VERSION ""

NS_ :

BS_:

BU_: AHCP APM BPCM EAC EBCM ECM ESC HCP OBCM ORC RHSC2

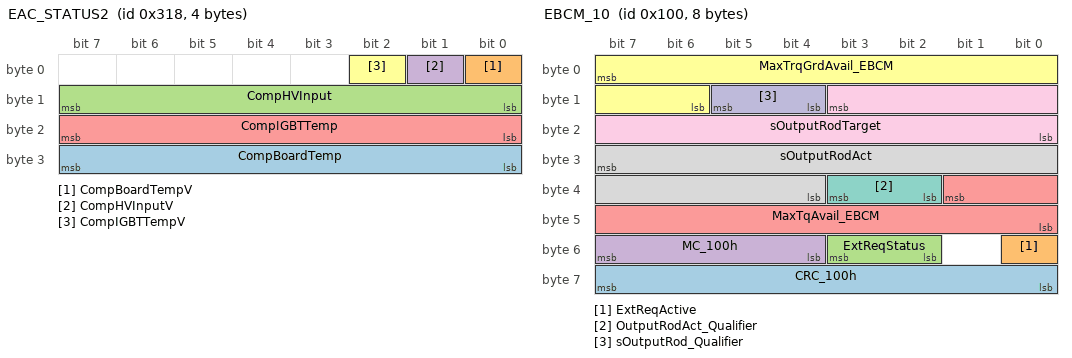
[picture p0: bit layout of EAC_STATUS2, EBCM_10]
BO_ 792 EAC_STATUS2: 4 EAC
 SG_ CompBoardTemp : 24|8@1+ (1,-40) [-40|214] "°C"  HCP
 SG_ CompBoardTempV : 0|1@1+ (1,0) [0|0] ""  HCP
 SG_ CompHVInput : 8|8@1+ (4,0) [0|1016] "Volts"  HCP
 SG_ CompHVInputV : 1|1@1+ (1,0) [0|0] ""  HCP
 SG_ CompIGBTTemp : 16|8@1+ (1,-40) [-40|214] "°C"  HCP
 SG_ CompIGBTTempV : 2|1@1+ (1,0) [0|0] ""  HCP

BO_ 256 EBCM_10: 8 EBCM
 SG_ CRC_100h : 56|8@1+ (1,0) [0|255] ""  ESC
 SG_ ExtReqActive : 48|1@1+ (1,0) [0|0] ""  ESC
 SG_ ExtReqStatus : 50|2@1+ (1,0) [0|0] ""  ESC
 SG_ MC_100h : 52|4@1+ (1,1) [1|15] ""  ESC
 SG_ MaxTqAvail_EBCM : 33|10@0+ (64,-65472) [-65472|0] ""  ESC
 SG_ MaxTrqGrdAvail_EBCM : 7|10@0+ (64,0) [0|65472] ""  ESC
 SG_ OutputRodAct_Qualifier : 34|2@1+ (1,0) [0|0] ""  ESC
 SG_ sOutputRodAct : 31|12@0+ (0.015625,-5) [-5|47] "mm"  ESC
 SG_ sOutputRodTarget : 11|12@0+ (0.015625,-5) [-5|47] "mm"  ESC
 SG_ sOutputRod_Qualifier : 12|2@1+ (1,0) [0|0] ""  ESC

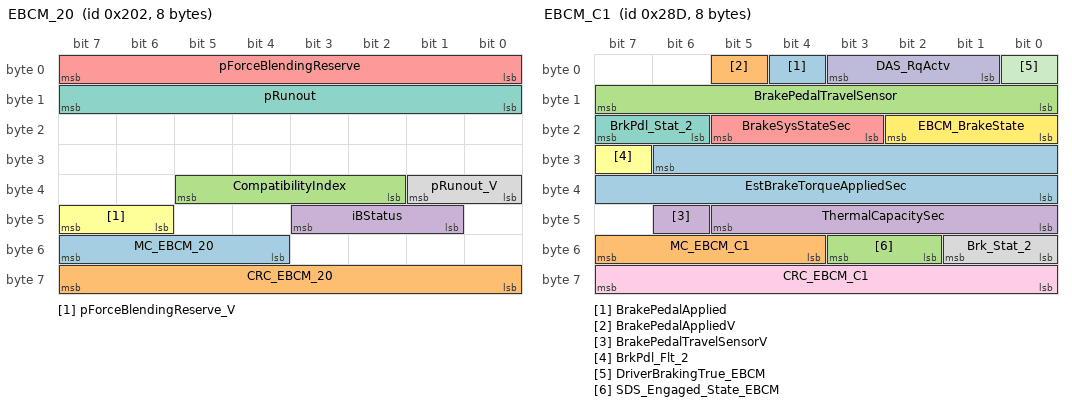
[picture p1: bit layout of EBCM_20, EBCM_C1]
BO_ 514 EBCM_20: 8 EBCM
 SG_ MC_EBCM_20 : 52|4@1+ (1,0) [0|15] ""  ESC
 SG_ CRC_EBCM_20 : 56|8@1+ (1,0) [0|255] ""  ESC
 SG_ CompatibilityIndex : 34|4@1+ (1,0) [0|0] ""  ESC
 SG_ iBStatus : 41|3@1+ (1,0) [0|0] ""  ESC
 SG_ pForceBlendingReserve : 0|8@1+ (0.5,0) [0|100] "bar"  ESC
 SG_ pForceBlendingReserve_V : 46|2@1+ (1,0) [0|0] ""  ESC
 SG_ pRunout : 8|8@1+ (1,0) [0|250] "bar"  ESC
 SG_ pRunout_V : 32|2@1+ (1,0) [0|0] ""  ESC

BO_ 653 EBCM_C1: 8 EBCM
 SG_ BrakePedalApplied : 4|1@1+ (1,0) [0|0] ""  RHSC2
 SG_ BrakePedalAppliedV : 5|1@1+ (1,0) [0|0] ""  RHSC2
 SG_ BrakePedalTravelSensor : 8|8@1+ (0.4,0) [0|100] "%"  RHSC2
 SG_ BrakePedalTravelSensorV : 46|1@1+ (1,0) [0|0] ""  RHSC2
 SG_ BrakeSysStateSec : 19|3@1+ (1,0) [0|0] ""  ESC,RHSC2
 SG_ BrkPdl_Flt_2 : 31|1@1+ (1,0) [0|0] ""  RHSC2
 SG_ BrkPdl_Stat_2 : 22|2@1+ (1,0) [0|0] ""  RHSC2
 SG_ Brk_Stat_2 : 48|2@1+ (1,0) [0|0] ""  RHSC2
 SG_ CRC_EBCM_C1 : 56|8@1+ (1,0) [0|0] ""  ESC,RHSC2
 SG_ DAS_RqActv : 1|3@1+ (1,0) [0|0] ""  RHSC2
 SG_ DriverBrakingTrue_EBCM : 0|1@1+ (1,0) [0|0] ""  ESC,RHSC2
 SG_ EBCM_BrakeState : 16|3@1+ (1,0) [0|0] ""  ESC,RHSC2
 SG_ EstBrakeTorqueAppliedSec : 30|15@0+ (2,-65534) [-65534|0] "Nm"  RHSC2
 SG_ MC_EBCM_C1 : 52|4@1+ (1,0) [0|15] ""  ESC,RHSC2
 SG_ SDS_Engaged_State_EBCM : 50|2@1+ (1,0) [0|0] ""  RHSC2
 SG_ ThermalCapacitySec : 40|6@1+ (1.5873,0) [0|100] "%"  RHSC2

BO_ 257 ECM_OBD_ePT: 3 ECM
 SG_ AccelPdlPosn_OBD_ePT : 16|8@1+ (0.3922,0) [0|100] "%"  BPCM,HCP
 SG_ EngLoad_OBD_ePT : 8|8@1+ (0.3922,0) [0|100] "%"  BPCM,HCP

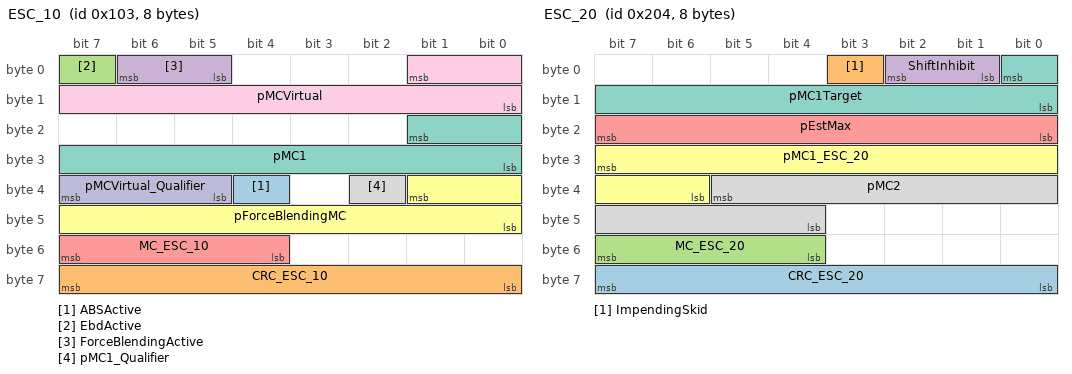
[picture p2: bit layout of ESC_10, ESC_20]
BO_ 259 ESC_10: 8 ESC
 SG_ ABSActive : 36|1@1+ (1,0) [0|0] ""  EBCM
 SG_ CRC_ESC_10 : 56|8@1+ (1,0) [0|255] ""  EBCM
 SG_ EbdActive : 7|1@1+ (1,0) [0|0] ""  EBCM
 SG_ ForceBlendingActive : 5|2@1+ (1,0) [0|0] ""  EBCM
 SG_ MC_ESC_10 : 52|4@1+ (1,1) [1|15] ""  EBCM
 SG_ pForceBlendingMC : 33|10@0+ (0.25,0) [0|255.75] "bar"  EBCM
 SG_ pMC1 : 17|10@0+ (0.3,0) [0|276.6] "bar"  EBCM
 SG_ pMC1_Qualifier : 34|1@1+ (1,0) [0|0] ""  EBCM
 SG_ pMCVirtual : 1|10@0+ (0.25,0) [0|255.75] "bar"  EBCM
 SG_ pMCVirtual_Qualifier : 37|3@1+ (1,0) [0|0] ""  EBCM

BO_ 516 ESC_20: 8 ESC
 SG_ CRC_ESC_20 : 56|8@1+ (1,0) [0|0] ""  EBCM,RHSC2
 SG_ ImpendingSkid : 3|1@1+ (1,0) [0|0] ""  ECM,HCP
 SG_ MC_ESC_20 : 52|4@1+ (1,0) [0|15] ""  EBCM,RHSC2
 SG_ ShiftInhibit : 1|2@1+ (1,0) [0|0] "" Vector__XXX
 SG_ pEstMax : 16|8@1+ (1,0) [0|250] "bar"  EBCM
 SG_ pMC1_ESC_20 : 31|10@0+ (0.3,0) [0|276.6] "bar"  EBCM,RHSC2
 SG_ pMC1Target : 0|9@0+ (0.5,0) [0|250] "bar"  RHSC2
 SG_ pMC2 : 37|10@0+ (0.3,0) [0|276.6] "bar"  RHSC2

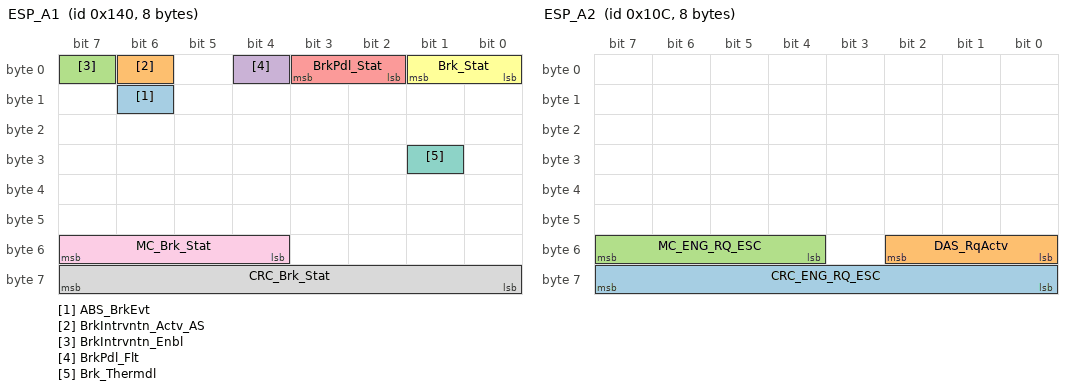
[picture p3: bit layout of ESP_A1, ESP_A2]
BO_ 320 ESP_A1: 8 ESC
 SG_ ABS_BrkEvt : 14|1@1+ (1,0) [0|0] ""  RHSC2
 SG_ BrkIntrvntn_Actv_AS : 6|1@1+ (1,0) [0|0] ""  RHSC2
 SG_ BrkIntrvntn_Enbl : 7|1@1+ (1,0) [0|0] ""  RHSC2
 SG_ BrkPdl_Flt : 4|1@1+ (1,0) [0|0] ""  RHSC2
 SG_ BrkPdl_Stat : 2|2@1+ (1,0) [0|0] ""  RHSC2
 SG_ Brk_Stat : 0|2@1+ (1,0) [0|0] ""  RHSC2
 SG_ Brk_Thermdl : 25|1@1+ (1,0) [0|0] ""  RHSC2
 SG_ CRC_Brk_Stat : 56|8@1+ (1,0) [0|0] ""  RHSC2
 SG_ MC_Brk_Stat : 52|4@1+ (1,0) [0|15] ""  RHSC2

BO_ 268 ESP_A2: 8 ESC
 SG_ CRC_ENG_RQ_ESC : 56|8@1+ (1,0) [0|0] ""  RHSC2
 SG_ DAS_RqActv : 48|3@1+ (1,0) [0|0] ""  RHSC2
 SG_ MC_ENG_RQ_ESC : 52|4@1+ (1,0) [0|15] ""  RHSC2

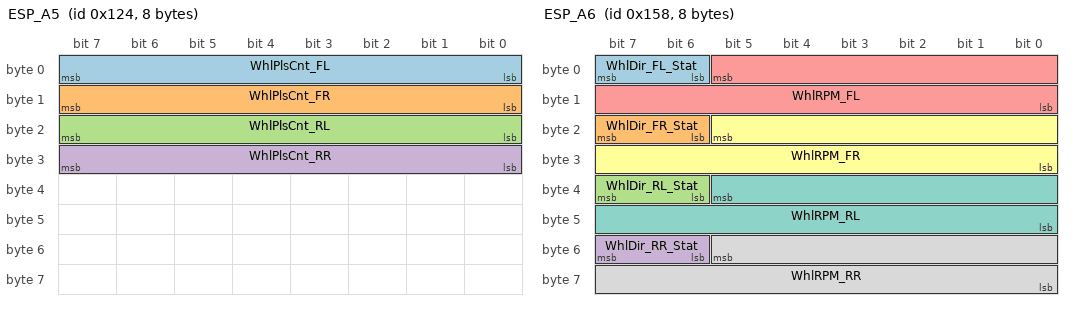
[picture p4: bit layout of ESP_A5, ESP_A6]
BO_ 292 ESP_A5: 8 ESC
 SG_ WhlPlsCnt_FL : 0|8@1+ (1,0) [0|254] "Impulse"  RHSC2
 SG_ WhlPlsCnt_FR : 8|8@1+ (1,0) [0|254] "Impulse"  RHSC2
 SG_ WhlPlsCnt_RL : 16|8@1+ (1,0) [0|254] "Impulse"  RHSC2
 SG_ WhlPlsCnt_RR : 24|8@1+ (1,0) [0|254] "Impulse"  RHSC2

BO_ 344 ESP_A6: 8 ESC
 SG_ WhlDir_FL_Stat : 6|2@1+ (1,0) [0|0] ""  RHSC2
 SG_ WhlDir_FR_Stat : 22|2@1+ (1,0) [0|0] ""  RHSC2
 SG_ WhlDir_RL_Stat : 38|2@1+ (1,0) [0|0] ""  RHSC2
 SG_ WhlDir_RR_Stat : 54|2@1+ (1,0) [0|0] ""  RHSC2
 SG_ WhlRPM_FL : 5|14@0+ (0.5,0) [0|8191] "rpm"  RHSC2
 SG_ WhlRPM_FR : 21|14@0+ (0.5,0) [0|8191] "rpm"  RHSC2
 SG_ WhlRPM_RL : 37|14@0+ (0.5,0) [0|8191] "rpm"  RHSC2
 SG_ WhlRPM_RR : 53|14@0+ (0.5,0) [0|8191] "rpm"  RHSC2

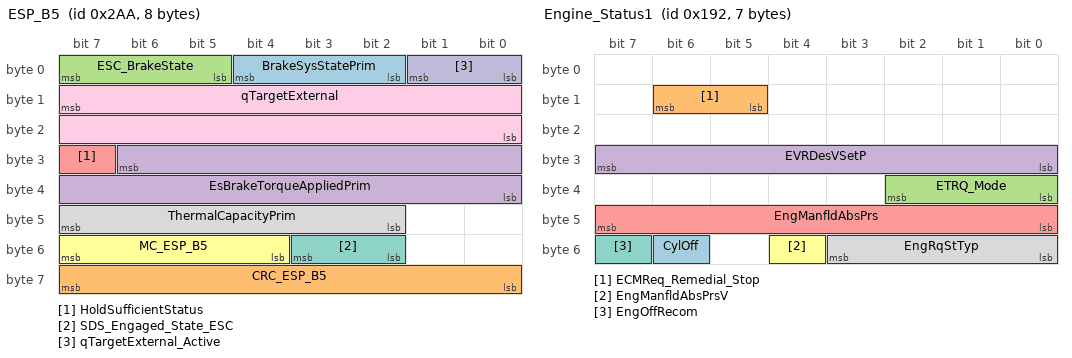
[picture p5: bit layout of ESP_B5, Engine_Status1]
BO_ 682 ESP_B5: 8 ESC
 SG_ BrakeSysStatePrim : 2|3@1+ (1,0) [0|0] ""  EBCM,RHSC2
 SG_ CRC_ESP_B5 : 56|8@1+ (1,0) [0|0] ""  EBCM,RHSC2
 SG_ ESC_BrakeState : 5|3@1+ (1,0) [0|0] ""  EBCM,RHSC2
 SG_ EsBrakeTorqueAppliedPrim : 30|15@0+ (2,-65534) [-65534|0] "Nm"  RHSC2
 SG_ HoldSufficientStatus : 31|1@1+ (1,0) [0|0] ""  RHSC2
 SG_ MC_ESP_B5 : 52|4@1+ (1,0) [0|15] ""  EBCM,RHSC2
 SG_ SDS_Engaged_State_ESC : 50|2@1+ (1,0) [0|0] ""  RHSC2
 SG_ ThermalCapacityPrim : 42|6@1+ (1.5873,0) [0|99.9999] "%"  RHSC2
 SG_ qTargetExternal : 15|16@0+ (0.0078125,-252) [-252|252] "ml/sec"  EBCM,RHSC2
 SG_ qTargetExternal_Active : 0|2@1+ (1,0) [0|0] ""  EBCM,RHSC2

BO_ 402 Engine_Status1: 7 ECM
 SG_ CylOff : 54|1@1+ (1,0) [0|0] ""  HCP
 SG_ ECMReq_Remedial_Stop : 13|2@1+ (1,0) [0|0] ""  HCP
 SG_ ETRQ_Mode : 32|3@1+ (1,0) [0|5] ""  HCP
 SG_ EVRDesVSetP : 24|8@1+ (0.0625,0) [0|15.875] "V"  HCP
 SG_ EngManfldAbsPrs : 40|8@1+ (0.5,0) [0|127.5] "kPa"  HCP
 SG_ EngManfldAbsPrsV : 52|1@1+ (1,0) [0|0] ""  HCP
 SG_ EngOffRecom : 55|1@1+ (1,0) [0|0] ""  HCP
 SG_ EngRqStTyp : 48|4@1+ (1,0) [0|0] ""  HCP

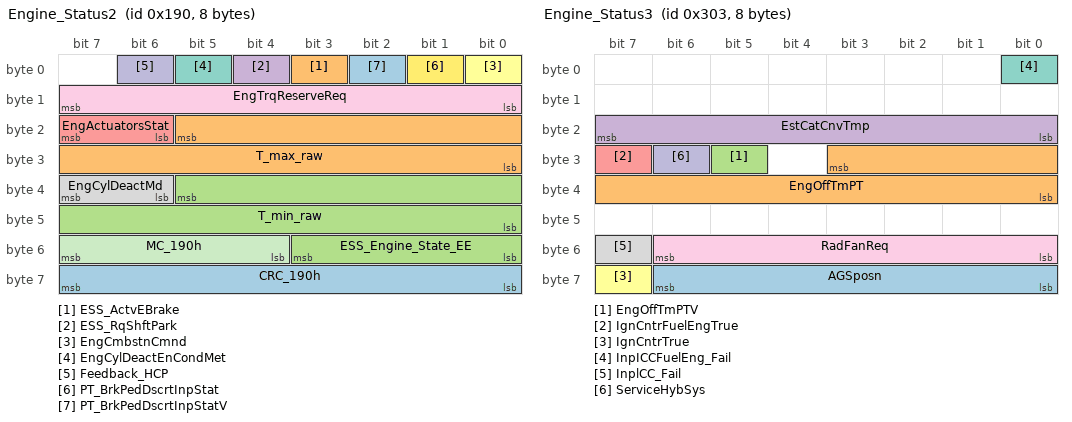
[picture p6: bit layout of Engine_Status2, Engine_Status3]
BO_ 400 Engine_Status2: 8 ECM
 SG_ CRC_190h : 56|8@1+ (1,0) [0|0] ""  HCP
 SG_ ESS_ActvEBrake : 3|1@1+ (1,0) [0|0] ""  HCP
 SG_ ESS_Engine_State_EE : 48|4@1+ (1,0) [0|0] ""  HCP
 SG_ ESS_RqShftPark : 4|1@1+ (1,0) [0|0] ""  HCP
 SG_ EngActuatorsStat : 22|2@1+ (1,0) [0|0] ""  HCP
 SG_ EngCmbstnCmnd : 0|1@1+ (1,0) [0|0] ""  HCP
 SG_ EngCylDeactEnCondMet : 5|1@1+ (1,0) [0|0] ""  HCP
 SG_ EngCylDeactMd : 38|2@1+ (1,0) [0|0] ""  HCP
 SG_ EngTrqReserveReq : 8|8@1+ (0.32,0) [0|81.28] "Nm"  HCP
 SG_ Feedback_HCP : 6|1@1+ (1,0) [0|0] ""  HCP
 SG_ MC_190h : 52|4@1+ (1,0) [0|15] ""  HCP
 SG_ PT_BrkPedDscrtInpStat : 1|1@1+ (1,0) [0|0] ""  HCP
 SG_ PT_BrkPedDscrtInpStatV : 2|1@1+ (1,0) [0|0] ""  HCP
 SG_ T_max_raw : 21|14@0+ (1.5625,-4604.688) [-4604.688|20970.3125] "Nm"  HCP
 SG_ T_min_raw : 37|14@0+ (1.5625,-4604.688) [-4604.688|20970.3125] "Nm"  HCP

BO_ 771 Engine_Status3: 8 ECM
 SG_ AGSposn : 56|7@1+ (1,0) [0|100] "%"  ESC,HCP
 SG_ EngOffTmPT : 27|12@0+ (0.5,0) [0.5|2047.5] "min"  HCP
 SG_ EngOffTmPTV : 29|1@1+ (1,0) [0|0] ""  HCP
 SG_ EstCatCnvTmp : 16|8@1+ (5,0) [0|1270] "°C"  HCP
 SG_ IgnCntrFuelEngTrue : 31|1@1+ (1,0) [0|0] ""  BPCM,HCP
 SG_ IgnCntrTrue : 63|1@1+ (1,0) [0|0] ""  BPCM,HCP
 SG_ InpICCFuelEng_Fail : 0|1@1+ (1,0) [0|0] ""  BPCM,HCP
 SG_ InplCC_Fail : 55|1@1+ (1,0) [0|0] ""  BPCM,HCP
 SG_ RadFanReq : 48|7@1+ (1,0) [0|100] "%"  ESC,HCP
 SG_ ServiceHybSys : 30|1@1+ (1,0) [0|0] ""  HCP

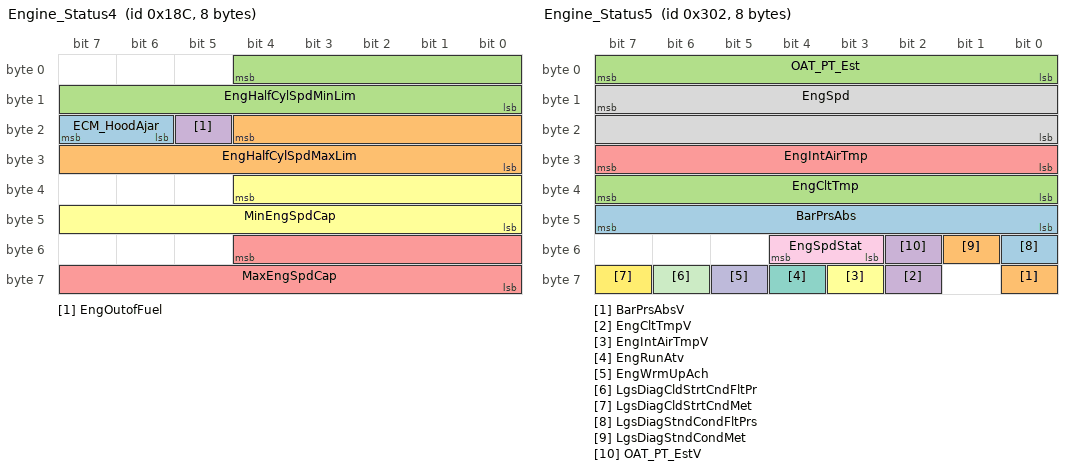
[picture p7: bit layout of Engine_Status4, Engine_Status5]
BO_ 396 Engine_Status4: 8 ECM
 SG_ ECM_HoodAjar : 22|2@1+ (1,0) [0|3] ""  HCP
 SG_ EngHalfCylSpdMaxLim : 20|13@0+ (1,0) [0|8160] "rpm"  HCP
 SG_ EngHalfCylSpdMinLim : 4|13@0+ (1,0) [0|8160] "rpm"  HCP
 SG_ EngOutofFuel : 21|1@1+ (1,0) [0|0] ""  HCP
 SG_ MaxEngSpdCap : 52|13@0+ (1,0) [0|8160] "rpm"  HCP
 SG_ MinEngSpdCap : 36|13@0+ (1,0) [0|8160] "rpm"  HCP

BO_ 770 Engine_Status5: 8 ECM
 SG_ BarPrsAbs : 40|8@1+ (0.5,0) [0|127.5] "kPa"  BPCM,HCP
 SG_ BarPrsAbsV : 56|1@1+ (1,0) [0|0] ""  HCP
 SG_ EngCltTmp : 32|8@1+ (1,-40) [-40|214] "°C"  BPCM,EBCM,ESC,HCP
 SG_ EngCltTmpV : 58|1@1+ (1,0) [0|0] ""  HCP
 SG_ EngIntAirTmp : 24|8@1+ (1,-40) [-40|214] "°C"  BPCM,HCP
 SG_ EngIntAirTmpV : 59|1@1+ (1,0) [0|0] ""  HCP
 SG_ EngRunAtv : 60|1@1+ (1,0) [0|0] ""  HCP
 SG_ EngSpd : 15|16@0+ (0.125,0) [0|8160] "rpm"  BPCM,HCP
 SG_ EngSpdStat : 51|2@1+ (1,0) [0|0] ""  HCP
 SG_ EngWrmUpAch : 61|1@1+ (1,0) [0|0] ""  BPCM,EBCM,ESC,HCP
 SG_ LgsDiagCldStrtCndFltPr : 62|1@1+ (1,0) [0|0] ""  BPCM,HCP
 SG_ LgsDiagCldStrtCndMet : 63|1@1+ (1,0) [0|0] ""  BPCM,HCP
 SG_ LgsDiagStndCondFltPrs : 48|1@1+ (1,0) [0|0] ""  BPCM,HCP
 SG_ LgsDiagStndCondMet : 49|1@1+ (1,0) [0|0] ""  BPCM,HCP
 SG_ OAT_PT_Est : 0|8@1+ (1,-64) [-64|191] "°C"  BPCM,HCP
 SG_ OAT_PT_EstV : 50|1@1+ (1,0) [0|0] ""  HCP

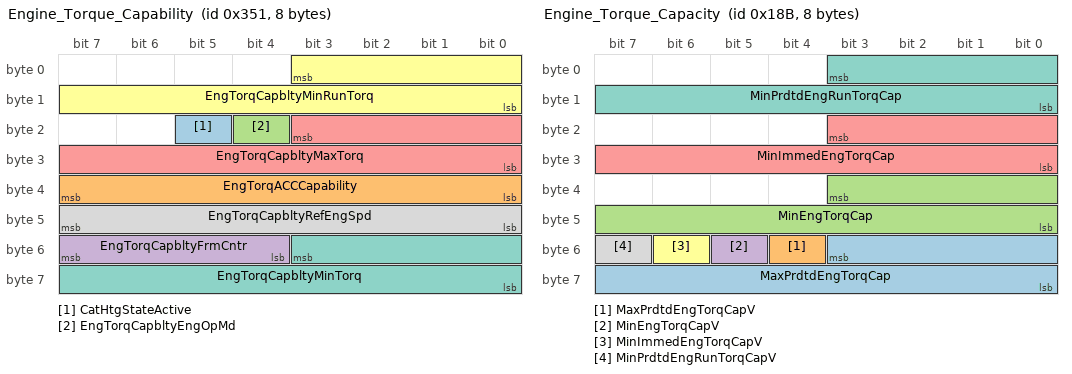
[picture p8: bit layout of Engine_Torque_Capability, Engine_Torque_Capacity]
BO_ 849 Engine_Torque_Capability: 8 ECM
 SG_ CatHtgStateActive : 21|1@1+ (1,0) [0|0] ""  HCP
 SG_ EngTorqACCCapability : 32|8@1+ (0.32,0) [0|81.28] "Nm"  HCP
 SG_ EngTorqCapbltyEngOpMd : 20|1@1+ (1,0) [0|0] ""  HCP
 SG_ EngTorqCapbltyFrmCntr : 52|4@1+ (1,0) [0|15] ""  HCP
 SG_ EngTorqCapbltyMaxTorq : 19|12@0+ (0.32,-300.16) [-300.16|1008] "Nm"  HCP
 SG_ EngTorqCapbltyMinRunTorq : 3|12@0+ (0.32,-300.16) [-300.16|1008] "Nm"  HCP
 SG_ EngTorqCapbltyMinTorq : 51|12@0+ (0.32,-300.16) [-300.16|1008] "Nm"  HCP
 SG_ EngTorqCapbltyRefEngSpd : 40|8@1+ (32,0) [0|8160] "rpm"  HCP

BO_ 395 Engine_Torque_Capacity: 8 ECM
 SG_ MaxPrdtdEngTorqCap : 51|12@0+ (0.32,-300.16) [-300.16|1008] "Nm"  HCP
 SG_ MaxPrdtdEngTorqCapV : 52|1@1+ (1,0) [0|0] ""  HCP
 SG_ MinEngTorqCap : 35|12@0+ (0.32,-300.16) [-300.16|1008] "Nm"  HCP
 SG_ MinEngTorqCapV : 53|1@1+ (1,0) [0|0] ""  HCP
 SG_ MinImmedEngTorqCap : 19|12@0+ (0.32,-300.16) [-300.16|1008] "Nm"  HCP
 SG_ MinImmedEngTorqCapV : 54|1@1+ (1,0) [0|0] ""  HCP
 SG_ MinPrdtdEngRunTorqCap : 3|12@0+ (0.32,-300.16) [-300.16|1008] "Nm"  HCP
 SG_ MinPrdtdEngRunTorqCapV : 55|1@1+ (1,0) [0|0] ""  HCP

BO_ 401 Engine_Torque_Status: 8 ECM
 SG_ AccPos : 0|8@1+ (0.392157,0) [0|100] "%"  HCP
 SG_ AccPosV : 36|1@1+ (1,0) [0|0] ""  HCP
 SG_ CRC_191h : 56|8@1+ (1,0) [0|0] ""  HCP
 SG_ ECM_IMMO_STAT_CANePT : 48|2@1+ (1,0) [0|0] ""  HCP
 SG_ EngActStdyStTorq : 35|12@0+ (0.32,-300.16) [-300.16|1008] "Nm"  HCP
 SG_ EngActStdyStTorqV : 37|1@1+ (1,0) [0|0] ""  HCP
 SG_ EngAirFlwStdyStTorq : 19|12@0+ (0.32,-300.16) [-300.16|1008] "Nm"  HCP
 SG_ EngAirFlwStdyStTorqV : 8|1@1+ (1,0) [0|0] ""  HCP
 SG_ EngDFCO_Allw : 9|1@1+ (1,0) [0|0] ""  HCP
 SG_ EngDFCO_Req : 20|1@1+ (1,0) [0|0] ""  HCP
 SG_ EngDFCO_St : 21|1@1+ (1,0) [0|0] ""  HCP
 SG_ EngRunCrnkAct : 22|1@1+ (1,0) [0|0] ""  HCP
 SG_ HybActEngTorqRespTyp : 50|2@1+ (1,0) [0|0] ""  HCP
 SG_ MC_191h : 52|4@1+ (1,0) [0|15] ""  HCP
 SG_ PTCrnkAbrted : 39|1@1+ (1,0) [0|0] ""  HCP
 SG_ PT_CrnkAct : 23|1@1+ (1,0) [0|0] ""  HCP
 SG_ TLC_LRN_Rq : 38|1@1+ (1,0) [0|0] ""  HCP

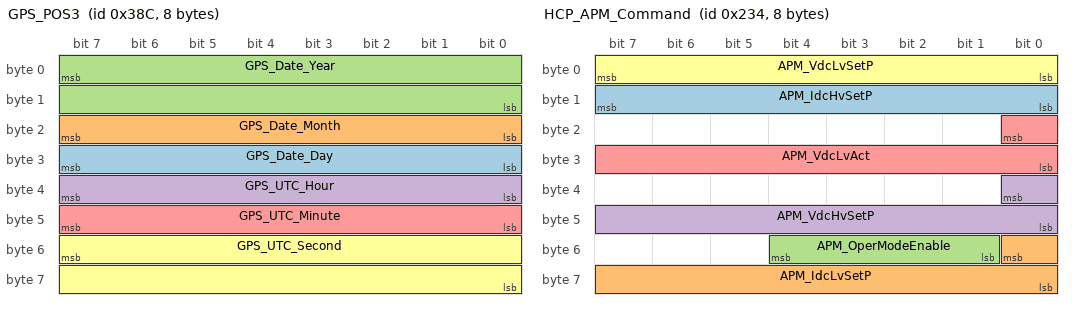
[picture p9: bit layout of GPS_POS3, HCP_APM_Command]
BO_ 908 GPS_POS3: 8 HCP
 SG_ GPS_Date_Day : 24|8@1+ (1,0) [1|31] "Days"  APM,BPCM,OBCM
 SG_ GPS_Date_Month : 16|8@1+ (1,0) [1|12] "Months"  APM,BPCM,OBCM
 SG_ GPS_Date_Year : 7|16@0+ (1,0) [0|65534] "Years"  APM,BPCM,OBCM
 SG_ GPS_UTC_Hour : 32|8@1+ (1,0) [0|23] "h"  APM,BPCM,OBCM
 SG_ GPS_UTC_Minute : 40|8@1+ (1,0) [0|59] "min"  APM,BPCM,OBCM
 SG_ GPS_UTC_Second : 55|16@0+ (0.01,0) [0|59.99] "s"  APM,BPCM,OBCM

BO_ 564 HCP_APM_Command: 8 HCP
 SG_ APM_IdcHvSetP : 8|8@1+ (1,-125) [-125|129] "Amp"  APM
 SG_ APM_IdcLvSetP : 48|9@0+ (1,-255) [-255|255] "Amp"  APM
 SG_ APM_OperModeEnable : 49|4@1+ (1,0) [0|0] ""  APM
 SG_ APM_VdcHvSetP : 32|9@0+ (1,0) [0|510] "V"  APM
 SG_ APM_VdcLvAct : 16|9@0+ (0.04,0) [0|20.04] "V"  APM
 SG_ APM_VdcLvSetP : 0|8@1+ (0.0625,0) [0|15.875] "V"  APM

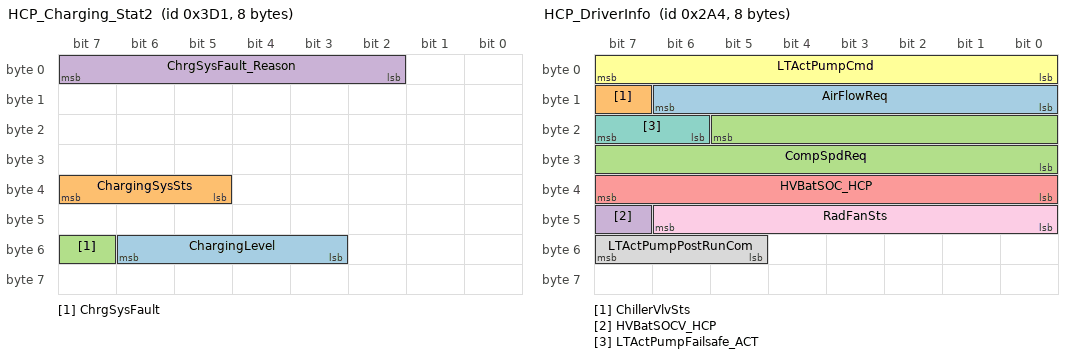
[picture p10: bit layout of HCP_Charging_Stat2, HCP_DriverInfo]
BO_ 977 HCP_Charging_Stat2: 8 HCP
 SG_ ChargingLevel : 51|4@1+ (1,0) [0|0] ""  BPCM
 SG_ ChargingSysSts : 37|3@1+ (1,0) [0|0] ""  BPCM
 SG_ ChrgSysFault : 55|1@1+ (1,0) [0|0] ""  BPCM
 SG_ ChrgSysFault_Reason : 2|6@1+ (1,0) [0|0] ""  OBCM

BO_ 676 HCP_DriverInfo: 8 HCP
 SG_ AirFlowReq : 8|7@1+ (1,0) [0|100] "%"  ECM
 SG_ ChillerVlvSts : 15|1@1+ (1,0) [0|0] ""  ECM
 SG_ CompSpdReq : 21|14@0+ (1,0) [0|16382] "rpm"  EAC
 SG_ HVBatSOCV_HCP : 47|1@1+ (1,0) [0|0] ""  BPCM
 SG_ HVBatSOC_HCP : 32|8@1+ (0.3922,0) [0|100] "%"  BPCM
 SG_ LTActPumpCmd : 0|8@1+ (28,0) [0|7000] "rpm"  BPCM
 SG_ LTActPumpFailsafe_ACT : 22|2@1+ (1,0) [0|0] ""  BPCM
 SG_ LTActPumpPostRunCom : 53|3@1+ (1,0) [0|0] ""  BPCM
 SG_ RadFanSts : 40|7@1+ (1,0) [0|100] "%"  ECM

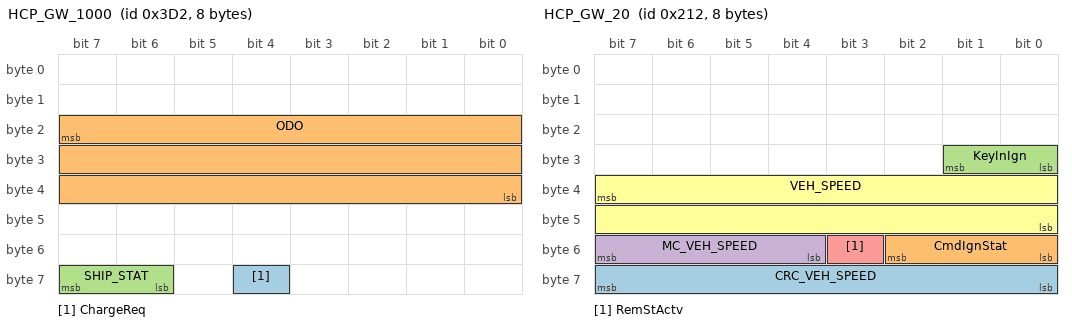
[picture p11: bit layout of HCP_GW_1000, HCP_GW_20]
BO_ 978 HCP_GW_1000: 8 HCP
 SG_ ChargeReq : 60|1@1+ (1,0) [0|0] ""  BPCM
 SG_ ODO : 23|24@0+ (0.1,0) [0|1677721.4] "km"  AHCP,APM,BPCM,EAC,OBCM
 SG_ SHIP_STAT : 62|2@1+ (1,0) [0|0] ""  BPCM

BO_ 530 HCP_GW_20: 8 HCP
 SG_ CRC_VEH_SPEED : 56|8@1+ (1,0) [0|0] ""  BPCM
 SG_ CmdIgnStat : 48|3@1+ (1,0) [0|0] ""  AHCP,APM,BPCM,EAC,OBCM
 SG_ KeyInIgn : 24|2@1+ (1,0) [0|0] "" Vector__XXX
 SG_ MC_VEH_SPEED : 52|4@1+ (1,0) [0|15] ""  BPCM
 SG_ RemStActv : 51|1@1+ (1,0) [0|0] "" Vector__XXX
 SG_ VEH_SPEED : 39|16@0+ (0.0078125,0) [0|511.984375] "km/h"  AHCP,APM,BPCM,EAC,OBCM

CM_ SG_ 792 CompBoardTemp "CompBoardTemp";
CM_ SG_ 792 CompBoardTempV "compressor current valid";
CM_ SG_ 792 CompHVInput "CompHVInput";
CM_ SG_ 792 CompHVInputV "compressor current valid";
CM_ SG_ 792 CompIGBTTemp "CompIGBTTemp";
CM_ SG_ 792 CompIGBTTempV "CompIGBTTempV";
CM_ SG_ 256 CRC_100h "CRC";
CM_ SG_ 256 ExtReqActive "Driver request or external brake request is dominating; EBR exceed driver brake torque = [1]";
CM_ SG_ 256 ExtReqStatus "indicating status of external brake request (EBR) function";
CM_ SG_ 256 MC_100h "Message counter";
CM_ SG_ 256 OutputRodAct_Qualifier "Signal quality of sOuputRodAct";
CM_ SG_ 256 sOutputRodAct "Actual output rod movement";
CM_ SG_ 256 sOutputRodTarget "Travel of output rod in iBooster";
CM_ SG_ 256 sOutputRod_Qualifier "Information about the signal quality of sOutputRod";
CM_ SG_ 514 CompatibilityIndex "Index of EBCM software";
CM_ SG_ 514 iBStatus "Current Status of the iBooster";
CM_ SG_ 514 pForceBlendingReserve "Maximum brake pressure";
CM_ SG_ 514 pForceBlendingReserve_V "Maximum delta pressure simulated by ForceBlending validity bit";
CM_ SG_ 514 pRunout "In driver braking: maximum achievable master cylinder pressure with boost (runout.)";
CM_ SG_ 514 pRunout_V "In driver braking validity bit";
CM_ SG_ 653 BrakePedalApplied "driver operates the brake pedal";
CM_ SG_ 653 BrakePedalAppliedV "Validity bit";
CM_ SG_ 653 BrakePedalTravelSensor "Brake pedal travel sensor 0-100% (0 = upstop)";
CM_ SG_ 653 BrakePedalTravelSensorV "Brake pedal travel sensor valid (1 = valid data)";
CM_ SG_ 653 BrakeSysStateSec "EBCM Brake State from Secondary actuator";
CM_ SG_ 653 BrkPdl_Flt_2 "Brake pedal fault is active; True = [1]";
CM_ SG_ 653 BrkPdl_Stat_2 "Brake pedal state";
CM_ SG_ 653 Brk_Stat_2 "Brake state";
CM_ SG_ 653 CRC_EBCM_C1 "CRC-checksum byte 1 to 7 according to SAE J1850";
CM_ SG_ 653 DAS_RqActv "DAS request active";
CM_ SG_ 653 DriverBrakingTrue_EBCM "Driver operates the brake pedal; Pressed = [1]";
CM_ SG_ 653 EBCM_BrakeState "EBCM Brake State";
CM_ SG_ 653 MC_EBCM_C1 "Message counter";
CM_ SG_ 653 SDS_Engaged_State_EBCM "SDS Engaged Status";
CM_ SG_ 257 AccelPdlPosn_OBD_ePT "Pedal value for OBD (ISO 15031-5.4 PID 49)";
CM_ SG_ 257 EngLoad_OBD_ePT "Load value for OBD (ISO 15031-5.4 PID 4)";
CM_ SG_ 259 ABSActive "ESP return pump is active, Flag is set 1";
CM_ SG_ 259 CRC_ESC_10 "CRC";
CM_ SG_ 259 ForceBlendingActive "Status of force-blending interface";
CM_ SG_ 259 MC_ESC_10 "Message counter";
CM_ SG_ 259 pForceBlendingMC "Master Cylinder pressure used by force blending function";
CM_ SG_ 259 pMC1 "Current pressure of the master cylinder pressure sensor in the ESP";
CM_ SG_ 259 pMC1_Qualifier "Information about signal quality of pMC1. 0 - Signal Valid; 1 - Signal Invalid";
CM_ SG_ 259 pMCVirtual "Virtual master cylinder pressure determined in ESP from boost body position of iBooster";
CM_ SG_ 259 pMCVirtual_Qualifier "Qualifier for virtual master cylinder pressure";
CM_ SG_ 516 CRC_ESC_20 "CRC-checksum byte 1 to 7 according to SAE J1850";
CM_ SG_ 516 ImpendingSkid "Impending Skid; impending skid false = [0], impending skid true = [1]";
CM_ SG_ 516 MC_ESC_20 "Message counter";
CM_ SG_ 516 ShiftInhibit "Shift Inhibit Request";
CM_ SG_ 516 pEstMax "Maximum of the estimated wheel pressures.";
CM_ SG_ 516 pMC1_ESC_20 "Current pressure of the master cylinder pressure sensor in the ESP";
CM_ SG_ 516 pMC1Target "ESC modeled pressure";
CM_ SG_ 516 pMC2 "Current pressure of the master cylinder pressure sensor in the ESP";
CM_ SG_ 320 ABS_BrkEvt "Any ABS brake event";
CM_ SG_ 320 BrkIntrvntn_Actv_AS "Brake intervention by assistance system active";
CM_ SG_ 320 BrkIntrvntn_Enbl "Brake intervention enabled";
CM_ SG_ 320 BrkPdl_Flt "Brake Pedal Fault is active, 1=Faulted";
CM_ SG_ 320 BrkPdl_Stat "Brake pedal state";
CM_ SG_ 320 Brk_Stat "Brake state";
CM_ SG_ 320 Brk_Thermdl "Brake thermal over target";
CM_ SG_ 320 CRC_Brk_Stat "CRC-checksum byte 1 to 7 according to SAE J1850";
CM_ SG_ 320 MC_Brk_Stat "Message counter";
CM_ SG_ 268 CRC_ENG_RQ_ESC "CRC-checksum byte 1 to 7 according to SAE J1850";
CM_ SG_ 268 DAS_RqActv "DAS request active";
CM_ SG_ 268 MC_ENG_RQ_ESC "Message counter";
CM_ SG_ 292 WhlPlsCnt_FL "Wheel pulse counter front left (96 per rotation)";
CM_ SG_ 292 WhlPlsCnt_FR "Wheel pulse counter front right (96 per rotation)";
CM_ SG_ 292 WhlPlsCnt_RL "Wheel pulse counter rear left (96 per rotation)";
CM_ SG_ 292 WhlPlsCnt_RR "Wheel pulse counter rear right (96 per rotation)";
CM_ SG_ 344 WhlDir_FL_Stat "Direction of rotation of front left wheel";
CM_ SG_ 344 WhlDir_FR_Stat "Direction of rotation of front right wheel";
CM_ SG_ 344 WhlDir_RL_Stat "Direction of rotation of rear left wheel";
CM_ SG_ 344 WhlDir_RR_Stat "Direction of rotation of rear right wheel";
CM_ SG_ 344 WhlRPM_FL "Wheel rpm front left";
CM_ SG_ 344 WhlRPM_FR "Wheel rpm front right";
CM_ SG_ 344 WhlRPM_RL "Wheel rpm rear left";
CM_ SG_ 344 WhlRPM_RR "Wheel rpm rear right";
CM_ SG_ 682 BrakeSysStatePrim "Brake System State from Primary actuator";
CM_ SG_ 682 CRC_ESP_B5 "CRC-checksum byte 1 to 7 according to SAE J1850";
CM_ SG_ 682 ESC_BrakeState "ESC Brake State";
CM_ SG_ 682 HoldSufficientStatus "1- Indicates ESC has sufficient torque, for RHSC to command release of park brake or move out of park. ";
CM_ SG_ 682 MC_ESP_B5 "Message counter";
CM_ SG_ 682 SDS_Engaged_State_ESC "SDS Engaged State";
CM_ SG_ 682 qTargetExternal "Target volume flow speed of the brake system to be applied by iBooster for EBR.";
CM_ SG_ 682 qTargetExternal_Active "Activates the external brake volume flow request when equal to 1";
CM_ SG_ 402 CylOff "Cylinder off due to misfire";
CM_ SG_ 402 ECMReq_Remedial_Stop "Engine Stop Request";
CM_ SG_ 402 ETRQ_Mode "Enumeration of combustion torque mode";
CM_ SG_ 402 EVRDesVSetP "Electronic Voltage Regulator Desired Voltage Set-Point.";
CM_ SG_ 402 EngManfldAbsPrs "Engine Manifold Absolute Pressure";
CM_ SG_ 402 EngManfldAbsPrsV "Engine manifold absolute pressure validity; Invalid = [1]";
CM_ SG_ 402 EngOffRecom "Engine off recommendation";
CM_ SG_ 402 EngRqStTyp "Engine requested start type";
CM_ SG_ 400 CRC_190h "CRC-checksum byte 1 to 7 according to SAE J1850";
CM_ SG_ 400 ESS_ActvEBrake "ESS active E-brake. 1 = Active, 0 = Inactive";
CM_ SG_ 400 ESS_Engine_State_EE "ESS Engine State";
CM_ SG_ 400 ESS_RqShftPark "ESS Request shift to Park.  1 = True, 0 = False";
CM_ SG_ 400 EngActuatorsStat "Engine Actuator Status for Autostop";
CM_ SG_ 400 EngCmbstnCmnd "Engine combustion commanded";
CM_ SG_ 400 EngCylDeactEnCondMet "Engine cylinder deactivation enable conditions met";
CM_ SG_ 400 EngCylDeactMd "Engine Cylinder Deactivation Mode";
CM_ SG_ 400 EngTrqReserveReq "Engine Torque Reserve Request";
CM_ SG_ 400 Feedback_HCP "Indication that the ECM is receiving valid data from the HCP. 0 - False; 1 - True.";
CM_ SG_ 400 MC_190h "Message counter";
CM_ SG_ 400 PT_BrkPedDscrtInpStat "Powertrain brake pedal discrete input status";
CM_ SG_ 400 PT_BrkPedDscrtInpStatV "Powertrain brake pedal discrete input status validity; Invalid = [1]";
CM_ SG_ 400 T_max_raw "Driver intended axle torque raw maximum";
CM_ SG_ 400 T_min_raw "Driver intended axle torque raw minimum";
CM_ SG_ 771 AGSposn ".";
CM_ SG_ 771 EngOffTmPT "Engine off time powertrain";
CM_ SG_ 771 EngOffTmPTV "Engine off time powertrain validity (1=invalid)";
CM_ SG_ 771 EstCatCnvTmp "Estimated catalytic converter temperature";
CM_ SG_ 771 IgnCntrFuelEngTrue "Second Ignition Cycle Counter";
CM_ SG_ 771 IgnCntrTrue "Ignition cycle counter is true [1]";
CM_ SG_ 771 InpICCFuelEng_Fail "Second Ignition Cycle Counter Fault Present";
CM_ SG_ 771 InplCC_Fail "Inputs to the Ign Cycle Cntr are in a Pend or MIL cond.";
CM_ SG_ 771 RadFanReq "Radiator Fan request";
CM_ SG_ 771 ServiceHybSys "Service Hybrid system; True = [1]";
CM_ SG_ 396 ECM_HoodAjar "Diagnosed hood status for HVIL.";
CM_ SG_ 396 EngHalfCylSpdMaxLim "Engine Half Cylinder Speed Maximum Limit";
CM_ SG_ 396 EngHalfCylSpdMinLim "Engine Half Cylinder Speed Minimum Limit";
CM_ SG_ 396 EngOutofFuel "Engine System Failed (limp home = 1)";
CM_ SG_ 396 MaxEngSpdCap "Maximum Engine Speed Capacity";
CM_ SG_ 396 MinEngSpdCap "Minimum Engine Speed Capacity";
CM_ SG_ 770 BarPrsAbs "Barometric pressure absolute";
CM_ SG_ 770 BarPrsAbsV "Barometric Pressure Absolute Validity; Invalid = [1]";
CM_ SG_ 770 EngCltTmp "Engine Coolant Temperature";
CM_ SG_ 770 EngCltTmpV "Engine Coolant Temperature Validity; Invalid = [1]";
CM_ SG_ 770 EngIntAirTmp "Engine Intake Air Temperature";
CM_ SG_ 770 EngIntAirTmpV "Engine Intake Air Temperature Validity; Invalid = [1]";
CM_ SG_ 770 EngRunAtv "Engine Run Active";
CM_ SG_ 770 EngSpd "Engine speed";
CM_ SG_ 770 EngSpdStat "Engine speed status";
CM_ SG_ 770 EngWrmUpAch "Engine warm up cycle achieved";
CM_ SG_ 770 LgsDiagCldStrtCndFltPr "Legislated diagnostics cold start conditions fault present; true = [1]";
CM_ SG_ 770 LgsDiagCldStrtCndMet "Legislated diagnostics cold start conditions met; true = [1]";
CM_ SG_ 770 LgsDiagStndCondFltPrs "Legislated diagnostics standard conditions fault present";
CM_ SG_ 770 LgsDiagStndCondMet "Legislated diagnostics standard conditions met";
CM_ SG_ 770 OAT_PT_Est "Outside air temperature powertrain estimated";
CM_ SG_ 770 OAT_PT_EstV "Outside air temperature powertrain estimated validity; Invalid = [1]";
CM_ SG_ 849 CatHtgStateActive "Catalysator Heating Status Request, 0- no request, 1 - request";
CM_ SG_ 849 EngTorqACCCapability "Eng Trq to be subtracted from the entire capability curve on the HCP side";
CM_ SG_ 849 EngTorqCapbltyEngOpMd "Engine operating mode [0] = non-MDS, [1] = MDS";
CM_ SG_ 849 EngTorqCapbltyFrmCntr "Engine Torque Capability: Frame Counter (4 bit)";
CM_ SG_ 849 EngTorqCapbltyMaxTorq "Engine torque capability: maximum torque";
CM_ SG_ 849 EngTorqCapbltyMinRunTorq "Engine torque capability: minimum run torque (fuel on)";
CM_ SG_ 849 EngTorqCapbltyMinTorq "Engine torque capability: minimum torque (fuel off)";
CM_ SG_ 849 EngTorqCapbltyRefEngSpd "Engine torque capability: reference engine speed";
CM_ SG_ 395 MaxPrdtdEngTorqCap "Maximum predicted engine torque capacity";
CM_ SG_ 395 MaxPrdtdEngTorqCapV "Maximum predicted engine torque capacity validity; Invalid = [1]";
CM_ SG_ 395 MinEngTorqCap "Minimum engine torque capacity (min air flow, fuel off)";
CM_ SG_ 395 MinEngTorqCapV "Minimum engine torque capacity validity; Invalid = [1]";
CM_ SG_ 395 MinImmedEngTorqCap "Minimum immediate engine torque capacity (current air flow, minimum spark)";
CM_ SG_ 395 MinImmedEngTorqCapV "Minimum immediate engine torque capacity validity; Invalid = [1]";
CM_ SG_ 395 MinPrdtdEngRunTorqCap "Minimum predicted engine run torque capacity (minimum air flow, MBT spark)";
CM_ SG_ 395 MinPrdtdEngRunTorqCapV "Minimum predicted engine run torque capacity validity; Invalid = [1]";
CM_ SG_ 401 AccPos "Accelerator Effective Position";
CM_ SG_ 401 AccPosV "Accelerator effective position validity; Invalid = [1]";
CM_ SG_ 401 CRC_191h "CRC-checksum byte 1 to 7 according to SAE J1850";
CM_ SG_ 401 ECM_IMMO_STAT_CANePT "ECM Immobilizer Status";
CM_ SG_ 401 EngActStdyStTorq "Engine actual steady state torque (current conditions)";
CM_ SG_ 401 EngActStdyStTorqV "Engine actual steady state torque validity; Invalid = [1]";
CM_ SG_ 401 EngAirFlwStdyStTorq "Engine airflow steady state torque (potential)";
CM_ SG_ 401 EngAirFlwStdyStTorqV "Engine airflow steady state torque validity; Invalid = [1]";
CM_ SG_ 401 EngDFCO_Allw "Engine deceleration fuel cut off allowed";
CM_ SG_ 401 EngDFCO_Req "Engine deceleration fuel cut off requested";
CM_ SG_ 401 EngDFCO_St "Engine deceleration fuel cut off state";
CM_ SG_ 401 EngRunCrnkAct "ECM run crank terminal status, 1=active";
CM_ SG_ 401 HybActEngTorqRespTyp "Hybrid Actual Engine Torque Response Type";
CM_ SG_ 401 MC_191h "Message counter.";
CM_ SG_ 401 PTCrnkAbrted "Powertrain crank aborted";
CM_ SG_ 401 PT_CrnkAct "Powertrain crank active";
CM_ SG_ 401 TLC_LRN_Rq "TLC learning request";
CM_ SG_ 908 GPS_Date_Day "GPS date day";
CM_ SG_ 908 GPS_Date_Month "GPS date month";
CM_ SG_ 908 GPS_Date_Year "GPS date year";
CM_ SG_ 908 GPS_UTC_Hour "GPS UTC hour";
CM_ SG_ 908 GPS_UTC_Minute "GPS UTC minute";
CM_ SG_ 908 GPS_UTC_Second "GPS UTC second";
CM_ SG_ 564 APM_IdcHvSetP "High  side current Setpoint";
CM_ SG_ 564 APM_IdcLvSetP "Low side current Setpoint";
CM_ SG_ 564 APM_OperModeEnable "APM Operation Mode  Enable";
CM_ SG_ 564 APM_VdcHvSetP "High side voltage set point";
CM_ SG_ 564 APM_VdcLvAct "System actual voltage";
CM_ SG_ 564 APM_VdcLvSetP "Low side voltage Setpoint";
CM_ SG_ 977 ChargingLevel "Charging level and type.";
CM_ SG_ 977 ChargingSysSts "Charging System status";
CM_ SG_ 977 ChrgSysFault "Charging System Fault status";
CM_ SG_ 977 ChrgSysFault_Reason "Failure reason";
CM_ SG_ 676 AirFlowReq "Air Flow Request";
CM_ SG_ 676 ChillerVlvSts "Battery chiller shutoff valve status;  0x0 Open, 0x1 Closed";
CM_ SG_ 676 CompSpdReq "compressor speed request";
CM_ SG_ 676 HVBatSOCV_HCP "High voltage battery state of charge validity: invalid = [1]";
CM_ SG_ 676 HVBatSOC_HCP "High voltage battery state of charge";
CM_ SG_ 676 LTActPumpCmd "Low Temp Active Pump Command";
CM_ SG_ 676 LTActPumpFailsafe_ACT "Low Temp Active Pump Failsafe";
CM_ SG_ 676 LTActPumpPostRunCom "Low temp active pump post run command";
CM_ SG_ 676 RadFanSts "Radiator Fan state";
CM_ SG_ 978 ChargeReq "Request for scheduled charge; Charge now = [1]";
CM_ SG_ 978 ODO "Odometer";
CM_ SG_ 978 SHIP_STAT "Shipping status";
CM_ SG_ 530 CRC_VEH_SPEED "CRC-checksum byte 1 to 7 according to SAE J1850";
CM_ SG_ 530 CmdIgnStat "Commanded ignition switch status";
CM_ SG_ 530 KeyInIgn "Key in ignition status";
CM_ SG_ 530 MC_VEH_SPEED "Message counter";
CM_ SG_ 530 RemStActv "Ignition run active for remote start (0=not active, 1=active)";
CM_ SG_ 530 VEH_SPEED "Vehicle speed";
BA_DEF_ BO_  "App-Botschaft" ENUM  "nein","ja";
BA_DEF_ BO_  "CanMsgMinLen" INT 0 8;
BA_DEF_ BO_  "DiagRequest" ENUM  "nein","ja";
BA_DEF_ BO_  "DiagResponse" ENUM  "nein","ja";
BA_DEF_ BO_  "DiagState" ENUM  "nein","ja";
BA_DEF_ BO_  "GenMsgCycleTime" INT 0 65535;
BA_DEF_ BO_  "GenMsgCycleTimeActive" INT 0 65535;
BA_DEF_ BO_  "GenMsgDelayTime" INT 0 65535;
BA_DEF_ BO_  "GenMsgNrOfRepetitions" INT 0 65535;
BA_DEF_ BO_  "GenMsgSendType" ENUM  "cyclicX","spontanX","cyclicIfActiveX","spontanWithDelay","cyclicAndSpontanX","cyclicAndSpontanWithDelay","spontanWithRepitition","cyclicIfActiveAndSpontanWD","cyclicIfActiveFast","cyclicWithRepeatOnDemand","none";
BA_DEF_ BO_  "GenMsgStartDelayTime" INT 0 65535;
BA_DEF_ BO_  "GenMsgStartValue" STRING ;
BA_DEF_ BO_  "NWM-Botschaft" ENUM  "nein","ja";
BA_DEF_ BO_  "TpTxIndex" INT 0 99;
BA_DEF_ SG_  "FlexKomComment" STRING ;
BA_DEF_ SG_  "FlexKomIsMotorola" ENUM  "nein","ja";
BA_DEF_ SG_  "FlexKomSID" INT 0 2147483647;
BA_DEF_ SG_  "FlexKomSigLaenge" INT 0 64;
BA_DEF_ SG_  "FlexKomSigName" STRING ;
BA_DEF_ SG_  "FlexKomSigStartPos" INT 0 63;
BA_DEF_ SG_  "FlexKomSigStartValue" STRING ;
BA_DEF_ SG_  "GenSigCycleTime" INT 0 65535;
BA_DEF_ SG_  "GenSigCycleTimeActive" INT 0 65535;
BA_DEF_ SG_  "GenSigSendType" ENUM  "cyclicX","spontanX","cyclicIfActiveX","spontanWithDelay","cyclicAndSpontanX","cyclicAndSpontanWithDelay","spontanWithRepitition","cyclicIfActiveAndSpontanWD","cyclicIfActiveFast","cyclicWithRepeatOnDemand","none";
BA_DEF_ SG_  "GenSigSNA" STRING ;
BA_DEF_ SG_  "GenSigStartValue" HEX 0 2147483648;
BA_DEF_ SG_  "RID" STRING ;
BA_DEF_DEF_  "App-Botschaft" "nein";
BA_DEF_DEF_  "CanMsgMinLen" 0;
BA_DEF_DEF_  "DiagRequest" "nein";
BA_DEF_DEF_  "DiagResponse" "nein";
BA_DEF_DEF_  "DiagState" "nein";
BA_DEF_DEF_  "GenMsgCycleTime" 0;
BA_DEF_DEF_  "GenMsgCycleTimeActive" 0;
BA_DEF_DEF_  "GenMsgDelayTime" 0;
BA_DEF_DEF_  "GenMsgNrOfRepetitions" 0;
BA_DEF_DEF_  "GenMsgSendType" "cyclicX";
BA_DEF_DEF_  "GenMsgStartDelayTime" 0;
BA_DEF_DEF_  "GenMsgStartValue" "";
BA_DEF_DEF_  "NWM-Botschaft" "nein";
BA_DEF_DEF_  "TpTxIndex" 0;
BA_DEF_DEF_  "FlexKomComment" "";
BA_DEF_DEF_  "FlexKomIsMotorola" "nein";
BA_DEF_DEF_  "FlexKomSID" 0;
BA_DEF_DEF_  "FlexKomSigLaenge" 0;
BA_DEF_DEF_  "FlexKomSigName" "";
BA_DEF_DEF_  "FlexKomSigStartPos" 0;
BA_DEF_DEF_  "FlexKomSigStartValue" "";
BA_DEF_DEF_  "GenSigCycleTime" 0;
BA_DEF_DEF_  "GenSigCycleTimeActive" 0;
BA_DEF_DEF_  "GenSigSendType" "cyclicX";
BA_DEF_DEF_  "GenSigSNA" "";
BA_DEF_DEF_  "GenSigStartValue" 0;
BA_DEF_DEF_  "RID" "";
BA_ "GenMsgStartValue" BO_ 792 "00000000h";
BA_ "GenMsgNrOfRepetitions" BO_ 792 2;
BA_ "GenMsgDelayTime" BO_ 792 20;
BA_ "GenMsgCycleTime" BO_ 792 100;
BA_ "GenMsgStartValue" BO_ 256 "00000140000000FFh";
BA_ "GenMsgNrOfRepetitions" BO_ 256 2;
BA_ "GenMsgDelayTime" BO_ 256 20;
BA_ "GenMsgCycleTime" BO_ 256 10;
BA_ "GenMsgStartValue" BO_ 514 "0000000000000000h";
BA_ "GenMsgNrOfRepetitions" BO_ 514 2;
BA_ "GenMsgDelayTime" BO_ 514 20;
BA_ "GenMsgCycleTime" BO_ 514 20;
BA_ "GenMsgStartValue" BO_ 653 "0000F003FFFE00FFh";
BA_ "GenMsgNrOfRepetitions" BO_ 653 2;
BA_ "GenMsgDelayTime" BO_ 653 20;
BA_ "GenMsgCycleTime" BO_ 653 20;
BA_ "GenMsgStartValue" BO_ 257 "000000h";
BA_ "GenMsgNrOfRepetitions" BO_ 257 2;
BA_ "GenMsgDelayTime" BO_ 257 20;
BA_ "GenMsgCycleTime" BO_ 257 100;
BA_ "GenMsgStartValue" BO_ 259 "0000000000000000h";
BA_ "GenMsgNrOfRepetitions" BO_ 259 2;
BA_ "GenMsgDelayTime" BO_ 259 20;
BA_ "GenMsgCycleTime" BO_ 259 10;
BA_ "GenMsgStartValue" BO_ 516 "F0000000000000FFh";
BA_ "GenMsgNrOfRepetitions" BO_ 516 2;
BA_ "GenMsgDelayTime" BO_ 516 20;
BA_ "GenMsgCycleTime" BO_ 516 20;
BA_ "GenMsgStartValue" BO_ 320 "0F3400C003FF00FFh";
BA_ "GenMsgNrOfRepetitions" BO_ 320 2;
BA_ "GenMsgDelayTime" BO_ 320 20;
BA_ "GenMsgCycleTime" BO_ 320 20;
BA_ "GenMsgStartValue" BO_ 268 "00000000FF0000FFh";
BA_ "GenMsgNrOfRepetitions" BO_ 268 2;
BA_ "GenMsgDelayTime" BO_ 268 20;
BA_ "GenMsgCycleTime" BO_ 268 20;
BA_ "GenMsgStartValue" BO_ 292 "0000000000FFFFFFh";
BA_ "GenMsgNrOfRepetitions" BO_ 292 2;
BA_ "GenMsgDelayTime" BO_ 292 20;
BA_ "GenMsgCycleTime" BO_ 292 20;
BA_ "GenMsgStartValue" BO_ 344 "FFFFFFFFFFFFFFFFh";
BA_ "GenMsgNrOfRepetitions" BO_ 344 2;
BA_ "GenMsgDelayTime" BO_ 344 20;
BA_ "GenMsgCycleTime" BO_ 344 20;
BA_ "GenMsgStartValue" BO_ 682 "FFFF8000000000FFh";
BA_ "GenMsgNrOfRepetitions" BO_ 682 2;
BA_ "GenMsgCycleTime" BO_ 682 10;
BA_ "GenMsgStartValue" BO_ 402 "00000000080000h";
BA_ "GenMsgNrOfRepetitions" BO_ 402 2;
BA_ "GenMsgDelayTime" BO_ 402 20;
BA_ "GenMsgCycleTime" BO_ 402 10;
BA_ "GenMsgStartValue" BO_ 400 "00000B830B830FFFh";
BA_ "GenMsgNrOfRepetitions" BO_ 400 2;
BA_ "GenMsgDelayTime" BO_ 400 20;
BA_ "GenMsgCycleTime" BO_ 400 10;
BA_ "GenMsgStartValue" BO_ 771 "0000002000000000h";
BA_ "GenMsgNrOfRepetitions" BO_ 771 2;
BA_ "GenMsgDelayTime" BO_ 771 20;
BA_ "GenMsgCycleTime" BO_ 771 100;
BA_ "GenMsgStartValue" BO_ 396 "0000000000000000h";
BA_ "GenMsgNrOfRepetitions" BO_ 396 2;
BA_ "GenMsgDelayTime" BO_ 396 20;
BA_ "GenMsgCycleTime" BO_ 396 100;
BA_ "GenMsgStartValue" BO_ 770 "0000000000000000h";
BA_ "GenMsgNrOfRepetitions" BO_ 770 2;
BA_ "GenMsgDelayTime" BO_ 770 20;
BA_ "GenMsgCycleTime" BO_ 770 100;
BA_ "GenMsgStartValue" BO_ 849 "03AA03AA000003AAh";
BA_ "GenMsgNrOfRepetitions" BO_ 849 2;
BA_ "GenMsgDelayTime" BO_ 849 20;
BA_ "GenMsgCycleTime" BO_ 849 200;
BA_ "GenMsgStartValue" BO_ 395 "03AA03AA03AA03AAh";
BA_ "GenMsgNrOfRepetitions" BO_ 395 2;
BA_ "GenMsgDelayTime" BO_ 395 20;
BA_ "GenMsgCycleTime" BO_ 395 10;
BA_ "GenMsgStartValue" BO_ 401 "000003AA03AA00FFh";
BA_ "GenMsgNrOfRepetitions" BO_ 401 2;
BA_ "GenMsgDelayTime" BO_ 401 20;
BA_ "GenMsgCycleTime" BO_ 401 10;
BA_ "GenMsgStartValue" BO_ 908 "FFFFFFFFFFFFFFFFh";
BA_ "GenMsgNrOfRepetitions" BO_ 908 2;
BA_ "GenMsgDelayTime" BO_ 908 20;
BA_ "GenMsgCycleTime" BO_ 908 1000;
BA_ "GenMsgStartValue" BO_ 564 "DDE50000000000FFh";
BA_ "GenMsgNrOfRepetitions" BO_ 564 2;
BA_ "GenMsgDelayTime" BO_ 564 20;
BA_ "GenMsgCycleTime" BO_ 564 50;
BA_ "GenMsgStartValue" BO_ 977 "0000000000000000h";
BA_ "GenMsgNrOfRepetitions" BO_ 977 2;
BA_ "GenMsgDelayTime" BO_ 977 20;
BA_ "GenMsgCycleTime" BO_ 977 500;
BA_ "GenMsgStartValue" BO_ 676 "0000C0000000E000h";
BA_ "GenMsgNrOfRepetitions" BO_ 676 2;
BA_ "GenMsgDelayTime" BO_ 676 20;
BA_ "GenMsgCycleTime" BO_ 676 100;
BA_ "GenMsgStartValue" BO_ 978 "FF00FFFFFF0000D8h";
BA_ "GenMsgNrOfRepetitions" BO_ 978 2;
BA_ "GenMsgDelayTime" BO_ 978 20;
BA_ "GenMsgCycleTime" BO_ 978 1000;
BA_ "GenMsgStartValue" BO_ 530 "00000000FFFF00FFh";
BA_ "GenMsgNrOfRepetitions" BO_ 530 2;
BA_ "GenMsgDelayTime" BO_ 530 20;
BA_ "GenMsgCycleTime" BO_ 530 20;
BA_ "GenSigSNA" SG_ 792 CompBoardTemp "FFh";
BA_ "GenSigCycleTime" SG_ 792 CompBoardTemp 100;
BA_ "FlexKomSigStartValue" SG_ 792 CompBoardTemp "00000000h";
BA_ "FlexKomSigStartPos" SG_ 792 CompBoardTemp 7;
BA_ "FlexKomSigName" SG_ 792 CompBoardTemp "EAC_STATUS2";
BA_ "FlexKomSigLaenge" SG_ 792 CompBoardTemp 32;
BA_ "FlexKomSID" SG_ 792 CompBoardTemp 2130708632;
BA_ "FlexKomIsMotorola" SG_ 792 CompBoardTemp 1;
BA_ "FlexKomComment" SG_ 792 CompBoardTemp ".";
BA_ "GenSigSNA" SG_ 792 CompBoardTempV "0h";
BA_ "GenSigCycleTime" SG_ 792 CompBoardTempV 100;
BA_ "FlexKomSigStartValue" SG_ 792 CompBoardTempV "00000000h";
BA_ "FlexKomSigStartPos" SG_ 792 CompBoardTempV 7;
BA_ "FlexKomSigName" SG_ 792 CompBoardTempV "EAC_STATUS2";
BA_ "FlexKomSigLaenge" SG_ 792 CompBoardTempV 32;
BA_ "FlexKomSID" SG_ 792 CompBoardTempV 2130708632;
BA_ "FlexKomIsMotorola" SG_ 792 CompBoardTempV 1;
BA_ "FlexKomComment" SG_ 792 CompBoardTempV ".";
BA_ "GenSigSNA" SG_ 792 CompHVInput "FFh";
BA_ "GenSigCycleTime" SG_ 792 CompHVInput 100;
BA_ "FlexKomSigStartValue" SG_ 792 CompHVInput "00000000h";
BA_ "FlexKomSigStartPos" SG_ 792 CompHVInput 7;
BA_ "FlexKomSigName" SG_ 792 CompHVInput "EAC_STATUS2";
BA_ "FlexKomSigLaenge" SG_ 792 CompHVInput 32;
BA_ "FlexKomSID" SG_ 792 CompHVInput 2130708632;
BA_ "FlexKomIsMotorola" SG_ 792 CompHVInput 1;
BA_ "FlexKomComment" SG_ 792 CompHVInput ".";
BA_ "GenSigSNA" SG_ 792 CompHVInputV "0h";
BA_ "GenSigCycleTime" SG_ 792 CompHVInputV 100;
BA_ "FlexKomSigStartValue" SG_ 792 CompHVInputV "00000000h";
BA_ "FlexKomSigStartPos" SG_ 792 CompHVInputV 7;
BA_ "FlexKomSigName" SG_ 792 CompHVInputV "EAC_STATUS2";
BA_ "FlexKomSigLaenge" SG_ 792 CompHVInputV 32;
BA_ "FlexKomSID" SG_ 792 CompHVInputV 2130708632;
BA_ "FlexKomIsMotorola" SG_ 792 CompHVInputV 1;
BA_ "FlexKomComment" SG_ 792 CompHVInputV ".";
BA_ "GenSigSNA" SG_ 792 CompIGBTTemp "FFh";
BA_ "GenSigCycleTime" SG_ 792 CompIGBTTemp 100;
BA_ "FlexKomSigStartValue" SG_ 792 CompIGBTTemp "00000000h";
BA_ "FlexKomSigStartPos" SG_ 792 CompIGBTTemp 7;
BA_ "FlexKomSigName" SG_ 792 CompIGBTTemp "EAC_STATUS2";
BA_ "FlexKomSigLaenge" SG_ 792 CompIGBTTemp 32;
BA_ "FlexKomSID" SG_ 792 CompIGBTTemp 2130708632;
BA_ "FlexKomIsMotorola" SG_ 792 CompIGBTTemp 1;
BA_ "FlexKomComment" SG_ 792 CompIGBTTemp ".";
BA_ "GenSigSNA" SG_ 792 CompIGBTTempV "0h";
BA_ "GenSigCycleTime" SG_ 792 CompIGBTTempV 100;
BA_ "FlexKomSigStartValue" SG_ 792 CompIGBTTempV "00000000h";
BA_ "FlexKomSigStartPos" SG_ 792 CompIGBTTempV 7;
BA_ "FlexKomSigName" SG_ 792 CompIGBTTempV "EAC_STATUS2";
BA_ "FlexKomSigLaenge" SG_ 792 CompIGBTTempV 32;
BA_ "FlexKomSID" SG_ 792 CompIGBTTempV 2130708632;
BA_ "FlexKomIsMotorola" SG_ 792 CompIGBTTempV 1;
BA_ "FlexKomComment" SG_ 792 CompIGBTTempV ".";
BA_ "GenSigStartValue" SG_ 256 CRC_100h 255;
BA_ "GenSigSNA" SG_ 256 CRC_100h "FFh";
BA_ "GenSigCycleTime" SG_ 256 CRC_100h 10;
BA_ "FlexKomSigStartValue" SG_ 256 CRC_100h "00000140000000FFh";
BA_ "FlexKomSigStartPos" SG_ 256 CRC_100h 7;
BA_ "FlexKomSigName" SG_ 256 CRC_100h "EBCM_10";
BA_ "FlexKomSigLaenge" SG_ 256 CRC_100h 64;
BA_ "FlexKomSID" SG_ 256 CRC_100h 2130708603;
BA_ "FlexKomIsMotorola" SG_ 256 CRC_100h 1;
BA_ "FlexKomComment" SG_ 256 CRC_100h ".";
BA_ "GenSigSNA" SG_ 256 ExtReqActive "0h";
BA_ "GenSigCycleTime" SG_ 256 ExtReqActive 10;
BA_ "FlexKomSigStartValue" SG_ 256 ExtReqActive "00000140000000FFh";
BA_ "FlexKomSigStartPos" SG_ 256 ExtReqActive 7;
BA_ "FlexKomSigName" SG_ 256 ExtReqActive "EBCM_10";
BA_ "FlexKomSigLaenge" SG_ 256 ExtReqActive 64;
BA_ "FlexKomSID" SG_ 256 ExtReqActive 2130708603;
BA_ "FlexKomIsMotorola" SG_ 256 ExtReqActive 1;
BA_ "FlexKomComment" SG_ 256 ExtReqActive ".";
BA_ "GenSigSNA" SG_ 256 ExtReqStatus "0h";
BA_ "GenSigCycleTime" SG_ 256 ExtReqStatus 10;
BA_ "FlexKomSigStartValue" SG_ 256 ExtReqStatus "00000140000000FFh";
BA_ "FlexKomSigStartPos" SG_ 256 ExtReqStatus 7;
BA_ "FlexKomSigName" SG_ 256 ExtReqStatus "EBCM_10";
BA_ "FlexKomSigLaenge" SG_ 256 ExtReqStatus 64;
BA_ "FlexKomSID" SG_ 256 ExtReqStatus 2130708603;
BA_ "FlexKomIsMotorola" SG_ 256 ExtReqStatus 1;
BA_ "FlexKomComment" SG_ 256 ExtReqStatus ".";
BA_ "GenSigSNA" SG_ 256 MC_100h "Fh";
BA_ "GenSigCycleTime" SG_ 256 MC_100h 10;
BA_ "FlexKomSigStartValue" SG_ 256 MC_100h "00000140000000FFh";
BA_ "FlexKomSigStartPos" SG_ 256 MC_100h 7;
BA_ "FlexKomSigName" SG_ 256 MC_100h "EBCM_10";
BA_ "FlexKomSigLaenge" SG_ 256 MC_100h 64;
BA_ "FlexKomSID" SG_ 256 MC_100h 2130708603;
BA_ "FlexKomIsMotorola" SG_ 256 MC_100h 1;
BA_ "FlexKomComment" SG_ 256 MC_100h ".";
BA_ "GenSigSNA" SG_ 256 MaxTqAvail_EBCM "0h";
BA_ "GenSigCycleTime" SG_ 256 MaxTqAvail_EBCM 10;
BA_ "FlexKomSigStartValue" SG_ 256 MaxTqAvail_EBCM "00000140000000FFh";
BA_ "FlexKomSigStartPos" SG_ 256 MaxTqAvail_EBCM 7;
BA_ "FlexKomSigName" SG_ 256 MaxTqAvail_EBCM "EBCM_10";
BA_ "FlexKomSigLaenge" SG_ 256 MaxTqAvail_EBCM 64;
BA_ "FlexKomSID" SG_ 256 MaxTqAvail_EBCM 2130708603;
BA_ "FlexKomIsMotorola" SG_ 256 MaxTqAvail_EBCM 1;
BA_ "FlexKomComment" SG_ 256 MaxTqAvail_EBCM ".";
BA_ "GenSigSNA" SG_ 256 MaxTrqGrdAvail_EBCM "0h";
BA_ "GenSigCycleTime" SG_ 256 MaxTrqGrdAvail_EBCM 10;
BA_ "FlexKomSigStartValue" SG_ 256 MaxTrqGrdAvail_EBCM "00000140000000FFh";
BA_ "FlexKomSigStartPos" SG_ 256 MaxTrqGrdAvail_EBCM 7;
BA_ "FlexKomSigName" SG_ 256 MaxTrqGrdAvail_EBCM "EBCM_10";
BA_ "FlexKomSigLaenge" SG_ 256 MaxTrqGrdAvail_EBCM 64;
BA_ "FlexKomSID" SG_ 256 MaxTrqGrdAvail_EBCM 2130708603;
BA_ "FlexKomIsMotorola" SG_ 256 MaxTrqGrdAvail_EBCM 1;
BA_ "FlexKomComment" SG_ 256 MaxTrqGrdAvail_EBCM ".";
BA_ "GenSigSNA" SG_ 256 OutputRodAct_Qualifier "0h";
BA_ "GenSigCycleTime" SG_ 256 OutputRodAct_Qualifier 10;
BA_ "FlexKomSigStartValue" SG_ 256 OutputRodAct_Qualifier "00000140000000FFh";
BA_ "FlexKomSigStartPos" SG_ 256 OutputRodAct_Qualifier 7;
BA_ "FlexKomSigName" SG_ 256 OutputRodAct_Qualifier "EBCM_10";
BA_ "FlexKomSigLaenge" SG_ 256 OutputRodAct_Qualifier 64;
BA_ "FlexKomSID" SG_ 256 OutputRodAct_Qualifier 2130708603;
BA_ "FlexKomIsMotorola" SG_ 256 OutputRodAct_Qualifier 1;
BA_ "FlexKomComment" SG_ 256 OutputRodAct_Qualifier ".";
BA_ "GenSigStartValue" SG_ 256 sOutputRodAct 320;
BA_ "GenSigSNA" SG_ 256 sOutputRodAct "FFFh";
BA_ "GenSigCycleTime" SG_ 256 sOutputRodAct 10;
BA_ "FlexKomSigStartValue" SG_ 256 sOutputRodAct "00000140000000FFh";
BA_ "FlexKomSigStartPos" SG_ 256 sOutputRodAct 7;
BA_ "FlexKomSigName" SG_ 256 sOutputRodAct "EBCM_10";
BA_ "FlexKomSigLaenge" SG_ 256 sOutputRodAct 64;
BA_ "FlexKomSID" SG_ 256 sOutputRodAct 2130708603;
BA_ "FlexKomIsMotorola" SG_ 256 sOutputRodAct 1;
BA_ "FlexKomComment" SG_ 256 sOutputRodAct ".";
BA_ "GenSigSNA" SG_ 256 sOutputRodTarget "FFFh";
BA_ "GenSigCycleTime" SG_ 256 sOutputRodTarget 10;
BA_ "FlexKomSigStartValue" SG_ 256 sOutputRodTarget "00000140000000FFh";
BA_ "FlexKomSigStartPos" SG_ 256 sOutputRodTarget 7;
BA_ "FlexKomSigName" SG_ 256 sOutputRodTarget "EBCM_10";
BA_ "FlexKomSigLaenge" SG_ 256 sOutputRodTarget 64;
BA_ "FlexKomSID" SG_ 256 sOutputRodTarget 2130708603;
BA_ "FlexKomIsMotorola" SG_ 256 sOutputRodTarget 1;
BA_ "FlexKomComment" SG_ 256 sOutputRodTarget ".";
BA_ "GenSigSNA" SG_ 256 sOutputRod_Qualifier "0h";
BA_ "GenSigCycleTime" SG_ 256 sOutputRod_Qualifier 10;
BA_ "FlexKomSigStartValue" SG_ 256 sOutputRod_Qualifier "00000140000000FFh";
BA_ "FlexKomSigStartPos" SG_ 256 sOutputRod_Qualifier 7;
BA_ "FlexKomSigName" SG_ 256 sOutputRod_Qualifier "EBCM_10";
BA_ "FlexKomSigLaenge" SG_ 256 sOutputRod_Qualifier 64;
BA_ "FlexKomSID" SG_ 256 sOutputRod_Qualifier 2130708603;
BA_ "FlexKomIsMotorola" SG_ 256 sOutputRod_Qualifier 1;
BA_ "FlexKomComment" SG_ 256 sOutputRod_Qualifier ".";
BA_ "GenSigStartValue" SG_ 514 MC_EBCM_20 15;
BA_ "GenSigStartValue" SG_ 514 CRC_EBCM_20 255;
BA_ "GenSigSNA" SG_ 514 CompatibilityIndex "0h";
BA_ "GenSigCycleTime" SG_ 514 CompatibilityIndex 20;
BA_ "FlexKomSigStartValue" SG_ 514 CompatibilityIndex "0000000000000000h";
BA_ "FlexKomSigStartPos" SG_ 514 CompatibilityIndex 7;
BA_ "FlexKomSigName" SG_ 514 CompatibilityIndex "EBCM_20";
BA_ "FlexKomSigLaenge" SG_ 514 CompatibilityIndex 64;
BA_ "FlexKomSID" SG_ 514 CompatibilityIndex 2130708604;
BA_ "FlexKomIsMotorola" SG_ 514 CompatibilityIndex 1;
BA_ "FlexKomComment" SG_ 514 CompatibilityIndex ".";
BA_ "GenSigSNA" SG_ 514 iBStatus "0h";
BA_ "GenSigCycleTime" SG_ 514 iBStatus 20;
BA_ "FlexKomSigStartValue" SG_ 514 iBStatus "0000000000000000h";
BA_ "FlexKomSigStartPos" SG_ 514 iBStatus 7;
BA_ "FlexKomSigName" SG_ 514 iBStatus "EBCM_20";
BA_ "FlexKomSigLaenge" SG_ 514 iBStatus 64;
BA_ "FlexKomSID" SG_ 514 iBStatus 2130708604;
BA_ "FlexKomIsMotorola" SG_ 514 iBStatus 1;
BA_ "FlexKomComment" SG_ 514 iBStatus ".";
BA_ "GenSigSNA" SG_ 514 pForceBlendingReserve "0h";
BA_ "GenSigCycleTime" SG_ 514 pForceBlendingReserve 20;
BA_ "FlexKomSigStartValue" SG_ 514 pForceBlendingReserve "0000000000000000h";
BA_ "FlexKomSigStartPos" SG_ 514 pForceBlendingReserve 7;
BA_ "FlexKomSigName" SG_ 514 pForceBlendingReserve "EBCM_20";
BA_ "FlexKomSigLaenge" SG_ 514 pForceBlendingReserve 64;
BA_ "FlexKomSID" SG_ 514 pForceBlendingReserve 2130708604;
BA_ "FlexKomIsMotorola" SG_ 514 pForceBlendingReserve 1;
BA_ "FlexKomComment" SG_ 514 pForceBlendingReserve ".";
BA_ "GenSigSNA" SG_ 514 pForceBlendingReserve_V "0h";
BA_ "GenSigCycleTime" SG_ 514 pForceBlendingReserve_V 20;
BA_ "FlexKomSigStartValue" SG_ 514 pForceBlendingReserve_V "0000000000000000h";
BA_ "FlexKomSigStartPos" SG_ 514 pForceBlendingReserve_V 7;
BA_ "FlexKomSigName" SG_ 514 pForceBlendingReserve_V "EBCM_20";
BA_ "FlexKomSigLaenge" SG_ 514 pForceBlendingReserve_V 64;
BA_ "FlexKomSID" SG_ 514 pForceBlendingReserve_V 2130708604;
BA_ "FlexKomIsMotorola" SG_ 514 pForceBlendingReserve_V 1;
BA_ "FlexKomComment" SG_ 514 pForceBlendingReserve_V ".";
BA_ "GenSigSNA" SG_ 514 pRunout "0h";
BA_ "GenSigCycleTime" SG_ 514 pRunout 20;
BA_ "FlexKomSigStartValue" SG_ 514 pRunout "0000000000000000h";
BA_ "FlexKomSigStartPos" SG_ 514 pRunout 7;
BA_ "FlexKomSigName" SG_ 514 pRunout "EBCM_20";
BA_ "FlexKomSigLaenge" SG_ 514 pRunout 64;
BA_ "FlexKomSID" SG_ 514 pRunout 2130708604;
BA_ "FlexKomIsMotorola" SG_ 514 pRunout 1;
BA_ "FlexKomComment" SG_ 514 pRunout ".";
BA_ "GenSigSNA" SG_ 514 pRunout_V "0h";
BA_ "GenSigCycleTime" SG_ 514 pRunout_V 20;
BA_ "FlexKomSigStartValue" SG_ 514 pRunout_V "0000000000000000h";
BA_ "FlexKomSigStartPos" SG_ 514 pRunout_V 7;
BA_ "FlexKomSigName" SG_ 514 pRunout_V "EBCM_20";
BA_ "FlexKomSigLaenge" SG_ 514 pRunout_V 64;
BA_ "FlexKomSID" SG_ 514 pRunout_V 2130708604;
BA_ "FlexKomIsMotorola" SG_ 514 pRunout_V 1;
BA_ "FlexKomComment" SG_ 514 pRunout_V ".";
BA_ "GenSigSNA" SG_ 653 BrakePedalApplied "0h";
BA_ "GenSigCycleTime" SG_ 653 BrakePedalApplied 20;
BA_ "FlexKomSigStartValue" SG_ 653 BrakePedalApplied "0000F003FFFE00FFh";
BA_ "FlexKomSigStartPos" SG_ 653 BrakePedalApplied 7;
BA_ "FlexKomSigName" SG_ 653 BrakePedalApplied "EBCM_C1_Pkt";
BA_ "FlexKomSigLaenge" SG_ 653 BrakePedalApplied 64;
BA_ "FlexKomSID" SG_ 653 BrakePedalApplied 9813;
BA_ "FlexKomIsMotorola" SG_ 653 BrakePedalApplied 1;
BA_ "FlexKomComment" SG_ 653 BrakePedalApplied "Message EBCM_C1 packet";
BA_ "GenSigSNA" SG_ 653 BrakePedalAppliedV "0h";
BA_ "GenSigCycleTime" SG_ 653 BrakePedalAppliedV 20;
BA_ "FlexKomSigStartValue" SG_ 653 BrakePedalAppliedV "0000F003FFFE00FFh";
BA_ "FlexKomSigStartPos" SG_ 653 BrakePedalAppliedV 7;
BA_ "FlexKomSigName" SG_ 653 BrakePedalAppliedV "EBCM_C1_Pkt";
BA_ "FlexKomSigLaenge" SG_ 653 BrakePedalAppliedV 64;
BA_ "FlexKomSID" SG_ 653 BrakePedalAppliedV 9813;
BA_ "FlexKomIsMotorola" SG_ 653 BrakePedalAppliedV 1;
BA_ "FlexKomComment" SG_ 653 BrakePedalAppliedV "Message EBCM_C1 packet";
BA_ "GenSigSNA" SG_ 653 BrakePedalTravelSensor "FFh";
BA_ "GenSigCycleTime" SG_ 653 BrakePedalTravelSensor 20;
BA_ "FlexKomSigStartValue" SG_ 653 BrakePedalTravelSensor "0000F003FFFE00FFh";
BA_ "FlexKomSigStartPos" SG_ 653 BrakePedalTravelSensor 7;
BA_ "FlexKomSigName" SG_ 653 BrakePedalTravelSensor "EBCM_C1_Pkt";
BA_ "FlexKomSigLaenge" SG_ 653 BrakePedalTravelSensor 64;
BA_ "FlexKomSID" SG_ 653 BrakePedalTravelSensor 9813;
BA_ "FlexKomIsMotorola" SG_ 653 BrakePedalTravelSensor 1;
BA_ "FlexKomComment" SG_ 653 BrakePedalTravelSensor "Message EBCM_C1 packet";
BA_ "GenSigSNA" SG_ 653 BrakePedalTravelSensorV "0h";
BA_ "GenSigCycleTime" SG_ 653 BrakePedalTravelSensorV 20;
BA_ "FlexKomSigStartValue" SG_ 653 BrakePedalTravelSensorV "0000F003FFFE00FFh";
BA_ "FlexKomSigStartPos" SG_ 653 BrakePedalTravelSensorV 7;
BA_ "FlexKomSigName" SG_ 653 BrakePedalTravelSensorV "EBCM_C1_Pkt";
BA_ "FlexKomSigLaenge" SG_ 653 BrakePedalTravelSensorV 64;
BA_ "FlexKomSID" SG_ 653 BrakePedalTravelSensorV 9813;
BA_ "FlexKomIsMotorola" SG_ 653 BrakePedalTravelSensorV 1;
BA_ "FlexKomComment" SG_ 653 BrakePedalTravelSensorV "Message EBCM_C1 packet";
BA_ "GenSigSNA" SG_ 653 BrakeSysStateSec "7h";
BA_ "GenSigCycleTime" SG_ 653 BrakeSysStateSec 20;
BA_ "FlexKomSigStartValue" SG_ 653 BrakeSysStateSec "0000F003FFFE00FFh";
BA_ "FlexKomSigStartPos" SG_ 653 BrakeSysStateSec 7;
BA_ "FlexKomSigName" SG_ 653 BrakeSysStateSec "EBCM_C1_Pkt";
BA_ "FlexKomSigLaenge" SG_ 653 BrakeSysStateSec 64;
BA_ "FlexKomSID" SG_ 653 BrakeSysStateSec 9813;
BA_ "FlexKomIsMotorola" SG_ 653 BrakeSysStateSec 1;
BA_ "FlexKomComment" SG_ 653 BrakeSysStateSec "Message EBCM_C1 packet";
BA_ "GenSigSNA" SG_ 653 BrkPdl_Flt_2 "0h";
BA_ "GenSigCycleTime" SG_ 653 BrkPdl_Flt_2 20;
BA_ "FlexKomSigStartValue" SG_ 653 BrkPdl_Flt_2 "0000F003FFFE00FFh";
BA_ "FlexKomSigStartPos" SG_ 653 BrkPdl_Flt_2 7;
BA_ "FlexKomSigName" SG_ 653 BrkPdl_Flt_2 "EBCM_C1_Pkt";
BA_ "FlexKomSigLaenge" SG_ 653 BrkPdl_Flt_2 64;
BA_ "FlexKomSID" SG_ 653 BrkPdl_Flt_2 9813;
BA_ "FlexKomIsMotorola" SG_ 653 BrkPdl_Flt_2 1;
BA_ "FlexKomComment" SG_ 653 BrkPdl_Flt_2 "Message EBCM_C1 packet";
BA_ "GenSigSNA" SG_ 653 BrkPdl_Stat_2 "3h";
BA_ "GenSigCycleTime" SG_ 653 BrkPdl_Stat_2 20;
BA_ "FlexKomSigStartValue" SG_ 653 BrkPdl_Stat_2 "0000F003FFFE00FFh";
BA_ "FlexKomSigStartPos" SG_ 653 BrkPdl_Stat_2 7;
BA_ "FlexKomSigName" SG_ 653 BrkPdl_Stat_2 "EBCM_C1_Pkt";
BA_ "FlexKomSigLaenge" SG_ 653 BrkPdl_Stat_2 64;
BA_ "FlexKomSID" SG_ 653 BrkPdl_Stat_2 9813;
BA_ "FlexKomIsMotorola" SG_ 653 BrkPdl_Stat_2 1;
BA_ "FlexKomComment" SG_ 653 BrkPdl_Stat_2 "Message EBCM_C1 packet";
BA_ "GenSigSNA" SG_ 653 Brk_Stat_2 "3h";
BA_ "GenSigCycleTime" SG_ 653 Brk_Stat_2 20;
BA_ "FlexKomSigStartValue" SG_ 653 Brk_Stat_2 "0000F003FFFE00FFh";
BA_ "FlexKomSigStartPos" SG_ 653 Brk_Stat_2 7;
BA_ "FlexKomSigName" SG_ 653 Brk_Stat_2 "EBCM_C1_Pkt";
BA_ "FlexKomSigLaenge" SG_ 653 Brk_Stat_2 64;
BA_ "FlexKomSID" SG_ 653 Brk_Stat_2 9813;
BA_ "FlexKomIsMotorola" SG_ 653 Brk_Stat_2 1;
BA_ "FlexKomComment" SG_ 653 Brk_Stat_2 "Message EBCM_C1 packet";
BA_ "GenSigStartValue" SG_ 653 CRC_EBCM_C1 255;
BA_ "GenSigSNA" SG_ 653 CRC_EBCM_C1 "FFh";
BA_ "GenSigCycleTime" SG_ 653 CRC_EBCM_C1 20;
BA_ "FlexKomSigStartValue" SG_ 653 CRC_EBCM_C1 "0000F003FFFE00FFh";
BA_ "FlexKomSigStartPos" SG_ 653 CRC_EBCM_C1 7;
BA_ "FlexKomSigName" SG_ 653 CRC_EBCM_C1 "EBCM_C1_Pkt";
BA_ "FlexKomSigLaenge" SG_ 653 CRC_EBCM_C1 64;
BA_ "FlexKomSID" SG_ 653 CRC_EBCM_C1 9813;
BA_ "FlexKomIsMotorola" SG_ 653 CRC_EBCM_C1 1;
BA_ "FlexKomComment" SG_ 653 CRC_EBCM_C1 "Message EBCM_C1 packet";
BA_ "GenSigSNA" SG_ 653 DAS_RqActv "7h";
BA_ "GenSigCycleTime" SG_ 653 DAS_RqActv 20;
BA_ "FlexKomSigStartValue" SG_ 653 DAS_RqActv "0000F003FFFE00FFh";
BA_ "FlexKomSigStartPos" SG_ 653 DAS_RqActv 7;
BA_ "FlexKomSigName" SG_ 653 DAS_RqActv "EBCM_C1_Pkt";
BA_ "FlexKomSigLaenge" SG_ 653 DAS_RqActv 64;
BA_ "FlexKomSID" SG_ 653 DAS_RqActv 9813;
BA_ "FlexKomIsMotorola" SG_ 653 DAS_RqActv 1;
BA_ "FlexKomComment" SG_ 653 DAS_RqActv "Message EBCM_C1 packet";
BA_ "GenSigSNA" SG_ 653 DriverBrakingTrue_EBCM "0h";
BA_ "GenSigCycleTime" SG_ 653 DriverBrakingTrue_EBCM 20;
BA_ "FlexKomSigStartValue" SG_ 653 DriverBrakingTrue_EBCM "0000F003FFFE00FFh";
BA_ "FlexKomSigStartPos" SG_ 653 DriverBrakingTrue_EBCM 7;
BA_ "FlexKomSigName" SG_ 653 DriverBrakingTrue_EBCM "EBCM_C1_Pkt";
BA_ "FlexKomSigLaenge" SG_ 653 DriverBrakingTrue_EBCM 64;
BA_ "FlexKomSID" SG_ 653 DriverBrakingTrue_EBCM 9813;
BA_ "FlexKomIsMotorola" SG_ 653 DriverBrakingTrue_EBCM 1;
BA_ "FlexKomComment" SG_ 653 DriverBrakingTrue_EBCM "Message EBCM_C1 packet";
BA_ "GenSigSNA" SG_ 653 EBCM_BrakeState "7h";
BA_ "GenSigCycleTime" SG_ 653 EBCM_BrakeState 20;
BA_ "FlexKomSigStartValue" SG_ 653 EBCM_BrakeState "0000F003FFFE00FFh";
BA_ "FlexKomSigStartPos" SG_ 653 EBCM_BrakeState 7;
BA_ "FlexKomSigName" SG_ 653 EBCM_BrakeState "EBCM_C1_Pkt";
BA_ "FlexKomSigLaenge" SG_ 653 EBCM_BrakeState 64;
BA_ "FlexKomSID" SG_ 653 EBCM_BrakeState 9813;
BA_ "FlexKomIsMotorola" SG_ 653 EBCM_BrakeState 1;
BA_ "FlexKomComment" SG_ 653 EBCM_BrakeState "Message EBCM_C1 packet";
BA_ "GenSigSNA" SG_ 653 EstBrakeTorqueAppliedSec "0h";
BA_ "GenSigCycleTime" SG_ 653 EstBrakeTorqueAppliedSec 20;
BA_ "FlexKomSigStartValue" SG_ 653 EstBrakeTorqueAppliedSec "0000F003FFFE00FFh";
BA_ "FlexKomSigStartPos" SG_ 653 EstBrakeTorqueAppliedSec 7;
BA_ "FlexKomSigName" SG_ 653 EstBrakeTorqueAppliedSec "EBCM_C1_Pkt";
BA_ "FlexKomSigLaenge" SG_ 653 EstBrakeTorqueAppliedSec 64;
BA_ "FlexKomSID" SG_ 653 EstBrakeTorqueAppliedSec 9813;
BA_ "FlexKomIsMotorola" SG_ 653 EstBrakeTorqueAppliedSec 1;
BA_ "FlexKomComment" SG_ 653 EstBrakeTorqueAppliedSec "Message EBCM_C1 packet";
BA_ "GenSigSNA" SG_ 653 MC_EBCM_C1 "0h";
BA_ "GenSigCycleTime" SG_ 653 MC_EBCM_C1 20;
BA_ "FlexKomSigStartValue" SG_ 653 MC_EBCM_C1 "0000F003FFFE00FFh";
BA_ "FlexKomSigStartPos" SG_ 653 MC_EBCM_C1 7;
BA_ "FlexKomSigName" SG_ 653 MC_EBCM_C1 "EBCM_C1_Pkt";
BA_ "FlexKomSigLaenge" SG_ 653 MC_EBCM_C1 64;
BA_ "FlexKomSID" SG_ 653 MC_EBCM_C1 9813;
BA_ "FlexKomIsMotorola" SG_ 653 MC_EBCM_C1 1;
BA_ "FlexKomComment" SG_ 653 MC_EBCM_C1 "Message EBCM_C1 packet";
BA_ "GenSigSNA" SG_ 653 SDS_Engaged_State_EBCM "3h";
BA_ "GenSigCycleTime" SG_ 653 SDS_Engaged_State_EBCM 20;
BA_ "FlexKomSigStartValue" SG_ 653 SDS_Engaged_State_EBCM "0000F003FFFE00FFh";
BA_ "FlexKomSigStartPos" SG_ 653 SDS_Engaged_State_EBCM 7;
BA_ "FlexKomSigName" SG_ 653 SDS_Engaged_State_EBCM "EBCM_C1_Pkt";
BA_ "FlexKomSigLaenge" SG_ 653 SDS_Engaged_State_EBCM 64;
BA_ "FlexKomSID" SG_ 653 SDS_Engaged_State_EBCM 9813;
BA_ "FlexKomIsMotorola" SG_ 653 SDS_Engaged_State_EBCM 1;
BA_ "FlexKomComment" SG_ 653 SDS_Engaged_State_EBCM "Message EBCM_C1 packet";
BA_ "GenSigSNA" SG_ 653 ThermalCapacitySec "0h";
BA_ "GenSigCycleTime" SG_ 653 ThermalCapacitySec 20;
BA_ "FlexKomSigStartValue" SG_ 653 ThermalCapacitySec "0000F003FFFE00FFh";
BA_ "FlexKomSigStartPos" SG_ 653 ThermalCapacitySec 7;
BA_ "FlexKomSigName" SG_ 653 ThermalCapacitySec "EBCM_C1_Pkt";
BA_ "FlexKomSigLaenge" SG_ 653 ThermalCapacitySec 64;
BA_ "FlexKomSID" SG_ 653 ThermalCapacitySec 9813;
BA_ "FlexKomIsMotorola" SG_ 653 ThermalCapacitySec 1;
BA_ "FlexKomComment" SG_ 653 ThermalCapacitySec "Message EBCM_C1 packet";
BA_ "GenSigSNA" SG_ 257 AccelPdlPosn_OBD_ePT "0h";
BA_ "GenSigCycleTime" SG_ 257 AccelPdlPosn_OBD_ePT 100;
BA_ "FlexKomSigStartValue" SG_ 257 AccelPdlPosn_OBD_ePT "000000h";
BA_ "FlexKomSigStartPos" SG_ 257 AccelPdlPosn_OBD_ePT 7;
BA_ "FlexKomSigName" SG_ 257 AccelPdlPosn_OBD_ePT "ECM_OBD_ePT";
BA_ "FlexKomSigLaenge" SG_ 257 AccelPdlPosn_OBD_ePT 24;
BA_ "FlexKomSID" SG_ 257 AccelPdlPosn_OBD_ePT 2130708819;
BA_ "FlexKomIsMotorola" SG_ 257 AccelPdlPosn_OBD_ePT 1;
BA_ "FlexKomComment" SG_ 257 AccelPdlPosn_OBD_ePT "ECM_OBD_ePT";
BA_ "GenSigSNA" SG_ 257 EngLoad_OBD_ePT "0h";
BA_ "GenSigCycleTime" SG_ 257 EngLoad_OBD_ePT 100;
BA_ "FlexKomSigStartValue" SG_ 257 EngLoad_OBD_ePT "000000h";
BA_ "FlexKomSigStartPos" SG_ 257 EngLoad_OBD_ePT 7;
BA_ "FlexKomSigName" SG_ 257 EngLoad_OBD_ePT "ECM_OBD_ePT";
BA_ "FlexKomSigLaenge" SG_ 257 EngLoad_OBD_ePT 24;
BA_ "FlexKomSID" SG_ 257 EngLoad_OBD_ePT 2130708819;
BA_ "FlexKomIsMotorola" SG_ 257 EngLoad_OBD_ePT 1;
BA_ "FlexKomComment" SG_ 257 EngLoad_OBD_ePT "ECM_OBD_ePT";
BA_ "GenSigSNA" SG_ 259 ABSActive "0h";
BA_ "GenSigCycleTime" SG_ 259 ABSActive 10;
BA_ "FlexKomSigStartValue" SG_ 259 ABSActive "0000000000000000h";
BA_ "FlexKomSigStartPos" SG_ 259 ABSActive 7;
BA_ "FlexKomSigName" SG_ 259 ABSActive "ESC_10";
BA_ "FlexKomSigLaenge" SG_ 259 ABSActive 64;
BA_ "FlexKomSID" SG_ 259 ABSActive 2130708600;
BA_ "FlexKomIsMotorola" SG_ 259 ABSActive 1;
BA_ "FlexKomComment" SG_ 259 ABSActive ".";
BA_ "GenSigStartValue" SG_ 259 CRC_ESC_10 255;
BA_ "GenSigSNA" SG_ 259 CRC_ESC_10 "FFh";
BA_ "GenSigCycleTime" SG_ 259 CRC_ESC_10 10;
BA_ "FlexKomSigStartValue" SG_ 259 CRC_ESC_10 "00000140000000FFh";
BA_ "FlexKomSigStartPos" SG_ 259 CRC_ESC_10 7;
BA_ "FlexKomSigName" SG_ 259 CRC_ESC_10 "EBCM_10";
BA_ "FlexKomSigLaenge" SG_ 259 CRC_ESC_10 64;
BA_ "FlexKomSID" SG_ 259 CRC_ESC_10 2130708603;
BA_ "FlexKomIsMotorola" SG_ 259 CRC_ESC_10 1;
BA_ "FlexKomComment" SG_ 259 CRC_ESC_10 ".";
BA_ "GenSigSNA" SG_ 259 EbdActive "0h";
BA_ "GenSigCycleTime" SG_ 259 EbdActive 10;
BA_ "FlexKomSigStartValue" SG_ 259 EbdActive "0000000000000000h";
BA_ "FlexKomSigStartPos" SG_ 259 EbdActive 7;
BA_ "FlexKomSigName" SG_ 259 EbdActive "ESC_10";
BA_ "FlexKomSigLaenge" SG_ 259 EbdActive 64;
BA_ "FlexKomSID" SG_ 259 EbdActive 2130708600;
BA_ "FlexKomIsMotorola" SG_ 259 EbdActive 1;
BA_ "FlexKomComment" SG_ 259 EbdActive ".";
BA_ "GenSigSNA" SG_ 259 ForceBlendingActive "0h";
BA_ "GenSigCycleTime" SG_ 259 ForceBlendingActive 10;
BA_ "FlexKomSigStartValue" SG_ 259 ForceBlendingActive "0000000000000000h";
BA_ "FlexKomSigStartPos" SG_ 259 ForceBlendingActive 7;
BA_ "FlexKomSigName" SG_ 259 ForceBlendingActive "ESC_10";
BA_ "FlexKomSigLaenge" SG_ 259 ForceBlendingActive 64;
BA_ "FlexKomSID" SG_ 259 ForceBlendingActive 2130708600;
BA_ "FlexKomIsMotorola" SG_ 259 ForceBlendingActive 1;
BA_ "FlexKomComment" SG_ 259 ForceBlendingActive ".";
BA_ "GenSigSNA" SG_ 259 MC_ESC_10 "Fh";
BA_ "GenSigCycleTime" SG_ 259 MC_ESC_10 10;
BA_ "FlexKomSigStartValue" SG_ 259 MC_ESC_10 "00000140000000FFh";
BA_ "FlexKomSigStartPos" SG_ 259 MC_ESC_10 7;
BA_ "FlexKomSigName" SG_ 259 MC_ESC_10 "EBCM_10";
BA_ "FlexKomSigLaenge" SG_ 259 MC_ESC_10 64;
BA_ "FlexKomSID" SG_ 259 MC_ESC_10 2130708603;
BA_ "FlexKomIsMotorola" SG_ 259 MC_ESC_10 1;
BA_ "FlexKomComment" SG_ 259 MC_ESC_10 ".";
BA_ "GenSigSNA" SG_ 259 pForceBlendingMC "0h";
BA_ "GenSigCycleTime" SG_ 259 pForceBlendingMC 10;
BA_ "FlexKomSigStartValue" SG_ 259 pForceBlendingMC "0000000000000000h";
BA_ "FlexKomSigStartPos" SG_ 259 pForceBlendingMC 7;
BA_ "FlexKomSigName" SG_ 259 pForceBlendingMC "ESC_10";
BA_ "FlexKomSigLaenge" SG_ 259 pForceBlendingMC 64;
BA_ "FlexKomSID" SG_ 259 pForceBlendingMC 2130708600;
BA_ "FlexKomIsMotorola" SG_ 259 pForceBlendingMC 1;
BA_ "FlexKomComment" SG_ 259 pForceBlendingMC ".";
BA_ "GenSigSNA" SG_ 259 pMC1 "0h";
BA_ "GenSigCycleTime" SG_ 259 pMC1 10;
BA_ "FlexKomSigStartValue" SG_ 259 pMC1 "0000000000000000h";
BA_ "FlexKomSigStartPos" SG_ 259 pMC1 7;
BA_ "FlexKomSigName" SG_ 259 pMC1 "ESC_10";
BA_ "FlexKomSigLaenge" SG_ 259 pMC1 64;
BA_ "FlexKomSID" SG_ 259 pMC1 2130708600;
BA_ "FlexKomIsMotorola" SG_ 259 pMC1 1;
BA_ "FlexKomComment" SG_ 259 pMC1 ".";
BA_ "GenSigSNA" SG_ 259 pMC1_Qualifier "0h";
BA_ "GenSigCycleTime" SG_ 259 pMC1_Qualifier 10;
BA_ "FlexKomSigStartValue" SG_ 259 pMC1_Qualifier "0000000000000000h";
BA_ "FlexKomSigStartPos" SG_ 259 pMC1_Qualifier 7;
BA_ "FlexKomSigName" SG_ 259 pMC1_Qualifier "ESC_10";
BA_ "FlexKomSigLaenge" SG_ 259 pMC1_Qualifier 64;
BA_ "FlexKomSID" SG_ 259 pMC1_Qualifier 2130708600;
BA_ "FlexKomIsMotorola" SG_ 259 pMC1_Qualifier 1;
BA_ "FlexKomComment" SG_ 259 pMC1_Qualifier ".";
BA_ "GenSigSNA" SG_ 259 pMCVirtual "0h";
BA_ "GenSigCycleTime" SG_ 259 pMCVirtual 10;
BA_ "FlexKomSigStartValue" SG_ 259 pMCVirtual "0000000000000000h";
BA_ "FlexKomSigStartPos" SG_ 259 pMCVirtual 7;
BA_ "FlexKomSigName" SG_ 259 pMCVirtual "ESC_10";
BA_ "FlexKomSigLaenge" SG_ 259 pMCVirtual 64;
BA_ "FlexKomSID" SG_ 259 pMCVirtual 2130708600;
BA_ "FlexKomIsMotorola" SG_ 259 pMCVirtual 1;
BA_ "FlexKomComment" SG_ 259 pMCVirtual ".";
BA_ "GenSigSNA" SG_ 259 pMCVirtual_Qualifier "0h";
BA_ "GenSigCycleTime" SG_ 259 pMCVirtual_Qualifier 10;
BA_ "FlexKomSigStartValue" SG_ 259 pMCVirtual_Qualifier "0000000000000000h";
BA_ "FlexKomSigStartPos" SG_ 259 pMCVirtual_Qualifier 7;
BA_ "FlexKomSigName" SG_ 259 pMCVirtual_Qualifier "ESC_10";
BA_ "FlexKomSigLaenge" SG_ 259 pMCVirtual_Qualifier 64;
BA_ "FlexKomSID" SG_ 259 pMCVirtual_Qualifier 2130708600;
BA_ "FlexKomIsMotorola" SG_ 259 pMCVirtual_Qualifier 1;
BA_ "FlexKomComment" SG_ 259 pMCVirtual_Qualifier ".";
BA_ "GenSigStartValue" SG_ 516 CRC_ESC_20 255;
BA_ "GenSigSNA" SG_ 516 CRC_ESC_20 "FFh";
BA_ "GenSigCycleTime" SG_ 516 CRC_ESC_20 20;
BA_ "FlexKomSigStartValue" SG_ 516 CRC_ESC_20 "F0000000000000FFh";
BA_ "FlexKomSigStartPos" SG_ 516 CRC_ESC_20 7;
BA_ "FlexKomSigName" SG_ 516 CRC_ESC_20 "ESC_20";
BA_ "FlexKomSigLaenge" SG_ 516 CRC_ESC_20 64;
BA_ "FlexKomSID" SG_ 516 CRC_ESC_20 2130708602;
BA_ "FlexKomIsMotorola" SG_ 516 CRC_ESC_20 1;
BA_ "FlexKomComment" SG_ 516 CRC_ESC_20 ".";
BA_ "GenSigSNA" SG_ 516 ImpendingSkid "0h";
BA_ "GenSigCycleTime" SG_ 516 ImpendingSkid 20;
BA_ "FlexKomSigStartValue" SG_ 516 ImpendingSkid "F0000000000000FFh";
BA_ "FlexKomSigStartPos" SG_ 516 ImpendingSkid 7;
BA_ "FlexKomSigName" SG_ 516 ImpendingSkid "ESC_20";
BA_ "FlexKomSigLaenge" SG_ 516 ImpendingSkid 64;
BA_ "FlexKomSID" SG_ 516 ImpendingSkid 2130708602;
BA_ "FlexKomIsMotorola" SG_ 516 ImpendingSkid 1;
BA_ "FlexKomComment" SG_ 516 ImpendingSkid ".";
BA_ "GenSigSNA" SG_ 516 MC_ESC_20 "0h";
BA_ "GenSigCycleTime" SG_ 516 MC_ESC_20 20;
BA_ "FlexKomSigStartValue" SG_ 516 MC_ESC_20 "F0000000000000FFh";
BA_ "FlexKomSigStartPos" SG_ 516 MC_ESC_20 7;
BA_ "FlexKomSigName" SG_ 516 MC_ESC_20 "ESC_20";
BA_ "FlexKomSigLaenge" SG_ 516 MC_ESC_20 64;
BA_ "FlexKomSID" SG_ 516 MC_ESC_20 2130708602;
BA_ "FlexKomIsMotorola" SG_ 516 MC_ESC_20 1;
BA_ "FlexKomComment" SG_ 516 MC_ESC_20 ".";
BA_ "GenSigSNA" SG_ 516 ShiftInhibit "0h";
BA_ "GenSigCycleTime" SG_ 516 ShiftInhibit 20;
BA_ "FlexKomSigStartValue" SG_ 516 ShiftInhibit "F0000000000000FFh";
BA_ "FlexKomSigStartPos" SG_ 516 ShiftInhibit 7;
BA_ "FlexKomSigName" SG_ 516 ShiftInhibit "ESC_20";
BA_ "FlexKomSigLaenge" SG_ 516 ShiftInhibit 64;
BA_ "FlexKomSID" SG_ 516 ShiftInhibit 2130708602;
BA_ "FlexKomIsMotorola" SG_ 516 ShiftInhibit 1;
BA_ "FlexKomComment" SG_ 516 ShiftInhibit ".";
BA_ "GenSigSNA" SG_ 516 pEstMax "0h";
BA_ "GenSigCycleTime" SG_ 516 pEstMax 20;
BA_ "FlexKomSigStartValue" SG_ 516 pEstMax "F0000000000000FFh";
BA_ "FlexKomSigStartPos" SG_ 516 pEstMax 7;
BA_ "FlexKomSigName" SG_ 516 pEstMax "ESC_20";
BA_ "FlexKomSigLaenge" SG_ 516 pEstMax 64;
BA_ "FlexKomSID" SG_ 516 pEstMax 2130708602;
BA_ "FlexKomIsMotorola" SG_ 516 pEstMax 1;
BA_ "FlexKomComment" SG_ 516 pEstMax ".";
BA_ "GenSigSNA" SG_ 516 pMC1_ESC_20 "0h";
BA_ "GenSigCycleTime" SG_ 516 pMC1_ESC_20 20;
BA_ "FlexKomSigStartValue" SG_ 516 pMC1_ESC_20 "F0000000000000FFh";
BA_ "FlexKomSigStartPos" SG_ 516 pMC1_ESC_20 7;
BA_ "FlexKomSigName" SG_ 516 pMC1_ESC_20 "ESC_20";
BA_ "FlexKomSigLaenge" SG_ 516 pMC1_ESC_20 64;
BA_ "FlexKomSID" SG_ 516 pMC1_ESC_20 2130708602;
BA_ "FlexKomIsMotorola" SG_ 516 pMC1_ESC_20 1;
BA_ "FlexKomComment" SG_ 516 pMC1_ESC_20 ".";
BA_ "GenSigSNA" SG_ 516 pMC1Target "0h";
BA_ "GenSigCycleTime" SG_ 516 pMC1Target 20;
BA_ "FlexKomSigStartValue" SG_ 516 pMC1Target "F0000000000000FFh";
BA_ "FlexKomSigStartPos" SG_ 516 pMC1Target 7;
BA_ "FlexKomSigName" SG_ 516 pMC1Target "ESC_20";
BA_ "FlexKomSigLaenge" SG_ 516 pMC1Target 64;
BA_ "FlexKomSID" SG_ 516 pMC1Target 2130708602;
BA_ "FlexKomIsMotorola" SG_ 516 pMC1Target 1;
BA_ "FlexKomComment" SG_ 516 pMC1Target ".";
BA_ "GenSigSNA" SG_ 516 pMC2 "0h";
BA_ "GenSigCycleTime" SG_ 516 pMC2 20;
BA_ "FlexKomSigStartValue" SG_ 516 pMC2 "F0000000000000FFh";
BA_ "FlexKomSigStartPos" SG_ 516 pMC2 7;
BA_ "FlexKomSigName" SG_ 516 pMC2 "ESC_20";
BA_ "FlexKomSigLaenge" SG_ 516 pMC2 64;
BA_ "FlexKomSID" SG_ 516 pMC2 2130708602;
BA_ "FlexKomIsMotorola" SG_ 516 pMC2 1;
BA_ "FlexKomComment" SG_ 516 pMC2 ".";
BA_ "GenSigSNA" SG_ 320 ABS_BrkEvt "0h";
BA_ "GenSigCycleTime" SG_ 320 ABS_BrkEvt 20;
BA_ "FlexKomSigStartValue" SG_ 320 ABS_BrkEvt "0F3400C003FF00FFh";
BA_ "FlexKomSigStartPos" SG_ 320 ABS_BrkEvt 7;
BA_ "FlexKomSigName" SG_ 320 ABS_BrkEvt "ESP_BRK_STAT";
BA_ "FlexKomSigLaenge" SG_ 320 ABS_BrkEvt 64;
BA_ "FlexKomIsMotorola" SG_ 320 ABS_BrkEvt 1;
BA_ "FlexKomComment" SG_ 320 ABS_BrkEvt "ESP Brake Status Information";
BA_ "GenSigSNA" SG_ 320 BrkIntrvntn_Actv_AS "0h";
BA_ "GenSigCycleTime" SG_ 320 BrkIntrvntn_Actv_AS 20;
BA_ "FlexKomSigStartValue" SG_ 320 BrkIntrvntn_Actv_AS "0F3400C003FF00FFh";
BA_ "FlexKomSigStartPos" SG_ 320 BrkIntrvntn_Actv_AS 7;
BA_ "FlexKomSigName" SG_ 320 BrkIntrvntn_Actv_AS "ESP_BRK_STAT";
BA_ "FlexKomSigLaenge" SG_ 320 BrkIntrvntn_Actv_AS 64;
BA_ "FlexKomIsMotorola" SG_ 320 BrkIntrvntn_Actv_AS 1;
BA_ "FlexKomComment" SG_ 320 BrkIntrvntn_Actv_AS "ESP Brake Status Information";
BA_ "GenSigSNA" SG_ 320 BrkIntrvntn_Enbl "0h";
BA_ "GenSigCycleTime" SG_ 320 BrkIntrvntn_Enbl 20;
BA_ "FlexKomSigStartValue" SG_ 320 BrkIntrvntn_Enbl "0F3400C003FF00FFh";
BA_ "FlexKomSigStartPos" SG_ 320 BrkIntrvntn_Enbl 7;
BA_ "FlexKomSigName" SG_ 320 BrkIntrvntn_Enbl "ESP_BRK_STAT";
BA_ "FlexKomSigLaenge" SG_ 320 BrkIntrvntn_Enbl 64;
BA_ "FlexKomIsMotorola" SG_ 320 BrkIntrvntn_Enbl 1;
BA_ "FlexKomComment" SG_ 320 BrkIntrvntn_Enbl "ESP Brake Status Information";
BA_ "GenSigSNA" SG_ 320 BrkPdl_Flt "0h";
BA_ "GenSigCycleTime" SG_ 320 BrkPdl_Flt 20;
BA_ "FlexKomSigStartValue" SG_ 320 BrkPdl_Flt "0F3400C003FF00FFh";
BA_ "FlexKomSigStartPos" SG_ 320 BrkPdl_Flt 7;
BA_ "FlexKomSigName" SG_ 320 BrkPdl_Flt "ESP_BRK_STAT";
BA_ "FlexKomSigLaenge" SG_ 320 BrkPdl_Flt 64;
BA_ "FlexKomIsMotorola" SG_ 320 BrkPdl_Flt 1;
BA_ "FlexKomComment" SG_ 320 BrkPdl_Flt "ESP Brake Status Information";
BA_ "GenSigStartValue" SG_ 320 BrkPdl_Stat 3;
BA_ "GenSigSNA" SG_ 320 BrkPdl_Stat "3h";
BA_ "GenSigCycleTime" SG_ 320 BrkPdl_Stat 20;
BA_ "FlexKomSigStartValue" SG_ 320 BrkPdl_Stat "0F3400C003FF00FFh";
BA_ "FlexKomSigStartPos" SG_ 320 BrkPdl_Stat 7;
BA_ "FlexKomSigName" SG_ 320 BrkPdl_Stat "ESP_BRK_STAT";
BA_ "FlexKomSigLaenge" SG_ 320 BrkPdl_Stat 64;
BA_ "FlexKomIsMotorola" SG_ 320 BrkPdl_Stat 1;
BA_ "FlexKomComment" SG_ 320 BrkPdl_Stat "ESP Brake Status Information";
BA_ "GenSigStartValue" SG_ 320 Brk_Stat 3;
BA_ "GenSigSNA" SG_ 320 Brk_Stat "3h";
BA_ "GenSigCycleTime" SG_ 320 Brk_Stat 20;
BA_ "FlexKomSigStartValue" SG_ 320 Brk_Stat "0F3400C003FF00FFh";
BA_ "FlexKomSigStartPos" SG_ 320 Brk_Stat 7;
BA_ "FlexKomSigName" SG_ 320 Brk_Stat "ESP_BRK_STAT";
BA_ "FlexKomSigLaenge" SG_ 320 Brk_Stat 64;
BA_ "FlexKomIsMotorola" SG_ 320 Brk_Stat 1;
BA_ "FlexKomComment" SG_ 320 Brk_Stat "ESP Brake Status Information";
BA_ "GenSigSNA" SG_ 320 Brk_Thermdl "0h";
BA_ "GenSigCycleTime" SG_ 320 Brk_Thermdl 20;
BA_ "FlexKomSigStartValue" SG_ 320 Brk_Thermdl "0F3400C003FF00FFh";
BA_ "FlexKomSigStartPos" SG_ 320 Brk_Thermdl 7;
BA_ "FlexKomSigName" SG_ 320 Brk_Thermdl "ESP_BRK_STAT";
BA_ "FlexKomSigLaenge" SG_ 320 Brk_Thermdl 64;
BA_ "FlexKomIsMotorola" SG_ 320 Brk_Thermdl 1;
BA_ "FlexKomComment" SG_ 320 Brk_Thermdl "ESP Brake Status Information";
BA_ "GenSigStartValue" SG_ 320 CRC_Brk_Stat 255;
BA_ "GenSigSNA" SG_ 320 CRC_Brk_Stat "FFh";
BA_ "GenSigCycleTime" SG_ 320 CRC_Brk_Stat 20;
BA_ "FlexKomSigStartValue" SG_ 320 CRC_Brk_Stat "0F3400C003FF00FFh";
BA_ "FlexKomSigStartPos" SG_ 320 CRC_Brk_Stat 7;
BA_ "FlexKomSigName" SG_ 320 CRC_Brk_Stat "ESP_BRK_STAT";
BA_ "FlexKomSigLaenge" SG_ 320 CRC_Brk_Stat 64;
BA_ "FlexKomIsMotorola" SG_ 320 CRC_Brk_Stat 1;
BA_ "FlexKomComment" SG_ 320 CRC_Brk_Stat "ESP Brake Status Information";
BA_ "GenSigSNA" SG_ 320 MC_Brk_Stat "0h";
BA_ "GenSigCycleTime" SG_ 320 MC_Brk_Stat 20;
BA_ "FlexKomSigStartValue" SG_ 320 MC_Brk_Stat "0F3400C003FF00FFh";
BA_ "FlexKomSigStartPos" SG_ 320 MC_Brk_Stat 7;
BA_ "FlexKomSigName" SG_ 320 MC_Brk_Stat "ESP_BRK_STAT";
BA_ "FlexKomSigLaenge" SG_ 320 MC_Brk_Stat 64;
BA_ "FlexKomIsMotorola" SG_ 320 MC_Brk_Stat 1;
BA_ "FlexKomComment" SG_ 320 MC_Brk_Stat "ESP Brake Status Information";
BA_ "GenSigStartValue" SG_ 268 CRC_ENG_RQ_ESC 255;
BA_ "GenSigSNA" SG_ 268 CRC_ENG_RQ_ESC "FFh";
BA_ "GenSigCycleTime" SG_ 268 CRC_ENG_RQ_ESC 20;
BA_ "FlexKomSigStartValue" SG_ 268 CRC_ENG_RQ_ESC "00000000FF0000FFh";
BA_ "FlexKomSigStartPos" SG_ 268 CRC_ENG_RQ_ESC 7;
BA_ "FlexKomSigName" SG_ 268 CRC_ENG_RQ_ESC "Eng_Trq_Rq";
BA_ "FlexKomSigLaenge" SG_ 268 CRC_ENG_RQ_ESC 64;
BA_ "FlexKomSID" SG_ 268 CRC_ENG_RQ_ESC 9820;
BA_ "FlexKomIsMotorola" SG_ 268 CRC_ENG_RQ_ESC 1;
BA_ "FlexKomComment" SG_ 268 CRC_ENG_RQ_ESC "Engine torque request from ESC";
BA_ "GenSigSNA" SG_ 268 DAS_RqActv "7h";
BA_ "GenSigCycleTime" SG_ 268 DAS_RqActv 20;
BA_ "FlexKomSigStartValue" SG_ 268 DAS_RqActv "00000000FF0000FFh";
BA_ "FlexKomSigStartPos" SG_ 268 DAS_RqActv 7;
BA_ "FlexKomSigName" SG_ 268 DAS_RqActv "Eng_Trq_Rq";
BA_ "FlexKomSigLaenge" SG_ 268 DAS_RqActv 64;
BA_ "FlexKomSID" SG_ 268 DAS_RqActv 9820;
BA_ "FlexKomIsMotorola" SG_ 268 DAS_RqActv 1;
BA_ "FlexKomComment" SG_ 268 DAS_RqActv "Engine torque request from ESC";
BA_ "GenSigSNA" SG_ 268 MC_ENG_RQ_ESC "0h";
BA_ "GenSigCycleTime" SG_ 268 MC_ENG_RQ_ESC 20;
BA_ "FlexKomSigStartValue" SG_ 268 MC_ENG_RQ_ESC "00000000FF0000FFh";
BA_ "FlexKomSigStartPos" SG_ 268 MC_ENG_RQ_ESC 7;
BA_ "FlexKomSigName" SG_ 268 MC_ENG_RQ_ESC "Eng_Trq_Rq";
BA_ "FlexKomSigLaenge" SG_ 268 MC_ENG_RQ_ESC 64;
BA_ "FlexKomSID" SG_ 268 MC_ENG_RQ_ESC 9820;
BA_ "FlexKomIsMotorola" SG_ 268 MC_ENG_RQ_ESC 1;
BA_ "FlexKomComment" SG_ 268 MC_ENG_RQ_ESC "Engine torque request from ESC";
BA_ "GenSigSNA" SG_ 292 WhlPlsCnt_FL "FFh";
BA_ "GenSigCycleTime" SG_ 292 WhlPlsCnt_FL 20;
BA_ "FlexKomSigStartValue" SG_ 292 WhlPlsCnt_FL "00000000h";
BA_ "FlexKomSigStartPos" SG_ 292 WhlPlsCnt_FL 7;
BA_ "FlexKomSigName" SG_ 292 WhlPlsCnt_FL "ESP_WHL_PULS";
BA_ "FlexKomSigLaenge" SG_ 292 WhlPlsCnt_FL 32;
BA_ "FlexKomSID" SG_ 292 WhlPlsCnt_FL 9004;
BA_ "FlexKomIsMotorola" SG_ 292 WhlPlsCnt_FL 1;
BA_ "FlexKomComment" SG_ 292 WhlPlsCnt_FL "ESP Wheel pulse counts";
BA_ "GenSigSNA" SG_ 292 WhlPlsCnt_FR "FFh";
BA_ "GenSigCycleTime" SG_ 292 WhlPlsCnt_FR 20;
BA_ "FlexKomSigStartValue" SG_ 292 WhlPlsCnt_FR "00000000h";
BA_ "FlexKomSigStartPos" SG_ 292 WhlPlsCnt_FR 7;
BA_ "FlexKomSigName" SG_ 292 WhlPlsCnt_FR "ESP_WHL_PULS";
BA_ "FlexKomSigLaenge" SG_ 292 WhlPlsCnt_FR 32;
BA_ "FlexKomSID" SG_ 292 WhlPlsCnt_FR 9004;
BA_ "FlexKomIsMotorola" SG_ 292 WhlPlsCnt_FR 1;
BA_ "FlexKomComment" SG_ 292 WhlPlsCnt_FR "ESP Wheel pulse counts";
BA_ "GenSigSNA" SG_ 292 WhlPlsCnt_RL "FFh";
BA_ "GenSigCycleTime" SG_ 292 WhlPlsCnt_RL 20;
BA_ "FlexKomSigStartValue" SG_ 292 WhlPlsCnt_RL "00000000h";
BA_ "FlexKomSigStartPos" SG_ 292 WhlPlsCnt_RL 7;
BA_ "FlexKomSigName" SG_ 292 WhlPlsCnt_RL "ESP_WHL_PULS";
BA_ "FlexKomSigLaenge" SG_ 292 WhlPlsCnt_RL 32;
BA_ "FlexKomSID" SG_ 292 WhlPlsCnt_RL 9004;
BA_ "FlexKomIsMotorola" SG_ 292 WhlPlsCnt_RL 1;
BA_ "FlexKomComment" SG_ 292 WhlPlsCnt_RL "ESP Wheel pulse counts";
BA_ "GenSigSNA" SG_ 292 WhlPlsCnt_RR "FFh";
BA_ "GenSigCycleTime" SG_ 292 WhlPlsCnt_RR 20;
BA_ "FlexKomSigStartValue" SG_ 292 WhlPlsCnt_RR "00000000h";
BA_ "FlexKomSigStartPos" SG_ 292 WhlPlsCnt_RR 7;
BA_ "FlexKomSigName" SG_ 292 WhlPlsCnt_RR "ESP_WHL_PULS";
BA_ "FlexKomSigLaenge" SG_ 292 WhlPlsCnt_RR 32;
BA_ "FlexKomSID" SG_ 292 WhlPlsCnt_RR 9004;
BA_ "FlexKomIsMotorola" SG_ 292 WhlPlsCnt_RR 1;
BA_ "FlexKomComment" SG_ 292 WhlPlsCnt_RR "ESP Wheel pulse counts";
BA_ "GenSigStartValue" SG_ 344 WhlDir_FL_Stat 3;
BA_ "GenSigSNA" SG_ 344 WhlDir_FL_Stat "3h";
BA_ "GenSigCycleTime" SG_ 344 WhlDir_FL_Stat 20;
BA_ "FlexKomSigStartValue" SG_ 344 WhlDir_FL_Stat "FFFFFFFFFFFFFFFFh";
BA_ "FlexKomSigStartPos" SG_ 344 WhlDir_FL_Stat 7;
BA_ "FlexKomSigName" SG_ 344 WhlDir_FL_Stat "WHEEL_SPEED";
BA_ "FlexKomSigLaenge" SG_ 344 WhlDir_FL_Stat 64;
BA_ "FlexKomSID" SG_ 344 WhlDir_FL_Stat 64;
BA_ "FlexKomIsMotorola" SG_ 344 WhlDir_FL_Stat 1;
BA_ "FlexKomComment" SG_ 344 WhlDir_FL_Stat "ESP Wheel Speed";
BA_ "GenSigStartValue" SG_ 344 WhlDir_FR_Stat 3;
BA_ "GenSigSNA" SG_ 344 WhlDir_FR_Stat "3h";
BA_ "GenSigCycleTime" SG_ 344 WhlDir_FR_Stat 20;
BA_ "FlexKomSigStartValue" SG_ 344 WhlDir_FR_Stat "FFFFFFFFFFFFFFFFh";
BA_ "FlexKomSigStartPos" SG_ 344 WhlDir_FR_Stat 7;
BA_ "FlexKomSigName" SG_ 344 WhlDir_FR_Stat "WHEEL_SPEED";
BA_ "FlexKomSigLaenge" SG_ 344 WhlDir_FR_Stat 64;
BA_ "FlexKomSID" SG_ 344 WhlDir_FR_Stat 64;
BA_ "FlexKomIsMotorola" SG_ 344 WhlDir_FR_Stat 1;
BA_ "FlexKomComment" SG_ 344 WhlDir_FR_Stat "ESP Wheel Speed";
BA_ "GenSigStartValue" SG_ 344 WhlDir_RL_Stat 3;
BA_ "GenSigSNA" SG_ 344 WhlDir_RL_Stat "3h";
BA_ "GenSigCycleTime" SG_ 344 WhlDir_RL_Stat 20;
BA_ "FlexKomSigStartValue" SG_ 344 WhlDir_RL_Stat "FFFFFFFFFFFFFFFFh";
BA_ "FlexKomSigStartPos" SG_ 344 WhlDir_RL_Stat 7;
BA_ "FlexKomSigName" SG_ 344 WhlDir_RL_Stat "WHEEL_SPEED";
BA_ "FlexKomSigLaenge" SG_ 344 WhlDir_RL_Stat 64;
BA_ "FlexKomSID" SG_ 344 WhlDir_RL_Stat 64;
BA_ "FlexKomIsMotorola" SG_ 344 WhlDir_RL_Stat 1;
BA_ "FlexKomComment" SG_ 344 WhlDir_RL_Stat "ESP Wheel Speed";
BA_ "GenSigStartValue" SG_ 344 WhlDir_RR_Stat 3;
BA_ "GenSigSNA" SG_ 344 WhlDir_RR_Stat "3h";
BA_ "GenSigCycleTime" SG_ 344 WhlDir_RR_Stat 20;
BA_ "FlexKomSigStartValue" SG_ 344 WhlDir_RR_Stat "FFFFFFFFFFFFFFFFh";
BA_ "FlexKomSigStartPos" SG_ 344 WhlDir_RR_Stat 7;
BA_ "FlexKomSigName" SG_ 344 WhlDir_RR_Stat "WHEEL_SPEED";
BA_ "FlexKomSigLaenge" SG_ 344 WhlDir_RR_Stat 64;
BA_ "FlexKomSID" SG_ 344 WhlDir_RR_Stat 64;
BA_ "FlexKomIsMotorola" SG_ 344 WhlDir_RR_Stat 1;
BA_ "FlexKomComment" SG_ 344 WhlDir_RR_Stat "ESP Wheel Speed";
BA_ "GenSigStartValue" SG_ 344 WhlRPM_FL 16383;
BA_ "GenSigSNA" SG_ 344 WhlRPM_FL "3FFFh";
BA_ "GenSigCycleTime" SG_ 344 WhlRPM_FL 20;
BA_ "FlexKomSigStartValue" SG_ 344 WhlRPM_FL "FFFFFFFFFFFFFFFFh";
BA_ "FlexKomSigStartPos" SG_ 344 WhlRPM_FL 7;
BA_ "FlexKomSigName" SG_ 344 WhlRPM_FL "WHEEL_SPEED";
BA_ "FlexKomSigLaenge" SG_ 344 WhlRPM_FL 64;
BA_ "FlexKomSID" SG_ 344 WhlRPM_FL 64;
BA_ "FlexKomIsMotorola" SG_ 344 WhlRPM_FL 1;
BA_ "FlexKomComment" SG_ 344 WhlRPM_FL "ESP Wheel Speed";
BA_ "GenSigStartValue" SG_ 344 WhlRPM_FR 16383;
BA_ "GenSigSNA" SG_ 344 WhlRPM_FR "3FFFh";
BA_ "GenSigCycleTime" SG_ 344 WhlRPM_FR 20;
BA_ "FlexKomSigStartValue" SG_ 344 WhlRPM_FR "FFFFFFFFFFFFFFFFh";
BA_ "FlexKomSigStartPos" SG_ 344 WhlRPM_FR 7;
BA_ "FlexKomSigName" SG_ 344 WhlRPM_FR "WHEEL_SPEED";
BA_ "FlexKomSigLaenge" SG_ 344 WhlRPM_FR 64;
BA_ "FlexKomSID" SG_ 344 WhlRPM_FR 64;
BA_ "FlexKomIsMotorola" SG_ 344 WhlRPM_FR 1;
BA_ "FlexKomComment" SG_ 344 WhlRPM_FR "ESP Wheel Speed";
BA_ "GenSigStartValue" SG_ 344 WhlRPM_RL 16383;
BA_ "GenSigSNA" SG_ 344 WhlRPM_RL "3FFFh";
BA_ "GenSigCycleTime" SG_ 344 WhlRPM_RL 20;
BA_ "FlexKomSigStartValue" SG_ 344 WhlRPM_RL "FFFFFFFFFFFFFFFFh";
BA_ "FlexKomSigStartPos" SG_ 344 WhlRPM_RL 7;
BA_ "FlexKomSigName" SG_ 344 WhlRPM_RL "WHEEL_SPEED";
BA_ "FlexKomSigLaenge" SG_ 344 WhlRPM_RL 64;
BA_ "FlexKomSID" SG_ 344 WhlRPM_RL 64;
BA_ "FlexKomIsMotorola" SG_ 344 WhlRPM_RL 1;
BA_ "FlexKomComment" SG_ 344 WhlRPM_RL "ESP Wheel Speed";
BA_ "GenSigStartValue" SG_ 344 WhlRPM_RR 16383;
BA_ "GenSigSNA" SG_ 344 WhlRPM_RR "3FFFh";
BA_ "GenSigCycleTime" SG_ 344 WhlRPM_RR 20;
BA_ "FlexKomSigStartValue" SG_ 344 WhlRPM_RR "FFFFFFFFFFFFFFFFh";
BA_ "FlexKomSigStartPos" SG_ 344 WhlRPM_RR 7;
BA_ "FlexKomSigName" SG_ 344 WhlRPM_RR "WHEEL_SPEED";
BA_ "FlexKomSigLaenge" SG_ 344 WhlRPM_RR 64;
BA_ "FlexKomSID" SG_ 344 WhlRPM_RR 64;
BA_ "FlexKomIsMotorola" SG_ 344 WhlRPM_RR 1;
BA_ "FlexKomComment" SG_ 344 WhlRPM_RR "ESP Wheel Speed";
BA_ "GenSigSNA" SG_ 682 BrakeSysStatePrim "7h";
BA_ "GenSigCycleTime" SG_ 682 BrakeSysStatePrim 10;
BA_ "FlexKomSigStartValue" SG_ 682 BrakeSysStatePrim "FFFF8000000000FFh";
BA_ "FlexKomSigStartPos" SG_ 682 BrakeSysStatePrim 7;
BA_ "FlexKomSigName" SG_ 682 BrakeSysStatePrim "ESP_B5_Pkt";
BA_ "FlexKomSigLaenge" SG_ 682 BrakeSysStatePrim 64;
BA_ "FlexKomSID" SG_ 682 BrakeSysStatePrim 9815;
BA_ "FlexKomIsMotorola" SG_ 682 BrakeSysStatePrim 1;
BA_ "FlexKomComment" SG_ 682 BrakeSysStatePrim "Message ESP_B5 packet";
BA_ "GenSigStartValue" SG_ 682 CRC_ESP_B5 255;
BA_ "GenSigSNA" SG_ 682 CRC_ESP_B5 "FFh";
BA_ "GenSigCycleTime" SG_ 682 CRC_ESP_B5 10;
BA_ "FlexKomSigStartValue" SG_ 682 CRC_ESP_B5 "FFFF8000000000FFh";
BA_ "FlexKomSigStartPos" SG_ 682 CRC_ESP_B5 7;
BA_ "FlexKomSigName" SG_ 682 CRC_ESP_B5 "ESP_B5_Pkt";
BA_ "FlexKomSigLaenge" SG_ 682 CRC_ESP_B5 64;
BA_ "FlexKomSID" SG_ 682 CRC_ESP_B5 9815;
BA_ "FlexKomIsMotorola" SG_ 682 CRC_ESP_B5 1;
BA_ "FlexKomComment" SG_ 682 CRC_ESP_B5 "Message ESP_B5 packet";
BA_ "GenSigSNA" SG_ 682 ESC_BrakeState "7h";
BA_ "GenSigCycleTime" SG_ 682 ESC_BrakeState 10;
BA_ "FlexKomSigStartValue" SG_ 682 ESC_BrakeState "FFFF8000000000FFh";
BA_ "FlexKomSigStartPos" SG_ 682 ESC_BrakeState 7;
BA_ "FlexKomSigName" SG_ 682 ESC_BrakeState "ESP_B5_Pkt";
BA_ "FlexKomSigLaenge" SG_ 682 ESC_BrakeState 64;
BA_ "FlexKomSID" SG_ 682 ESC_BrakeState 9815;
BA_ "FlexKomIsMotorola" SG_ 682 ESC_BrakeState 1;
BA_ "FlexKomComment" SG_ 682 ESC_BrakeState "Message ESP_B5 packet";
BA_ "GenSigSNA" SG_ 682 EsBrakeTorqueAppliedPrim "0h";
BA_ "GenSigCycleTime" SG_ 682 EsBrakeTorqueAppliedPrim 10;
BA_ "FlexKomSigStartValue" SG_ 682 EsBrakeTorqueAppliedPrim "FFFF8000000000FFh";
BA_ "FlexKomSigStartPos" SG_ 682 EsBrakeTorqueAppliedPrim 7;
BA_ "FlexKomSigName" SG_ 682 EsBrakeTorqueAppliedPrim "ESP_B5_Pkt";
BA_ "FlexKomSigLaenge" SG_ 682 EsBrakeTorqueAppliedPrim 64;
BA_ "FlexKomSID" SG_ 682 EsBrakeTorqueAppliedPrim 9815;
BA_ "FlexKomIsMotorola" SG_ 682 EsBrakeTorqueAppliedPrim 1;
BA_ "FlexKomComment" SG_ 682 EsBrakeTorqueAppliedPrim "Message ESP_B5 packet";
BA_ "GenSigSNA" SG_ 682 HoldSufficientStatus "0h";
BA_ "GenSigCycleTime" SG_ 682 HoldSufficientStatus 10;
BA_ "FlexKomSigStartValue" SG_ 682 HoldSufficientStatus "FFFF8000000000FFh";
BA_ "FlexKomSigStartPos" SG_ 682 HoldSufficientStatus 7;
BA_ "FlexKomSigName" SG_ 682 HoldSufficientStatus "ESP_B5_Pkt";
BA_ "FlexKomSigLaenge" SG_ 682 HoldSufficientStatus 64;
BA_ "FlexKomSID" SG_ 682 HoldSufficientStatus 9815;
BA_ "FlexKomIsMotorola" SG_ 682 HoldSufficientStatus 1;
BA_ "FlexKomComment" SG_ 682 HoldSufficientStatus "Message ESP_B5 packet";
BA_ "GenSigSNA" SG_ 682 MC_ESP_B5 "0h";
BA_ "GenSigCycleTime" SG_ 682 MC_ESP_B5 10;
BA_ "FlexKomSigStartValue" SG_ 682 MC_ESP_B5 "FFFF8000000000FFh";
BA_ "FlexKomSigStartPos" SG_ 682 MC_ESP_B5 7;
BA_ "FlexKomSigName" SG_ 682 MC_ESP_B5 "ESP_B5_Pkt";
BA_ "FlexKomSigLaenge" SG_ 682 MC_ESP_B5 64;
BA_ "FlexKomSID" SG_ 682 MC_ESP_B5 9815;
BA_ "FlexKomIsMotorola" SG_ 682 MC_ESP_B5 1;
BA_ "FlexKomComment" SG_ 682 MC_ESP_B5 "Message ESP_B5 packet";
BA_ "GenSigSNA" SG_ 682 SDS_Engaged_State_ESC "3h";
BA_ "GenSigCycleTime" SG_ 682 SDS_Engaged_State_ESC 10;
BA_ "FlexKomSigStartValue" SG_ 682 SDS_Engaged_State_ESC "FFFF8000000000FFh";
BA_ "FlexKomSigStartPos" SG_ 682 SDS_Engaged_State_ESC 7;
BA_ "FlexKomSigName" SG_ 682 SDS_Engaged_State_ESC "ESP_B5_Pkt";
BA_ "FlexKomSigLaenge" SG_ 682 SDS_Engaged_State_ESC 64;
BA_ "FlexKomSID" SG_ 682 SDS_Engaged_State_ESC 9815;
BA_ "FlexKomIsMotorola" SG_ 682 SDS_Engaged_State_ESC 1;
BA_ "FlexKomComment" SG_ 682 SDS_Engaged_State_ESC "Message ESP_B5 packet";
BA_ "GenSigSNA" SG_ 682 ThermalCapacityPrim "0h";
BA_ "GenSigCycleTime" SG_ 682 ThermalCapacityPrim 10;
BA_ "FlexKomSigStartValue" SG_ 682 ThermalCapacityPrim "FFFF8000000000FFh";
BA_ "FlexKomSigStartPos" SG_ 682 ThermalCapacityPrim 7;
BA_ "FlexKomSigName" SG_ 682 ThermalCapacityPrim "ESP_B5_Pkt";
BA_ "FlexKomSigLaenge" SG_ 682 ThermalCapacityPrim 64;
BA_ "FlexKomSID" SG_ 682 ThermalCapacityPrim 9815;
BA_ "FlexKomIsMotorola" SG_ 682 ThermalCapacityPrim 1;
BA_ "FlexKomComment" SG_ 682 ThermalCapacityPrim "Message ESP_B5 packet";
BA_ "GenSigSNA" SG_ 682 qTargetExternal "0h";
BA_ "GenSigCycleTime" SG_ 682 qTargetExternal 10;
BA_ "FlexKomSigStartValue" SG_ 682 qTargetExternal "FFFF8000000000FFh";
BA_ "FlexKomSigStartPos" SG_ 682 qTargetExternal 7;
BA_ "FlexKomSigName" SG_ 682 qTargetExternal "ESP_B5_Pkt";
BA_ "FlexKomSigLaenge" SG_ 682 qTargetExternal 64;
BA_ "FlexKomSID" SG_ 682 qTargetExternal 9815;
BA_ "FlexKomIsMotorola" SG_ 682 qTargetExternal 1;
BA_ "FlexKomComment" SG_ 682 qTargetExternal "Message ESP_B5 packet";
BA_ "GenSigSNA" SG_ 682 qTargetExternal_Active "0h";
BA_ "GenSigCycleTime" SG_ 682 qTargetExternal_Active 10;
BA_ "FlexKomSigStartValue" SG_ 682 qTargetExternal_Active "FFFF8000000000FFh";
BA_ "FlexKomSigStartPos" SG_ 682 qTargetExternal_Active 7;
BA_ "FlexKomSigName" SG_ 682 qTargetExternal_Active "ESP_B5_Pkt";
BA_ "FlexKomSigLaenge" SG_ 682 qTargetExternal_Active 64;
BA_ "FlexKomSID" SG_ 682 qTargetExternal_Active 9815;
BA_ "FlexKomIsMotorola" SG_ 682 qTargetExternal_Active 1;
BA_ "FlexKomComment" SG_ 682 qTargetExternal_Active "Message ESP_B5 packet";
BA_ "GenSigSNA" SG_ 402 CylOff "0h";
BA_ "GenSigCycleTime" SG_ 402 CylOff 10;
BA_ "FlexKomSigStartValue" SG_ 402 CylOff "00000000080000h";
BA_ "FlexKomSigStartPos" SG_ 402 CylOff 7;
BA_ "FlexKomSigName" SG_ 402 CylOff "Engine_Status1";
BA_ "FlexKomSigLaenge" SG_ 402 CylOff 56;
BA_ "FlexKomSID" SG_ 402 CylOff 2130708635;
BA_ "FlexKomIsMotorola" SG_ 402 CylOff 1;
BA_ "FlexKomComment" SG_ 402 CylOff ".";
BA_ "GenSigSNA" SG_ 402 ECMReq_Remedial_Stop "3h";
BA_ "GenSigCycleTime" SG_ 402 ECMReq_Remedial_Stop 10;
BA_ "FlexKomSigStartValue" SG_ 402 ECMReq_Remedial_Stop "00000100080000h";
BA_ "FlexKomSigStartPos" SG_ 402 ECMReq_Remedial_Stop 7;
BA_ "FlexKomSigName" SG_ 402 ECMReq_Remedial_Stop "Engine_Status1";
BA_ "FlexKomSigLaenge" SG_ 402 ECMReq_Remedial_Stop 56;
BA_ "FlexKomSID" SG_ 402 ECMReq_Remedial_Stop 2130708635;
BA_ "FlexKomIsMotorola" SG_ 402 ECMReq_Remedial_Stop 1;
BA_ "FlexKomComment" SG_ 402 ECMReq_Remedial_Stop ".";
BA_ "GenSigSNA" SG_ 402 ETRQ_Mode "7h";
BA_ "GenSigCycleTime" SG_ 402 ETRQ_Mode 10;
BA_ "FlexKomSigStartValue" SG_ 402 ETRQ_Mode "00000000080000h";
BA_ "FlexKomSigStartPos" SG_ 402 ETRQ_Mode 7;
BA_ "FlexKomSigName" SG_ 402 ETRQ_Mode "Engine_Status1";
BA_ "FlexKomSigLaenge" SG_ 402 ETRQ_Mode 56;
BA_ "FlexKomSID" SG_ 402 ETRQ_Mode 2130708635;
BA_ "FlexKomIsMotorola" SG_ 402 ETRQ_Mode 1;
BA_ "FlexKomComment" SG_ 402 ETRQ_Mode ".";
BA_ "GenSigSNA" SG_ 402 EVRDesVSetP "FFh";
BA_ "GenSigCycleTime" SG_ 402 EVRDesVSetP 10;
BA_ "FlexKomSigStartValue" SG_ 402 EVRDesVSetP "00000000080000h";
BA_ "FlexKomSigStartPos" SG_ 402 EVRDesVSetP 7;
BA_ "FlexKomSigName" SG_ 402 EVRDesVSetP "Engine_Status1";
BA_ "FlexKomSigLaenge" SG_ 402 EVRDesVSetP 56;
BA_ "FlexKomSID" SG_ 402 EVRDesVSetP 2130708635;
BA_ "FlexKomIsMotorola" SG_ 402 EVRDesVSetP 1;
BA_ "FlexKomComment" SG_ 402 EVRDesVSetP ".";
BA_ "GenSigSNA" SG_ 402 EngManfldAbsPrs "0h";
BA_ "GenSigCycleTime" SG_ 402 EngManfldAbsPrs 10;
BA_ "FlexKomSigStartValue" SG_ 402 EngManfldAbsPrs "00000000080000h";
BA_ "FlexKomSigStartPos" SG_ 402 EngManfldAbsPrs 7;
BA_ "FlexKomSigName" SG_ 402 EngManfldAbsPrs "Engine_Status1";
BA_ "FlexKomSigLaenge" SG_ 402 EngManfldAbsPrs 56;
BA_ "FlexKomSID" SG_ 402 EngManfldAbsPrs 2130708635;
BA_ "FlexKomIsMotorola" SG_ 402 EngManfldAbsPrs 1;
BA_ "FlexKomComment" SG_ 402 EngManfldAbsPrs ".";
BA_ "GenSigSNA" SG_ 402 EngManfldAbsPrsV "0h";
BA_ "GenSigCycleTime" SG_ 402 EngManfldAbsPrsV 10;
BA_ "FlexKomSigStartValue" SG_ 402 EngManfldAbsPrsV "00000000080000h";
BA_ "FlexKomSigStartPos" SG_ 402 EngManfldAbsPrsV 7;
BA_ "FlexKomSigName" SG_ 402 EngManfldAbsPrsV "Engine_Status1";
BA_ "FlexKomSigLaenge" SG_ 402 EngManfldAbsPrsV 56;
BA_ "FlexKomSID" SG_ 402 EngManfldAbsPrsV 2130708635;
BA_ "FlexKomIsMotorola" SG_ 402 EngManfldAbsPrsV 1;
BA_ "FlexKomComment" SG_ 402 EngManfldAbsPrsV ".";
BA_ "GenSigSNA" SG_ 402 EngOffRecom "0h";
BA_ "GenSigCycleTime" SG_ 402 EngOffRecom 10;
BA_ "FlexKomSigStartValue" SG_ 402 EngOffRecom "00000000080000h";
BA_ "FlexKomSigStartPos" SG_ 402 EngOffRecom 7;
BA_ "FlexKomSigName" SG_ 402 EngOffRecom "Engine_Status1";
BA_ "FlexKomSigLaenge" SG_ 402 EngOffRecom 56;
BA_ "FlexKomSID" SG_ 402 EngOffRecom 2130708635;
BA_ "FlexKomIsMotorola" SG_ 402 EngOffRecom 1;
BA_ "FlexKomComment" SG_ 402 EngOffRecom ".";
BA_ "GenSigSNA" SG_ 402 EngRqStTyp "Fh";
BA_ "GenSigCycleTime" SG_ 402 EngRqStTyp 10;
BA_ "FlexKomSigStartValue" SG_ 402 EngRqStTyp "00000000080000h";
BA_ "FlexKomSigStartPos" SG_ 402 EngRqStTyp 7;
BA_ "FlexKomSigName" SG_ 402 EngRqStTyp "Engine_Status1";
BA_ "FlexKomSigLaenge" SG_ 402 EngRqStTyp 56;
BA_ "FlexKomSID" SG_ 402 EngRqStTyp 2130708635;
BA_ "FlexKomIsMotorola" SG_ 402 EngRqStTyp 1;
BA_ "FlexKomComment" SG_ 402 EngRqStTyp ".";
BA_ "GenSigStartValue" SG_ 400 CRC_190h 255;
BA_ "GenSigSNA" SG_ 400 CRC_190h "FFh";
BA_ "GenSigCycleTime" SG_ 400 CRC_190h 10;
BA_ "FlexKomSigStartValue" SG_ 400 CRC_190h "00000B830B830FFFh";
BA_ "FlexKomSigStartPos" SG_ 400 CRC_190h 7;
BA_ "FlexKomSigName" SG_ 400 CRC_190h "Engine_Status2";
BA_ "FlexKomSigLaenge" SG_ 400 CRC_190h 64;
BA_ "FlexKomSID" SG_ 400 CRC_190h 2130708636;
BA_ "FlexKomIsMotorola" SG_ 400 CRC_190h 1;
BA_ "FlexKomComment" SG_ 400 CRC_190h "Engine_Status2 PKT";
BA_ "GenSigSNA" SG_ 400 ESS_ActvEBrake "0h";
BA_ "GenSigCycleTime" SG_ 400 ESS_ActvEBrake 10;
BA_ "FlexKomSigStartValue" SG_ 400 ESS_ActvEBrake "00000B830B830FFFh";
BA_ "FlexKomSigStartPos" SG_ 400 ESS_ActvEBrake 7;
BA_ "FlexKomSigName" SG_ 400 ESS_ActvEBrake "Engine_Status2";
BA_ "FlexKomSigLaenge" SG_ 400 ESS_ActvEBrake 64;
BA_ "FlexKomSID" SG_ 400 ESS_ActvEBrake 2130708636;
BA_ "FlexKomIsMotorola" SG_ 400 ESS_ActvEBrake 1;
BA_ "FlexKomComment" SG_ 400 ESS_ActvEBrake "Engine_Status2 PKT";
BA_ "GenSigStartValue" SG_ 400 ESS_Engine_State_EE 15;
BA_ "GenSigSNA" SG_ 400 ESS_Engine_State_EE "Fh";
BA_ "GenSigCycleTime" SG_ 400 ESS_Engine_State_EE 10;
BA_ "FlexKomSigStartValue" SG_ 400 ESS_Engine_State_EE "00000B830B830FFFh";
BA_ "FlexKomSigStartPos" SG_ 400 ESS_Engine_State_EE 7;
BA_ "FlexKomSigName" SG_ 400 ESS_Engine_State_EE "Engine_Status2";
BA_ "FlexKomSigLaenge" SG_ 400 ESS_Engine_State_EE 64;
BA_ "FlexKomSID" SG_ 400 ESS_Engine_State_EE 2130708636;
BA_ "FlexKomIsMotorola" SG_ 400 ESS_Engine_State_EE 1;
BA_ "FlexKomComment" SG_ 400 ESS_Engine_State_EE "Engine_Status2 PKT";
BA_ "GenSigSNA" SG_ 400 ESS_RqShftPark "0h";
BA_ "GenSigCycleTime" SG_ 400 ESS_RqShftPark 10;
BA_ "FlexKomSigStartValue" SG_ 400 ESS_RqShftPark "00000B830B830FFFh";
BA_ "FlexKomSigStartPos" SG_ 400 ESS_RqShftPark 7;
BA_ "FlexKomSigName" SG_ 400 ESS_RqShftPark "Engine_Status2";
BA_ "FlexKomSigLaenge" SG_ 400 ESS_RqShftPark 64;
BA_ "FlexKomSID" SG_ 400 ESS_RqShftPark 2130708636;
BA_ "FlexKomIsMotorola" SG_ 400 ESS_RqShftPark 1;
BA_ "FlexKomComment" SG_ 400 ESS_RqShftPark "Engine_Status2 PKT";
BA_ "GenSigSNA" SG_ 400 EngActuatorsStat "0h";
BA_ "GenSigCycleTime" SG_ 400 EngActuatorsStat 10;
BA_ "FlexKomSigStartValue" SG_ 400 EngActuatorsStat "00000B830B830FFFh";
BA_ "FlexKomSigStartPos" SG_ 400 EngActuatorsStat 7;
BA_ "FlexKomSigName" SG_ 400 EngActuatorsStat "Engine_Status2";
BA_ "FlexKomSigLaenge" SG_ 400 EngActuatorsStat 64;
BA_ "FlexKomSID" SG_ 400 EngActuatorsStat 2130708636;
BA_ "FlexKomIsMotorola" SG_ 400 EngActuatorsStat 1;
BA_ "FlexKomComment" SG_ 400 EngActuatorsStat "Engine_Status2 PKT";
BA_ "GenSigSNA" SG_ 400 EngCmbstnCmnd "0h";
BA_ "GenSigCycleTime" SG_ 400 EngCmbstnCmnd 10;
BA_ "FlexKomSigStartValue" SG_ 400 EngCmbstnCmnd "00000B830B830FFFh";
BA_ "FlexKomSigStartPos" SG_ 400 EngCmbstnCmnd 7;
BA_ "FlexKomSigName" SG_ 400 EngCmbstnCmnd "Engine_Status2";
BA_ "FlexKomSigLaenge" SG_ 400 EngCmbstnCmnd 64;
BA_ "FlexKomSID" SG_ 400 EngCmbstnCmnd 2130708636;
BA_ "FlexKomIsMotorola" SG_ 400 EngCmbstnCmnd 1;
BA_ "FlexKomComment" SG_ 400 EngCmbstnCmnd "Engine_Status2 PKT";
BA_ "GenSigSNA" SG_ 400 EngCylDeactEnCondMet "0h";
BA_ "GenSigCycleTime" SG_ 400 EngCylDeactEnCondMet 10;
BA_ "FlexKomSigStartValue" SG_ 400 EngCylDeactEnCondMet "00000B830B830FFFh";
BA_ "FlexKomSigStartPos" SG_ 400 EngCylDeactEnCondMet 7;
BA_ "FlexKomSigName" SG_ 400 EngCylDeactEnCondMet "Engine_Status2";
BA_ "FlexKomSigLaenge" SG_ 400 EngCylDeactEnCondMet 64;
BA_ "FlexKomSID" SG_ 400 EngCylDeactEnCondMet 2130708636;
BA_ "FlexKomIsMotorola" SG_ 400 EngCylDeactEnCondMet 1;
BA_ "FlexKomComment" SG_ 400 EngCylDeactEnCondMet "Engine_Status2 PKT";
BA_ "GenSigSNA" SG_ 400 EngCylDeactMd "0h";
BA_ "GenSigCycleTime" SG_ 400 EngCylDeactMd 10;
BA_ "FlexKomSigStartValue" SG_ 400 EngCylDeactMd "00000B830B830FFFh";
BA_ "FlexKomSigStartPos" SG_ 400 EngCylDeactMd 7;
BA_ "FlexKomSigName" SG_ 400 EngCylDeactMd "Engine_Status2";
BA_ "FlexKomSigLaenge" SG_ 400 EngCylDeactMd 64;
BA_ "FlexKomSID" SG_ 400 EngCylDeactMd 2130708636;
BA_ "FlexKomIsMotorola" SG_ 400 EngCylDeactMd 1;
BA_ "FlexKomComment" SG_ 400 EngCylDeactMd "Engine_Status2 PKT";
BA_ "GenSigSNA" SG_ 400 EngTrqReserveReq "FFh";
BA_ "GenSigCycleTime" SG_ 400 EngTrqReserveReq 10;
BA_ "FlexKomSigStartValue" SG_ 400 EngTrqReserveReq "00000B830B830FFFh";
BA_ "FlexKomSigStartPos" SG_ 400 EngTrqReserveReq 7;
BA_ "FlexKomSigName" SG_ 400 EngTrqReserveReq "Engine_Status2";
BA_ "FlexKomSigLaenge" SG_ 400 EngTrqReserveReq 64;
BA_ "FlexKomSID" SG_ 400 EngTrqReserveReq 2130708636;
BA_ "FlexKomIsMotorola" SG_ 400 EngTrqReserveReq 1;
BA_ "FlexKomComment" SG_ 400 EngTrqReserveReq "Engine_Status2 PKT";
BA_ "GenSigSNA" SG_ 400 Feedback_HCP "0h";
BA_ "GenSigCycleTime" SG_ 400 Feedback_HCP 10;
BA_ "FlexKomSigStartValue" SG_ 400 Feedback_HCP "00000B830B830FFFh";
BA_ "FlexKomSigStartPos" SG_ 400 Feedback_HCP 7;
BA_ "FlexKomSigName" SG_ 400 Feedback_HCP "Engine_Status2";
BA_ "FlexKomSigLaenge" SG_ 400 Feedback_HCP 64;
BA_ "FlexKomSID" SG_ 400 Feedback_HCP 2130708636;
BA_ "FlexKomIsMotorola" SG_ 400 Feedback_HCP 1;
BA_ "FlexKomComment" SG_ 400 Feedback_HCP "Engine_Status2 PKT";
BA_ "GenSigSNA" SG_ 400 MC_190h "0h";
BA_ "GenSigCycleTime" SG_ 400 MC_190h 10;
BA_ "FlexKomSigStartValue" SG_ 400 MC_190h "00000B830B830FFFh";
BA_ "FlexKomSigStartPos" SG_ 400 MC_190h 7;
BA_ "FlexKomSigName" SG_ 400 MC_190h "Engine_Status2";
BA_ "FlexKomSigLaenge" SG_ 400 MC_190h 64;
BA_ "FlexKomSID" SG_ 400 MC_190h 2130708636;
BA_ "FlexKomIsMotorola" SG_ 400 MC_190h 1;
BA_ "FlexKomComment" SG_ 400 MC_190h "Engine_Status2 PKT";
BA_ "GenSigSNA" SG_ 400 PT_BrkPedDscrtInpStat "0h";
BA_ "GenSigCycleTime" SG_ 400 PT_BrkPedDscrtInpStat 10;
BA_ "FlexKomSigStartValue" SG_ 400 PT_BrkPedDscrtInpStat "00000B830B830FFFh";
BA_ "FlexKomSigStartPos" SG_ 400 PT_BrkPedDscrtInpStat 7;
BA_ "FlexKomSigName" SG_ 400 PT_BrkPedDscrtInpStat "Engine_Status2";
BA_ "FlexKomSigLaenge" SG_ 400 PT_BrkPedDscrtInpStat 64;
BA_ "FlexKomSID" SG_ 400 PT_BrkPedDscrtInpStat 2130708636;
BA_ "FlexKomIsMotorola" SG_ 400 PT_BrkPedDscrtInpStat 1;
BA_ "FlexKomComment" SG_ 400 PT_BrkPedDscrtInpStat "Engine_Status2 PKT";
BA_ "GenSigSNA" SG_ 400 PT_BrkPedDscrtInpStatV "0h";
BA_ "GenSigCycleTime" SG_ 400 PT_BrkPedDscrtInpStatV 10;
BA_ "FlexKomSigStartValue" SG_ 400 PT_BrkPedDscrtInpStatV "00000B830B830FFFh";
BA_ "FlexKomSigStartPos" SG_ 400 PT_BrkPedDscrtInpStatV 7;
BA_ "FlexKomSigName" SG_ 400 PT_BrkPedDscrtInpStatV "Engine_Status2";
BA_ "FlexKomSigLaenge" SG_ 400 PT_BrkPedDscrtInpStatV 64;
BA_ "FlexKomSID" SG_ 400 PT_BrkPedDscrtInpStatV 2130708636;
BA_ "FlexKomIsMotorola" SG_ 400 PT_BrkPedDscrtInpStatV 1;
BA_ "FlexKomComment" SG_ 400 PT_BrkPedDscrtInpStatV "Engine_Status2 PKT";
BA_ "GenSigStartValue" SG_ 400 T_max_raw 2947;
BA_ "GenSigSNA" SG_ 400 T_max_raw "3FFFh";
BA_ "GenSigCycleTime" SG_ 400 T_max_raw 10;
BA_ "FlexKomSigStartValue" SG_ 400 T_max_raw "00000B830B830FFFh";
BA_ "FlexKomSigStartPos" SG_ 400 T_max_raw 7;
BA_ "FlexKomSigName" SG_ 400 T_max_raw "Engine_Status2";
BA_ "FlexKomSigLaenge" SG_ 400 T_max_raw 64;
BA_ "FlexKomSID" SG_ 400 T_max_raw 2130708636;
BA_ "FlexKomIsMotorola" SG_ 400 T_max_raw 1;
BA_ "FlexKomComment" SG_ 400 T_max_raw "Engine_Status2 PKT";
BA_ "GenSigStartValue" SG_ 400 T_min_raw 2947;
BA_ "GenSigSNA" SG_ 400 T_min_raw "3FFFh";
BA_ "GenSigCycleTime" SG_ 400 T_min_raw 10;
BA_ "FlexKomSigStartValue" SG_ 400 T_min_raw "00000B830B830FFFh";
BA_ "FlexKomSigStartPos" SG_ 400 T_min_raw 7;
BA_ "FlexKomSigName" SG_ 400 T_min_raw "Engine_Status2";
BA_ "FlexKomSigLaenge" SG_ 400 T_min_raw 64;
BA_ "FlexKomSID" SG_ 400 T_min_raw 2130708636;
BA_ "FlexKomIsMotorola" SG_ 400 T_min_raw 1;
BA_ "FlexKomComment" SG_ 400 T_min_raw "Engine_Status2 PKT";
BA_ "GenSigSNA" SG_ 771 AGSposn "7Fh";
BA_ "GenSigCycleTime" SG_ 771 AGSposn 100;
BA_ "FlexKomSigStartValue" SG_ 771 AGSposn "0000002000000000h";
BA_ "FlexKomSigStartPos" SG_ 771 AGSposn 7;
BA_ "FlexKomSigName" SG_ 771 AGSposn "Engine_Status3";
BA_ "FlexKomSigLaenge" SG_ 771 AGSposn 64;
BA_ "FlexKomSID" SG_ 771 AGSposn 2130708634;
BA_ "FlexKomIsMotorola" SG_ 771 AGSposn 1;
BA_ "FlexKomComment" SG_ 771 AGSposn ".";
BA_ "GenSigSNA" SG_ 771 EngOffTmPT "0h";
BA_ "GenSigCycleTime" SG_ 771 EngOffTmPT 100;
BA_ "FlexKomSigStartValue" SG_ 771 EngOffTmPT "0000002000000000h";
BA_ "FlexKomSigStartPos" SG_ 771 EngOffTmPT 7;
BA_ "FlexKomSigName" SG_ 771 EngOffTmPT "Engine_Status3";
BA_ "FlexKomSigLaenge" SG_ 771 EngOffTmPT 64;
BA_ "FlexKomSID" SG_ 771 EngOffTmPT 2130708634;
BA_ "FlexKomIsMotorola" SG_ 771 EngOffTmPT 1;
BA_ "FlexKomComment" SG_ 771 EngOffTmPT ".";
BA_ "GenSigStartValue" SG_ 771 EngOffTmPTV 1;
BA_ "GenSigSNA" SG_ 771 EngOffTmPTV "1h";
BA_ "GenSigCycleTime" SG_ 771 EngOffTmPTV 100;
BA_ "FlexKomSigStartValue" SG_ 771 EngOffTmPTV "0000002000000000h";
BA_ "FlexKomSigStartPos" SG_ 771 EngOffTmPTV 7;
BA_ "FlexKomSigName" SG_ 771 EngOffTmPTV "Engine_Status3";
BA_ "FlexKomSigLaenge" SG_ 771 EngOffTmPTV 64;
BA_ "FlexKomSID" SG_ 771 EngOffTmPTV 2130708634;
BA_ "FlexKomIsMotorola" SG_ 771 EngOffTmPTV 1;
BA_ "FlexKomComment" SG_ 771 EngOffTmPTV ".";
BA_ "GenSigSNA" SG_ 771 EstCatCnvTmp "FFh";
BA_ "GenSigCycleTime" SG_ 771 EstCatCnvTmp 100;
BA_ "FlexKomSigStartValue" SG_ 771 EstCatCnvTmp "0000002000000000h";
BA_ "FlexKomSigStartPos" SG_ 771 EstCatCnvTmp 7;
BA_ "FlexKomSigName" SG_ 771 EstCatCnvTmp "Engine_Status3";
BA_ "FlexKomSigLaenge" SG_ 771 EstCatCnvTmp 64;
BA_ "FlexKomSID" SG_ 771 EstCatCnvTmp 2130708634;
BA_ "FlexKomIsMotorola" SG_ 771 EstCatCnvTmp 1;
BA_ "FlexKomComment" SG_ 771 EstCatCnvTmp ".";
BA_ "GenSigSNA" SG_ 771 IgnCntrFuelEngTrue "0h";
BA_ "GenSigCycleTime" SG_ 771 IgnCntrFuelEngTrue 100;
BA_ "FlexKomSigStartValue" SG_ 771 IgnCntrFuelEngTrue "0000002000000000h";
BA_ "FlexKomSigStartPos" SG_ 771 IgnCntrFuelEngTrue 7;
BA_ "FlexKomSigName" SG_ 771 IgnCntrFuelEngTrue "Engine_Status3";
BA_ "FlexKomSigLaenge" SG_ 771 IgnCntrFuelEngTrue 64;
BA_ "FlexKomSID" SG_ 771 IgnCntrFuelEngTrue 2130708634;
BA_ "FlexKomIsMotorola" SG_ 771 IgnCntrFuelEngTrue 1;
BA_ "FlexKomComment" SG_ 771 IgnCntrFuelEngTrue ".";
BA_ "GenSigSNA" SG_ 771 IgnCntrTrue "0h";
BA_ "GenSigCycleTime" SG_ 771 IgnCntrTrue 100;
BA_ "FlexKomSigStartValue" SG_ 771 IgnCntrTrue "0000002000000000h";
BA_ "FlexKomSigStartPos" SG_ 771 IgnCntrTrue 7;
BA_ "FlexKomSigName" SG_ 771 IgnCntrTrue "Engine_Status3";
BA_ "FlexKomSigLaenge" SG_ 771 IgnCntrTrue 64;
BA_ "FlexKomSID" SG_ 771 IgnCntrTrue 2130708634;
BA_ "FlexKomIsMotorola" SG_ 771 IgnCntrTrue 1;
BA_ "FlexKomComment" SG_ 771 IgnCntrTrue ".";
BA_ "GenSigSNA" SG_ 771 InpICCFuelEng_Fail "0h";
BA_ "GenSigCycleTime" SG_ 771 InpICCFuelEng_Fail 100;
BA_ "FlexKomSigStartValue" SG_ 771 InpICCFuelEng_Fail "0000002000000000h";
BA_ "FlexKomSigStartPos" SG_ 771 InpICCFuelEng_Fail 7;
BA_ "FlexKomSigName" SG_ 771 InpICCFuelEng_Fail "Engine_Status3";
BA_ "FlexKomSigLaenge" SG_ 771 InpICCFuelEng_Fail 64;
BA_ "FlexKomSID" SG_ 771 InpICCFuelEng_Fail 2130708634;
BA_ "FlexKomIsMotorola" SG_ 771 InpICCFuelEng_Fail 1;
BA_ "FlexKomComment" SG_ 771 InpICCFuelEng_Fail ".";
BA_ "GenSigSNA" SG_ 771 InplCC_Fail "0h";
BA_ "GenSigCycleTime" SG_ 771 InplCC_Fail 100;
BA_ "FlexKomSigStartValue" SG_ 771 InplCC_Fail "0000002000000000h";
BA_ "FlexKomSigStartPos" SG_ 771 InplCC_Fail 7;
BA_ "FlexKomSigName" SG_ 771 InplCC_Fail "Engine_Status3";
BA_ "FlexKomSigLaenge" SG_ 771 InplCC_Fail 64;
BA_ "FlexKomSID" SG_ 771 InplCC_Fail 2130708634;
BA_ "FlexKomIsMotorola" SG_ 771 InplCC_Fail 1;
BA_ "FlexKomComment" SG_ 771 InplCC_Fail ".";
BA_ "GenSigSNA" SG_ 771 RadFanReq "7Fh";
BA_ "GenSigCycleTime" SG_ 771 RadFanReq 100;
BA_ "FlexKomSigStartValue" SG_ 771 RadFanReq "0000002000000000h";
BA_ "FlexKomSigStartPos" SG_ 771 RadFanReq 7;
BA_ "FlexKomSigName" SG_ 771 RadFanReq "Engine_Status3";
BA_ "FlexKomSigLaenge" SG_ 771 RadFanReq 64;
BA_ "FlexKomSID" SG_ 771 RadFanReq 2130708634;
BA_ "FlexKomIsMotorola" SG_ 771 RadFanReq 1;
BA_ "FlexKomComment" SG_ 771 RadFanReq ".";
BA_ "GenSigSNA" SG_ 771 ServiceHybSys "0h";
BA_ "GenSigCycleTime" SG_ 771 ServiceHybSys 100;
BA_ "FlexKomSigStartValue" SG_ 771 ServiceHybSys "0000002000000000h";
BA_ "FlexKomSigStartPos" SG_ 771 ServiceHybSys 7;
BA_ "FlexKomSigName" SG_ 771 ServiceHybSys "Engine_Status3";
BA_ "FlexKomSigLaenge" SG_ 771 ServiceHybSys 64;
BA_ "FlexKomSID" SG_ 771 ServiceHybSys 2130708634;
BA_ "FlexKomIsMotorola" SG_ 771 ServiceHybSys 1;
BA_ "FlexKomComment" SG_ 771 ServiceHybSys ".";
BA_ "GenSigSNA" SG_ 396 ECM_HoodAjar "3h";
BA_ "GenSigCycleTime" SG_ 396 ECM_HoodAjar 100;
BA_ "FlexKomSigStartValue" SG_ 396 ECM_HoodAjar "0000000000000000h";
BA_ "FlexKomSigStartPos" SG_ 396 ECM_HoodAjar 7;
BA_ "FlexKomSigName" SG_ 396 ECM_HoodAjar "Engine_Status4";
BA_ "FlexKomSigLaenge" SG_ 396 ECM_HoodAjar 64;
BA_ "FlexKomSID" SG_ 396 ECM_HoodAjar 2130708637;
BA_ "FlexKomIsMotorola" SG_ 396 ECM_HoodAjar 1;
BA_ "FlexKomComment" SG_ 396 ECM_HoodAjar ".";
BA_ "GenSigSNA" SG_ 396 EngHalfCylSpdMaxLim "1FFFh";
BA_ "GenSigCycleTime" SG_ 396 EngHalfCylSpdMaxLim 100;
BA_ "FlexKomSigStartValue" SG_ 396 EngHalfCylSpdMaxLim "0000000000000000h";
BA_ "FlexKomSigStartPos" SG_ 396 EngHalfCylSpdMaxLim 7;
BA_ "FlexKomSigName" SG_ 396 EngHalfCylSpdMaxLim "Engine_Status4";
BA_ "FlexKomSigLaenge" SG_ 396 EngHalfCylSpdMaxLim 64;
BA_ "FlexKomSID" SG_ 396 EngHalfCylSpdMaxLim 2130708637;
BA_ "FlexKomIsMotorola" SG_ 396 EngHalfCylSpdMaxLim 1;
BA_ "FlexKomComment" SG_ 396 EngHalfCylSpdMaxLim ".";
BA_ "GenSigSNA" SG_ 396 EngHalfCylSpdMinLim "1FFFh";
BA_ "GenSigCycleTime" SG_ 396 EngHalfCylSpdMinLim 100;
BA_ "FlexKomSigStartValue" SG_ 396 EngHalfCylSpdMinLim "0000000000000000h";
BA_ "FlexKomSigStartPos" SG_ 396 EngHalfCylSpdMinLim 7;
BA_ "FlexKomSigName" SG_ 396 EngHalfCylSpdMinLim "Engine_Status4";
BA_ "FlexKomSigLaenge" SG_ 396 EngHalfCylSpdMinLim 64;
BA_ "FlexKomSID" SG_ 396 EngHalfCylSpdMinLim 2130708637;
BA_ "FlexKomIsMotorola" SG_ 396 EngHalfCylSpdMinLim 1;
BA_ "FlexKomComment" SG_ 396 EngHalfCylSpdMinLim ".";
BA_ "GenSigSNA" SG_ 396 EngOutofFuel "0h";
BA_ "GenSigCycleTime" SG_ 396 EngOutofFuel 100;
BA_ "FlexKomSigStartValue" SG_ 396 EngOutofFuel "0000000000000000h";
BA_ "FlexKomSigStartPos" SG_ 396 EngOutofFuel 7;
BA_ "FlexKomSigName" SG_ 396 EngOutofFuel "Engine_Status4";
BA_ "FlexKomSigLaenge" SG_ 396 EngOutofFuel 64;
BA_ "FlexKomSID" SG_ 396 EngOutofFuel 2130708637;
BA_ "FlexKomIsMotorola" SG_ 396 EngOutofFuel 1;
BA_ "FlexKomComment" SG_ 396 EngOutofFuel ".";
BA_ "GenSigSNA" SG_ 396 MaxEngSpdCap "0h";
BA_ "GenSigCycleTime" SG_ 396 MaxEngSpdCap 100;
BA_ "FlexKomSigStartValue" SG_ 396 MaxEngSpdCap "0000000000000000h";
BA_ "FlexKomSigStartPos" SG_ 396 MaxEngSpdCap 7;
BA_ "FlexKomSigName" SG_ 396 MaxEngSpdCap "Engine_Status4";
BA_ "FlexKomSigLaenge" SG_ 396 MaxEngSpdCap 64;
BA_ "FlexKomSID" SG_ 396 MaxEngSpdCap 2130708637;
BA_ "FlexKomIsMotorola" SG_ 396 MaxEngSpdCap 1;
BA_ "FlexKomComment" SG_ 396 MaxEngSpdCap ".";
BA_ "GenSigSNA" SG_ 396 MinEngSpdCap "0h";
BA_ "GenSigCycleTime" SG_ 396 MinEngSpdCap 100;
BA_ "FlexKomSigStartValue" SG_ 396 MinEngSpdCap "0000000000000000h";
BA_ "FlexKomSigStartPos" SG_ 396 MinEngSpdCap 7;
BA_ "FlexKomSigName" SG_ 396 MinEngSpdCap "Engine_Status4";
BA_ "FlexKomSigLaenge" SG_ 396 MinEngSpdCap 64;
BA_ "FlexKomSID" SG_ 396 MinEngSpdCap 2130708637;
BA_ "FlexKomIsMotorola" SG_ 396 MinEngSpdCap 1;
BA_ "FlexKomComment" SG_ 396 MinEngSpdCap ".";
BA_ "GenSigSNA" SG_ 770 BarPrsAbs "0h";
BA_ "GenSigCycleTime" SG_ 770 BarPrsAbs 100;
BA_ "FlexKomSigStartValue" SG_ 770 BarPrsAbs "0000000000000000h";
BA_ "FlexKomSigStartPos" SG_ 770 BarPrsAbs 7;
BA_ "FlexKomSigName" SG_ 770 BarPrsAbs "Engine_Status5";
BA_ "FlexKomSigLaenge" SG_ 770 BarPrsAbs 64;
BA_ "FlexKomSID" SG_ 770 BarPrsAbs 2130708633;
BA_ "FlexKomIsMotorola" SG_ 770 BarPrsAbs 1;
BA_ "FlexKomComment" SG_ 770 BarPrsAbs ".";
BA_ "GenSigSNA" SG_ 770 BarPrsAbsV "0h";
BA_ "GenSigCycleTime" SG_ 770 BarPrsAbsV 100;
BA_ "FlexKomSigStartValue" SG_ 770 BarPrsAbsV "0000000000000000h";
BA_ "FlexKomSigStartPos" SG_ 770 BarPrsAbsV 7;
BA_ "FlexKomSigName" SG_ 770 BarPrsAbsV "Engine_Status5";
BA_ "FlexKomSigLaenge" SG_ 770 BarPrsAbsV 64;
BA_ "FlexKomSID" SG_ 770 BarPrsAbsV 2130708633;
BA_ "FlexKomIsMotorola" SG_ 770 BarPrsAbsV 1;
BA_ "FlexKomComment" SG_ 770 BarPrsAbsV ".";
BA_ "GenSigSNA" SG_ 770 EngCltTmp "FFh";
BA_ "GenSigCycleTime" SG_ 770 EngCltTmp 100;
BA_ "FlexKomSigStartValue" SG_ 770 EngCltTmp "0000000000000000h";
BA_ "FlexKomSigStartPos" SG_ 770 EngCltTmp 7;
BA_ "FlexKomSigName" SG_ 770 EngCltTmp "Engine_Status5";
BA_ "FlexKomSigLaenge" SG_ 770 EngCltTmp 64;
BA_ "FlexKomSID" SG_ 770 EngCltTmp 2130708633;
BA_ "FlexKomIsMotorola" SG_ 770 EngCltTmp 1;
BA_ "FlexKomComment" SG_ 770 EngCltTmp ".";
BA_ "GenSigSNA" SG_ 770 EngCltTmpV "0h";
BA_ "GenSigCycleTime" SG_ 770 EngCltTmpV 100;
BA_ "FlexKomSigStartValue" SG_ 770 EngCltTmpV "0000000000000000h";
BA_ "FlexKomSigStartPos" SG_ 770 EngCltTmpV 7;
BA_ "FlexKomSigName" SG_ 770 EngCltTmpV "Engine_Status5";
BA_ "FlexKomSigLaenge" SG_ 770 EngCltTmpV 64;
BA_ "FlexKomSID" SG_ 770 EngCltTmpV 2130708633;
BA_ "FlexKomIsMotorola" SG_ 770 EngCltTmpV 1;
BA_ "FlexKomComment" SG_ 770 EngCltTmpV ".";
BA_ "GenSigSNA" SG_ 770 EngIntAirTmp "FFh";
BA_ "GenSigCycleTime" SG_ 770 EngIntAirTmp 100;
BA_ "FlexKomSigStartValue" SG_ 770 EngIntAirTmp "0000000000000000h";
BA_ "FlexKomSigStartPos" SG_ 770 EngIntAirTmp 7;
BA_ "FlexKomSigName" SG_ 770 EngIntAirTmp "Engine_Status5";
BA_ "FlexKomSigLaenge" SG_ 770 EngIntAirTmp 64;
BA_ "FlexKomSID" SG_ 770 EngIntAirTmp 2130708633;
BA_ "FlexKomIsMotorola" SG_ 770 EngIntAirTmp 1;
BA_ "FlexKomComment" SG_ 770 EngIntAirTmp ".";
BA_ "GenSigSNA" SG_ 770 EngIntAirTmpV "0h";
BA_ "GenSigCycleTime" SG_ 770 EngIntAirTmpV 100;
BA_ "FlexKomSigStartValue" SG_ 770 EngIntAirTmpV "0000000000000000h";
BA_ "FlexKomSigStartPos" SG_ 770 EngIntAirTmpV 7;
BA_ "FlexKomSigName" SG_ 770 EngIntAirTmpV "Engine_Status5";
BA_ "FlexKomSigLaenge" SG_ 770 EngIntAirTmpV 64;
BA_ "FlexKomSID" SG_ 770 EngIntAirTmpV 2130708633;
BA_ "FlexKomIsMotorola" SG_ 770 EngIntAirTmpV 1;
BA_ "FlexKomComment" SG_ 770 EngIntAirTmpV ".";
BA_ "GenSigSNA" SG_ 770 EngRunAtv "0h";
BA_ "GenSigCycleTime" SG_ 770 EngRunAtv 100;
BA_ "FlexKomSigStartValue" SG_ 770 EngRunAtv "0000000000000000h";
BA_ "FlexKomSigStartPos" SG_ 770 EngRunAtv 7;
BA_ "FlexKomSigName" SG_ 770 EngRunAtv "Engine_Status5";
BA_ "FlexKomSigLaenge" SG_ 770 EngRunAtv 64;
BA_ "FlexKomSID" SG_ 770 EngRunAtv 2130708633;
BA_ "FlexKomIsMotorola" SG_ 770 EngRunAtv 1;
BA_ "FlexKomComment" SG_ 770 EngRunAtv ".";
BA_ "GenSigSNA" SG_ 770 EngSpd "0h";
BA_ "GenSigCycleTime" SG_ 770 EngSpd 100;
BA_ "FlexKomSigStartValue" SG_ 770 EngSpd "0000000000000000h";
BA_ "FlexKomSigStartPos" SG_ 770 EngSpd 7;
BA_ "FlexKomSigName" SG_ 770 EngSpd "Engine_Status5";
BA_ "FlexKomSigLaenge" SG_ 770 EngSpd 64;
BA_ "FlexKomSID" SG_ 770 EngSpd 2130708633;
BA_ "FlexKomIsMotorola" SG_ 770 EngSpd 1;
BA_ "FlexKomComment" SG_ 770 EngSpd ".";
BA_ "GenSigSNA" SG_ 770 EngSpdStat "3h";
BA_ "GenSigCycleTime" SG_ 770 EngSpdStat 100;
BA_ "FlexKomSigStartValue" SG_ 770 EngSpdStat "0000000000000000h";
BA_ "FlexKomSigStartPos" SG_ 770 EngSpdStat 7;
BA_ "FlexKomSigName" SG_ 770 EngSpdStat "Engine_Status5";
BA_ "FlexKomSigLaenge" SG_ 770 EngSpdStat 64;
BA_ "FlexKomSID" SG_ 770 EngSpdStat 2130708633;
BA_ "FlexKomIsMotorola" SG_ 770 EngSpdStat 1;
BA_ "FlexKomComment" SG_ 770 EngSpdStat ".";
BA_ "GenSigSNA" SG_ 770 EngWrmUpAch "0h";
BA_ "GenSigCycleTime" SG_ 770 EngWrmUpAch 100;
BA_ "FlexKomSigStartValue" SG_ 770 EngWrmUpAch "0000000000000000h";
BA_ "FlexKomSigStartPos" SG_ 770 EngWrmUpAch 7;
BA_ "FlexKomSigName" SG_ 770 EngWrmUpAch "Engine_Status5";
BA_ "FlexKomSigLaenge" SG_ 770 EngWrmUpAch 64;
BA_ "FlexKomSID" SG_ 770 EngWrmUpAch 2130708633;
BA_ "FlexKomIsMotorola" SG_ 770 EngWrmUpAch 1;
BA_ "FlexKomComment" SG_ 770 EngWrmUpAch ".";
BA_ "GenSigSNA" SG_ 770 LgsDiagCldStrtCndFltPr "0h";
BA_ "GenSigCycleTime" SG_ 770 LgsDiagCldStrtCndFltPr 100;
BA_ "FlexKomSigStartValue" SG_ 770 LgsDiagCldStrtCndFltPr "0000000000000000h";
BA_ "FlexKomSigStartPos" SG_ 770 LgsDiagCldStrtCndFltPr 7;
BA_ "FlexKomSigName" SG_ 770 LgsDiagCldStrtCndFltPr "Engine_Status5";
BA_ "FlexKomSigLaenge" SG_ 770 LgsDiagCldStrtCndFltPr 64;
BA_ "FlexKomSID" SG_ 770 LgsDiagCldStrtCndFltPr 2130708633;
BA_ "FlexKomIsMotorola" SG_ 770 LgsDiagCldStrtCndFltPr 1;
BA_ "FlexKomComment" SG_ 770 LgsDiagCldStrtCndFltPr ".";
BA_ "GenSigSNA" SG_ 770 LgsDiagCldStrtCndMet "0h";
BA_ "GenSigCycleTime" SG_ 770 LgsDiagCldStrtCndMet 100;
BA_ "FlexKomSigStartValue" SG_ 770 LgsDiagCldStrtCndMet "0000000000000000h";
BA_ "FlexKomSigStartPos" SG_ 770 LgsDiagCldStrtCndMet 7;
BA_ "FlexKomSigName" SG_ 770 LgsDiagCldStrtCndMet "Engine_Status5";
BA_ "FlexKomSigLaenge" SG_ 770 LgsDiagCldStrtCndMet 64;
BA_ "FlexKomSID" SG_ 770 LgsDiagCldStrtCndMet 2130708633;
BA_ "FlexKomIsMotorola" SG_ 770 LgsDiagCldStrtCndMet 1;
BA_ "FlexKomComment" SG_ 770 LgsDiagCldStrtCndMet ".";
BA_ "GenSigSNA" SG_ 770 LgsDiagStndCondFltPrs "0h";
BA_ "GenSigCycleTime" SG_ 770 LgsDiagStndCondFltPrs 100;
BA_ "FlexKomSigStartValue" SG_ 770 LgsDiagStndCondFltPrs "0000000000000000h";
BA_ "FlexKomSigStartPos" SG_ 770 LgsDiagStndCondFltPrs 7;
BA_ "FlexKomSigName" SG_ 770 LgsDiagStndCondFltPrs "Engine_Status5";
BA_ "FlexKomSigLaenge" SG_ 770 LgsDiagStndCondFltPrs 64;
BA_ "FlexKomSID" SG_ 770 LgsDiagStndCondFltPrs 2130708633;
BA_ "FlexKomIsMotorola" SG_ 770 LgsDiagStndCondFltPrs 1;
BA_ "FlexKomComment" SG_ 770 LgsDiagStndCondFltPrs ".";
BA_ "GenSigSNA" SG_ 770 LgsDiagStndCondMet "0h";
BA_ "GenSigCycleTime" SG_ 770 LgsDiagStndCondMet 100;
BA_ "FlexKomSigStartValue" SG_ 770 LgsDiagStndCondMet "0000000000000000h";
BA_ "FlexKomSigStartPos" SG_ 770 LgsDiagStndCondMet 7;
BA_ "FlexKomSigName" SG_ 770 LgsDiagStndCondMet "Engine_Status5";
BA_ "FlexKomSigLaenge" SG_ 770 LgsDiagStndCondMet 64;
BA_ "FlexKomSID" SG_ 770 LgsDiagStndCondMet 2130708633;
BA_ "FlexKomIsMotorola" SG_ 770 LgsDiagStndCondMet 1;
BA_ "FlexKomComment" SG_ 770 LgsDiagStndCondMet ".";
BA_ "GenSigSNA" SG_ 770 OAT_PT_Est "0h";
BA_ "GenSigCycleTime" SG_ 770 OAT_PT_Est 100;
BA_ "FlexKomSigStartValue" SG_ 770 OAT_PT_Est "0000000000000000h";
BA_ "FlexKomSigStartPos" SG_ 770 OAT_PT_Est 7;
BA_ "FlexKomSigName" SG_ 770 OAT_PT_Est "Engine_Status5";
BA_ "FlexKomSigLaenge" SG_ 770 OAT_PT_Est 64;
BA_ "FlexKomSID" SG_ 770 OAT_PT_Est 2130708633;
BA_ "FlexKomIsMotorola" SG_ 770 OAT_PT_Est 1;
BA_ "FlexKomComment" SG_ 770 OAT_PT_Est ".";
BA_ "GenSigSNA" SG_ 770 OAT_PT_EstV "0h";
BA_ "GenSigCycleTime" SG_ 770 OAT_PT_EstV 100;
BA_ "FlexKomSigStartValue" SG_ 770 OAT_PT_EstV "0000000000000000h";
BA_ "FlexKomSigStartPos" SG_ 770 OAT_PT_EstV 7;
BA_ "FlexKomSigName" SG_ 770 OAT_PT_EstV "Engine_Status5";
BA_ "FlexKomSigLaenge" SG_ 770 OAT_PT_EstV 64;
BA_ "FlexKomSID" SG_ 770 OAT_PT_EstV 2130708633;
BA_ "FlexKomIsMotorola" SG_ 770 OAT_PT_EstV 1;
BA_ "FlexKomComment" SG_ 770 OAT_PT_EstV ".";
BA_ "GenSigSNA" SG_ 849 CatHtgStateActive "0h";
BA_ "GenSigCycleTime" SG_ 849 CatHtgStateActive 200;
BA_ "FlexKomSigStartValue" SG_ 849 CatHtgStateActive "03AA03AA000003AAh";
BA_ "FlexKomSigStartPos" SG_ 849 CatHtgStateActive 7;
BA_ "FlexKomSigName" SG_ 849 CatHtgStateActive "Engine_Torque_Capability";
BA_ "FlexKomSigLaenge" SG_ 849 CatHtgStateActive 64;
BA_ "FlexKomSID" SG_ 849 CatHtgStateActive 2130708639;
BA_ "FlexKomIsMotorola" SG_ 849 CatHtgStateActive 1;
BA_ "FlexKomComment" SG_ 849 CatHtgStateActive ".";
BA_ "GenSigSNA" SG_ 849 EngTorqACCCapability "FFh";
BA_ "GenSigCycleTime" SG_ 849 EngTorqACCCapability 200;
BA_ "FlexKomSigStartValue" SG_ 849 EngTorqACCCapability "03AA03AA000003AAh";
BA_ "FlexKomSigStartPos" SG_ 849 EngTorqACCCapability 7;
BA_ "FlexKomSigName" SG_ 849 EngTorqACCCapability "Engine_Torque_Capability";
BA_ "FlexKomSigLaenge" SG_ 849 EngTorqACCCapability 64;
BA_ "FlexKomSID" SG_ 849 EngTorqACCCapability 2130708639;
BA_ "FlexKomIsMotorola" SG_ 849 EngTorqACCCapability 1;
BA_ "FlexKomComment" SG_ 849 EngTorqACCCapability ".";
BA_ "GenSigSNA" SG_ 849 EngTorqCapbltyEngOpMd "0h";
BA_ "GenSigCycleTime" SG_ 849 EngTorqCapbltyEngOpMd 200;
BA_ "FlexKomSigStartValue" SG_ 849 EngTorqCapbltyEngOpMd "03AA03AA000003AAh";
BA_ "FlexKomSigStartPos" SG_ 849 EngTorqCapbltyEngOpMd 7;
BA_ "FlexKomSigName" SG_ 849 EngTorqCapbltyEngOpMd "Engine_Torque_Capability";
BA_ "FlexKomSigLaenge" SG_ 849 EngTorqCapbltyEngOpMd 64;
BA_ "FlexKomSID" SG_ 849 EngTorqCapbltyEngOpMd 2130708639;
BA_ "FlexKomIsMotorola" SG_ 849 EngTorqCapbltyEngOpMd 1;
BA_ "FlexKomComment" SG_ 849 EngTorqCapbltyEngOpMd ".";
BA_ "GenSigSNA" SG_ 849 EngTorqCapbltyFrmCntr "0h";
BA_ "GenSigCycleTime" SG_ 849 EngTorqCapbltyFrmCntr 200;
BA_ "FlexKomSigStartValue" SG_ 849 EngTorqCapbltyFrmCntr "03AA03AA000003AAh";
BA_ "FlexKomSigStartPos" SG_ 849 EngTorqCapbltyFrmCntr 7;
BA_ "FlexKomSigName" SG_ 849 EngTorqCapbltyFrmCntr "Engine_Torque_Capability";
BA_ "FlexKomSigLaenge" SG_ 849 EngTorqCapbltyFrmCntr 64;
BA_ "FlexKomSID" SG_ 849 EngTorqCapbltyFrmCntr 2130708639;
BA_ "FlexKomIsMotorola" SG_ 849 EngTorqCapbltyFrmCntr 1;
BA_ "FlexKomComment" SG_ 849 EngTorqCapbltyFrmCntr ".";
BA_ "GenSigStartValue" SG_ 849 EngTorqCapbltyMaxTorq 938;
BA_ "GenSigSNA" SG_ 849 EngTorqCapbltyMaxTorq "FFFh";
BA_ "GenSigCycleTime" SG_ 849 EngTorqCapbltyMaxTorq 200;
BA_ "FlexKomSigStartValue" SG_ 849 EngTorqCapbltyMaxTorq "03AA03AA000003AAh";
BA_ "FlexKomSigStartPos" SG_ 849 EngTorqCapbltyMaxTorq 7;
BA_ "FlexKomSigName" SG_ 849 EngTorqCapbltyMaxTorq "Engine_Torque_Capability";
BA_ "FlexKomSigLaenge" SG_ 849 EngTorqCapbltyMaxTorq 64;
BA_ "FlexKomSID" SG_ 849 EngTorqCapbltyMaxTorq 2130708639;
BA_ "FlexKomIsMotorola" SG_ 849 EngTorqCapbltyMaxTorq 1;
BA_ "FlexKomComment" SG_ 849 EngTorqCapbltyMaxTorq ".";
BA_ "GenSigStartValue" SG_ 849 EngTorqCapbltyMinRunTorq 938;
BA_ "GenSigSNA" SG_ 849 EngTorqCapbltyMinRunTorq "FFFh";
BA_ "GenSigCycleTime" SG_ 849 EngTorqCapbltyMinRunTorq 200;
BA_ "FlexKomSigStartValue" SG_ 849 EngTorqCapbltyMinRunTorq "03AA03AA000003AAh";
BA_ "FlexKomSigStartPos" SG_ 849 EngTorqCapbltyMinRunTorq 7;
BA_ "FlexKomSigName" SG_ 849 EngTorqCapbltyMinRunTorq "Engine_Torque_Capability";
BA_ "FlexKomSigLaenge" SG_ 849 EngTorqCapbltyMinRunTorq 64;
BA_ "FlexKomSID" SG_ 849 EngTorqCapbltyMinRunTorq 2130708639;
BA_ "FlexKomIsMotorola" SG_ 849 EngTorqCapbltyMinRunTorq 1;
BA_ "FlexKomComment" SG_ 849 EngTorqCapbltyMinRunTorq ".";
BA_ "GenSigStartValue" SG_ 849 EngTorqCapbltyMinTorq 938;
BA_ "GenSigSNA" SG_ 849 EngTorqCapbltyMinTorq "FFFh";
BA_ "GenSigCycleTime" SG_ 849 EngTorqCapbltyMinTorq 200;
BA_ "FlexKomSigStartValue" SG_ 849 EngTorqCapbltyMinTorq "03AA03AA000003AAh";
BA_ "FlexKomSigStartPos" SG_ 849 EngTorqCapbltyMinTorq 7;
BA_ "FlexKomSigName" SG_ 849 EngTorqCapbltyMinTorq "Engine_Torque_Capability";
BA_ "FlexKomSigLaenge" SG_ 849 EngTorqCapbltyMinTorq 64;
BA_ "FlexKomSID" SG_ 849 EngTorqCapbltyMinTorq 2130708639;
BA_ "FlexKomIsMotorola" SG_ 849 EngTorqCapbltyMinTorq 1;
BA_ "FlexKomComment" SG_ 849 EngTorqCapbltyMinTorq ".";
BA_ "GenSigSNA" SG_ 849 EngTorqCapbltyRefEngSpd "0h";
BA_ "GenSigCycleTime" SG_ 849 EngTorqCapbltyRefEngSpd 200;
BA_ "FlexKomSigStartValue" SG_ 849 EngTorqCapbltyRefEngSpd "03AA03AA000003AAh";
BA_ "FlexKomSigStartPos" SG_ 849 EngTorqCapbltyRefEngSpd 7;
BA_ "FlexKomSigName" SG_ 849 EngTorqCapbltyRefEngSpd "Engine_Torque_Capability";
BA_ "FlexKomSigLaenge" SG_ 849 EngTorqCapbltyRefEngSpd 64;
BA_ "FlexKomSID" SG_ 849 EngTorqCapbltyRefEngSpd 2130708639;
BA_ "FlexKomIsMotorola" SG_ 849 EngTorqCapbltyRefEngSpd 1;
BA_ "FlexKomComment" SG_ 849 EngTorqCapbltyRefEngSpd ".";
BA_ "GenSigStartValue" SG_ 395 MaxPrdtdEngTorqCap 938;
BA_ "GenSigSNA" SG_ 395 MaxPrdtdEngTorqCap "FFFh";
BA_ "GenSigCycleTime" SG_ 395 MaxPrdtdEngTorqCap 10;
BA_ "FlexKomSigStartValue" SG_ 395 MaxPrdtdEngTorqCap "03AA03AA03AA03AAh";
BA_ "FlexKomSigStartPos" SG_ 395 MaxPrdtdEngTorqCap 7;
BA_ "FlexKomSigName" SG_ 395 MaxPrdtdEngTorqCap "Engine_Torque_Capacity";
BA_ "FlexKomSigLaenge" SG_ 395 MaxPrdtdEngTorqCap 64;
BA_ "FlexKomSID" SG_ 395 MaxPrdtdEngTorqCap 2130708638;
BA_ "FlexKomIsMotorola" SG_ 395 MaxPrdtdEngTorqCap 1;
BA_ "FlexKomComment" SG_ 395 MaxPrdtdEngTorqCap ".";
BA_ "GenSigSNA" SG_ 395 MaxPrdtdEngTorqCapV "0h";
BA_ "GenSigCycleTime" SG_ 395 MaxPrdtdEngTorqCapV 10;
BA_ "FlexKomSigStartValue" SG_ 395 MaxPrdtdEngTorqCapV "03AA03AA03AA03AAh";
BA_ "FlexKomSigStartPos" SG_ 395 MaxPrdtdEngTorqCapV 7;
BA_ "FlexKomSigName" SG_ 395 MaxPrdtdEngTorqCapV "Engine_Torque_Capacity";
BA_ "FlexKomSigLaenge" SG_ 395 MaxPrdtdEngTorqCapV 64;
BA_ "FlexKomSID" SG_ 395 MaxPrdtdEngTorqCapV 2130708638;
BA_ "FlexKomIsMotorola" SG_ 395 MaxPrdtdEngTorqCapV 1;
BA_ "FlexKomComment" SG_ 395 MaxPrdtdEngTorqCapV ".";
BA_ "GenSigStartValue" SG_ 395 MinEngTorqCap 938;
BA_ "GenSigSNA" SG_ 395 MinEngTorqCap "FFFh";
BA_ "GenSigCycleTime" SG_ 395 MinEngTorqCap 10;
BA_ "FlexKomSigStartValue" SG_ 395 MinEngTorqCap "03AA03AA03AA03AAh";
BA_ "FlexKomSigStartPos" SG_ 395 MinEngTorqCap 7;
BA_ "FlexKomSigName" SG_ 395 MinEngTorqCap "Engine_Torque_Capacity";
BA_ "FlexKomSigLaenge" SG_ 395 MinEngTorqCap 64;
BA_ "FlexKomSID" SG_ 395 MinEngTorqCap 2130708638;
BA_ "FlexKomIsMotorola" SG_ 395 MinEngTorqCap 1;
BA_ "FlexKomComment" SG_ 395 MinEngTorqCap ".";
BA_ "GenSigSNA" SG_ 395 MinEngTorqCapV "0h";
BA_ "GenSigCycleTime" SG_ 395 MinEngTorqCapV 10;
BA_ "FlexKomSigStartValue" SG_ 395 MinEngTorqCapV "03AA03AA03AA03AAh";
BA_ "FlexKomSigStartPos" SG_ 395 MinEngTorqCapV 7;
BA_ "FlexKomSigName" SG_ 395 MinEngTorqCapV "Engine_Torque_Capacity";
BA_ "FlexKomSigLaenge" SG_ 395 MinEngTorqCapV 64;
BA_ "FlexKomSID" SG_ 395 MinEngTorqCapV 2130708638;
BA_ "FlexKomIsMotorola" SG_ 395 MinEngTorqCapV 1;
BA_ "FlexKomComment" SG_ 395 MinEngTorqCapV ".";
BA_ "GenSigStartValue" SG_ 395 MinImmedEngTorqCap 938;
BA_ "GenSigSNA" SG_ 395 MinImmedEngTorqCap "FFFh";
BA_ "GenSigCycleTime" SG_ 395 MinImmedEngTorqCap 10;
BA_ "FlexKomSigStartValue" SG_ 395 MinImmedEngTorqCap "03AA03AA03AA03AAh";
BA_ "FlexKomSigStartPos" SG_ 395 MinImmedEngTorqCap 7;
BA_ "FlexKomSigName" SG_ 395 MinImmedEngTorqCap "Engine_Torque_Capacity";
BA_ "FlexKomSigLaenge" SG_ 395 MinImmedEngTorqCap 64;
BA_ "FlexKomSID" SG_ 395 MinImmedEngTorqCap 2130708638;
BA_ "FlexKomIsMotorola" SG_ 395 MinImmedEngTorqCap 1;
BA_ "FlexKomComment" SG_ 395 MinImmedEngTorqCap ".";
BA_ "GenSigSNA" SG_ 395 MinImmedEngTorqCapV "0h";
BA_ "GenSigCycleTime" SG_ 395 MinImmedEngTorqCapV 10;
BA_ "FlexKomSigStartValue" SG_ 395 MinImmedEngTorqCapV "03AA03AA03AA03AAh";
BA_ "FlexKomSigStartPos" SG_ 395 MinImmedEngTorqCapV 7;
BA_ "FlexKomSigName" SG_ 395 MinImmedEngTorqCapV "Engine_Torque_Capacity";
BA_ "FlexKomSigLaenge" SG_ 395 MinImmedEngTorqCapV 64;
BA_ "FlexKomSID" SG_ 395 MinImmedEngTorqCapV 2130708638;
BA_ "FlexKomIsMotorola" SG_ 395 MinImmedEngTorqCapV 1;
BA_ "FlexKomComment" SG_ 395 MinImmedEngTorqCapV ".";
BA_ "GenSigStartValue" SG_ 395 MinPrdtdEngRunTorqCap 938;
BA_ "GenSigSNA" SG_ 395 MinPrdtdEngRunTorqCap "FFFh";
BA_ "GenSigCycleTime" SG_ 395 MinPrdtdEngRunTorqCap 10;
BA_ "FlexKomSigStartValue" SG_ 395 MinPrdtdEngRunTorqCap "03AA03AA03AA03AAh";
BA_ "FlexKomSigStartPos" SG_ 395 MinPrdtdEngRunTorqCap 7;
BA_ "FlexKomSigName" SG_ 395 MinPrdtdEngRunTorqCap "Engine_Torque_Capacity";
BA_ "FlexKomSigLaenge" SG_ 395 MinPrdtdEngRunTorqCap 64;
BA_ "FlexKomSID" SG_ 395 MinPrdtdEngRunTorqCap 2130708638;
BA_ "FlexKomIsMotorola" SG_ 395 MinPrdtdEngRunTorqCap 1;
BA_ "FlexKomComment" SG_ 395 MinPrdtdEngRunTorqCap ".";
BA_ "GenSigSNA" SG_ 395 MinPrdtdEngRunTorqCapV "0h";
BA_ "GenSigCycleTime" SG_ 395 MinPrdtdEngRunTorqCapV 10;
BA_ "FlexKomSigStartValue" SG_ 395 MinPrdtdEngRunTorqCapV "03AA03AA03AA03AAh";
BA_ "FlexKomSigStartPos" SG_ 395 MinPrdtdEngRunTorqCapV 7;
BA_ "FlexKomSigName" SG_ 395 MinPrdtdEngRunTorqCapV "Engine_Torque_Capacity";
BA_ "FlexKomSigLaenge" SG_ 395 MinPrdtdEngRunTorqCapV 64;
BA_ "FlexKomSID" SG_ 395 MinPrdtdEngRunTorqCapV 2130708638;
BA_ "FlexKomIsMotorola" SG_ 395 MinPrdtdEngRunTorqCapV 1;
BA_ "FlexKomComment" SG_ 395 MinPrdtdEngRunTorqCapV ".";
BA_ "GenSigSNA" SG_ 401 AccPos "0h";
BA_ "GenSigCycleTime" SG_ 401 AccPos 10;
BA_ "FlexKomSigStartValue" SG_ 401 AccPos "000003AA03AA00FFh";
BA_ "FlexKomSigStartPos" SG_ 401 AccPos 7;
BA_ "FlexKomSigName" SG_ 401 AccPos "Engine_Torque_Status";
BA_ "FlexKomSigLaenge" SG_ 401 AccPos 64;
BA_ "FlexKomSID" SG_ 401 AccPos 2130708640;
BA_ "FlexKomIsMotorola" SG_ 401 AccPos 1;
BA_ "FlexKomComment" SG_ 401 AccPos ".";
BA_ "GenSigSNA" SG_ 401 AccPosV "0h";
BA_ "GenSigCycleTime" SG_ 401 AccPosV 10;
BA_ "FlexKomSigStartValue" SG_ 401 AccPosV "000003AA03AA00FFh";
BA_ "FlexKomSigStartPos" SG_ 401 AccPosV 7;
BA_ "FlexKomSigName" SG_ 401 AccPosV "Engine_Torque_Status";
BA_ "FlexKomSigLaenge" SG_ 401 AccPosV 64;
BA_ "FlexKomSID" SG_ 401 AccPosV 2130708640;
BA_ "FlexKomIsMotorola" SG_ 401 AccPosV 1;
BA_ "FlexKomComment" SG_ 401 AccPosV ".";
BA_ "GenSigStartValue" SG_ 401 CRC_191h 255;
BA_ "GenSigSNA" SG_ 401 CRC_191h "FFh";
BA_ "GenSigCycleTime" SG_ 401 CRC_191h 10;
BA_ "FlexKomSigStartValue" SG_ 401 CRC_191h "000003AA03AA00FFh";
BA_ "FlexKomSigStartPos" SG_ 401 CRC_191h 7;
BA_ "FlexKomSigName" SG_ 401 CRC_191h "Engine_Torque_Status";
BA_ "FlexKomSigLaenge" SG_ 401 CRC_191h 64;
BA_ "FlexKomSID" SG_ 401 CRC_191h 2130708640;
BA_ "FlexKomIsMotorola" SG_ 401 CRC_191h 1;
BA_ "FlexKomComment" SG_ 401 CRC_191h ".";
BA_ "GenSigSNA" SG_ 401 ECM_IMMO_STAT_CANePT "3h";
BA_ "GenSigCycleTime" SG_ 401 ECM_IMMO_STAT_CANePT 10;
BA_ "FlexKomSigStartValue" SG_ 401 ECM_IMMO_STAT_CANePT "000003AA03AA00FFh";
BA_ "FlexKomSigStartPos" SG_ 401 ECM_IMMO_STAT_CANePT 7;
BA_ "FlexKomSigName" SG_ 401 ECM_IMMO_STAT_CANePT "Engine_Torque_Status";
BA_ "FlexKomSigLaenge" SG_ 401 ECM_IMMO_STAT_CANePT 64;
BA_ "FlexKomSID" SG_ 401 ECM_IMMO_STAT_CANePT 2130708640;
BA_ "FlexKomIsMotorola" SG_ 401 ECM_IMMO_STAT_CANePT 1;
BA_ "FlexKomComment" SG_ 401 ECM_IMMO_STAT_CANePT ".";
BA_ "GenSigStartValue" SG_ 401 EngActStdyStTorq 938;
BA_ "GenSigSNA" SG_ 401 EngActStdyStTorq "FFFh";
BA_ "GenSigCycleTime" SG_ 401 EngActStdyStTorq 10;
BA_ "FlexKomSigStartValue" SG_ 401 EngActStdyStTorq "000003AA03AA00FFh";
BA_ "FlexKomSigStartPos" SG_ 401 EngActStdyStTorq 7;
BA_ "FlexKomSigName" SG_ 401 EngActStdyStTorq "Engine_Torque_Status";
BA_ "FlexKomSigLaenge" SG_ 401 EngActStdyStTorq 64;
BA_ "FlexKomSID" SG_ 401 EngActStdyStTorq 2130708640;
BA_ "FlexKomIsMotorola" SG_ 401 EngActStdyStTorq 1;
BA_ "FlexKomComment" SG_ 401 EngActStdyStTorq ".";
BA_ "GenSigSNA" SG_ 401 EngActStdyStTorqV "0h";
BA_ "GenSigCycleTime" SG_ 401 EngActStdyStTorqV 10;
BA_ "FlexKomSigStartValue" SG_ 401 EngActStdyStTorqV "000003AA03AA00FFh";
BA_ "FlexKomSigStartPos" SG_ 401 EngActStdyStTorqV 7;
BA_ "FlexKomSigName" SG_ 401 EngActStdyStTorqV "Engine_Torque_Status";
BA_ "FlexKomSigLaenge" SG_ 401 EngActStdyStTorqV 64;
BA_ "FlexKomSID" SG_ 401 EngActStdyStTorqV 2130708640;
BA_ "FlexKomIsMotorola" SG_ 401 EngActStdyStTorqV 1;
BA_ "FlexKomComment" SG_ 401 EngActStdyStTorqV ".";
BA_ "GenSigStartValue" SG_ 401 EngAirFlwStdyStTorq 938;
BA_ "GenSigSNA" SG_ 401 EngAirFlwStdyStTorq "FFFh";
BA_ "GenSigCycleTime" SG_ 401 EngAirFlwStdyStTorq 10;
BA_ "FlexKomSigStartValue" SG_ 401 EngAirFlwStdyStTorq "000003AA03AA00FFh";
BA_ "FlexKomSigStartPos" SG_ 401 EngAirFlwStdyStTorq 7;
BA_ "FlexKomSigName" SG_ 401 EngAirFlwStdyStTorq "Engine_Torque_Status";
BA_ "FlexKomSigLaenge" SG_ 401 EngAirFlwStdyStTorq 64;
BA_ "FlexKomSID" SG_ 401 EngAirFlwStdyStTorq 2130708640;
BA_ "FlexKomIsMotorola" SG_ 401 EngAirFlwStdyStTorq 1;
BA_ "FlexKomComment" SG_ 401 EngAirFlwStdyStTorq ".";
BA_ "GenSigSNA" SG_ 401 EngAirFlwStdyStTorqV "0h";
BA_ "GenSigCycleTime" SG_ 401 EngAirFlwStdyStTorqV 10;
BA_ "FlexKomSigStartValue" SG_ 401 EngAirFlwStdyStTorqV "000003AA03AA00FFh";
BA_ "FlexKomSigStartPos" SG_ 401 EngAirFlwStdyStTorqV 7;
BA_ "FlexKomSigName" SG_ 401 EngAirFlwStdyStTorqV "Engine_Torque_Status";
BA_ "FlexKomSigLaenge" SG_ 401 EngAirFlwStdyStTorqV 64;
BA_ "FlexKomSID" SG_ 401 EngAirFlwStdyStTorqV 2130708640;
BA_ "FlexKomIsMotorola" SG_ 401 EngAirFlwStdyStTorqV 1;
BA_ "FlexKomComment" SG_ 401 EngAirFlwStdyStTorqV ".";
BA_ "GenSigSNA" SG_ 401 EngDFCO_Allw "0h";
BA_ "GenSigCycleTime" SG_ 401 EngDFCO_Allw 10;
BA_ "FlexKomSigStartValue" SG_ 401 EngDFCO_Allw "000003AA03AA00FFh";
BA_ "FlexKomSigStartPos" SG_ 401 EngDFCO_Allw 7;
BA_ "FlexKomSigName" SG_ 401 EngDFCO_Allw "Engine_Torque_Status";
BA_ "FlexKomSigLaenge" SG_ 401 EngDFCO_Allw 64;
BA_ "FlexKomSID" SG_ 401 EngDFCO_Allw 2130708640;
BA_ "FlexKomIsMotorola" SG_ 401 EngDFCO_Allw 1;
BA_ "FlexKomComment" SG_ 401 EngDFCO_Allw ".";
BA_ "GenSigSNA" SG_ 401 EngDFCO_Req "0h";
BA_ "GenSigCycleTime" SG_ 401 EngDFCO_Req 10;
BA_ "FlexKomSigStartValue" SG_ 401 EngDFCO_Req "000003AA03AA00FFh";
BA_ "FlexKomSigStartPos" SG_ 401 EngDFCO_Req 7;
BA_ "FlexKomSigName" SG_ 401 EngDFCO_Req "Engine_Torque_Status";
BA_ "FlexKomSigLaenge" SG_ 401 EngDFCO_Req 64;
BA_ "FlexKomSID" SG_ 401 EngDFCO_Req 2130708640;
BA_ "FlexKomIsMotorola" SG_ 401 EngDFCO_Req 1;
BA_ "FlexKomComment" SG_ 401 EngDFCO_Req ".";
BA_ "GenSigSNA" SG_ 401 EngDFCO_St "0h";
BA_ "GenSigCycleTime" SG_ 401 EngDFCO_St 10;
BA_ "FlexKomSigStartValue" SG_ 401 EngDFCO_St "000003AA03AA00FFh";
BA_ "FlexKomSigStartPos" SG_ 401 EngDFCO_St 7;
BA_ "FlexKomSigName" SG_ 401 EngDFCO_St "Engine_Torque_Status";
BA_ "FlexKomSigLaenge" SG_ 401 EngDFCO_St 64;
BA_ "FlexKomSID" SG_ 401 EngDFCO_St 2130708640;
BA_ "FlexKomIsMotorola" SG_ 401 EngDFCO_St 1;
BA_ "FlexKomComment" SG_ 401 EngDFCO_St ".";
BA_ "GenSigSNA" SG_ 401 EngRunCrnkAct "0h";
BA_ "GenSigCycleTime" SG_ 401 EngRunCrnkAct 10;
BA_ "FlexKomSigStartValue" SG_ 401 EngRunCrnkAct "000003AA03AA00FFh";
BA_ "FlexKomSigStartPos" SG_ 401 EngRunCrnkAct 7;
BA_ "FlexKomSigName" SG_ 401 EngRunCrnkAct "Engine_Torque_Status";
BA_ "FlexKomSigLaenge" SG_ 401 EngRunCrnkAct 64;
BA_ "FlexKomSID" SG_ 401 EngRunCrnkAct 2130708640;
BA_ "FlexKomIsMotorola" SG_ 401 EngRunCrnkAct 1;
BA_ "FlexKomComment" SG_ 401 EngRunCrnkAct ".";
BA_ "GenSigSNA" SG_ 401 HybActEngTorqRespTyp "0h";
BA_ "GenSigCycleTime" SG_ 401 HybActEngTorqRespTyp 10;
BA_ "FlexKomSigStartValue" SG_ 401 HybActEngTorqRespTyp "000003AA03AA00FFh";
BA_ "FlexKomSigStartPos" SG_ 401 HybActEngTorqRespTyp 7;
BA_ "FlexKomSigName" SG_ 401 HybActEngTorqRespTyp "Engine_Torque_Status";
BA_ "FlexKomSigLaenge" SG_ 401 HybActEngTorqRespTyp 64;
BA_ "FlexKomSID" SG_ 401 HybActEngTorqRespTyp 2130708640;
BA_ "FlexKomIsMotorola" SG_ 401 HybActEngTorqRespTyp 1;
BA_ "FlexKomComment" SG_ 401 HybActEngTorqRespTyp ".";
BA_ "GenSigSNA" SG_ 401 MC_191h "0h";
BA_ "GenSigCycleTime" SG_ 401 MC_191h 10;
BA_ "FlexKomSigStartValue" SG_ 401 MC_191h "000003AA03AA00FFh";
BA_ "FlexKomSigStartPos" SG_ 401 MC_191h 7;
BA_ "FlexKomSigName" SG_ 401 MC_191h "Engine_Torque_Status";
BA_ "FlexKomSigLaenge" SG_ 401 MC_191h 64;
BA_ "FlexKomSID" SG_ 401 MC_191h 2130708640;
BA_ "FlexKomIsMotorola" SG_ 401 MC_191h 1;
BA_ "FlexKomComment" SG_ 401 MC_191h ".";
BA_ "GenSigSNA" SG_ 401 PTCrnkAbrted "0h";
BA_ "GenSigCycleTime" SG_ 401 PTCrnkAbrted 10;
BA_ "FlexKomSigStartValue" SG_ 401 PTCrnkAbrted "000003AA03AA00FFh";
BA_ "FlexKomSigStartPos" SG_ 401 PTCrnkAbrted 7;
BA_ "FlexKomSigName" SG_ 401 PTCrnkAbrted "Engine_Torque_Status";
BA_ "FlexKomSigLaenge" SG_ 401 PTCrnkAbrted 64;
BA_ "FlexKomSID" SG_ 401 PTCrnkAbrted 2130708640;
BA_ "FlexKomIsMotorola" SG_ 401 PTCrnkAbrted 1;
BA_ "FlexKomComment" SG_ 401 PTCrnkAbrted ".";
BA_ "GenSigSNA" SG_ 401 PT_CrnkAct "0h";
BA_ "GenSigCycleTime" SG_ 401 PT_CrnkAct 10;
BA_ "FlexKomSigStartValue" SG_ 401 PT_CrnkAct "000003AA03AA00FFh";
BA_ "FlexKomSigStartPos" SG_ 401 PT_CrnkAct 7;
BA_ "FlexKomSigName" SG_ 401 PT_CrnkAct "Engine_Torque_Status";
BA_ "FlexKomSigLaenge" SG_ 401 PT_CrnkAct 64;
BA_ "FlexKomSID" SG_ 401 PT_CrnkAct 2130708640;
BA_ "FlexKomIsMotorola" SG_ 401 PT_CrnkAct 1;
BA_ "FlexKomComment" SG_ 401 PT_CrnkAct ".";
BA_ "GenSigSNA" SG_ 401 TLC_LRN_Rq "0h";
BA_ "GenSigCycleTime" SG_ 401 TLC_LRN_Rq 10;
BA_ "FlexKomSigStartValue" SG_ 401 TLC_LRN_Rq "000003AA03AA00FFh";
BA_ "FlexKomSigStartPos" SG_ 401 TLC_LRN_Rq 7;
BA_ "FlexKomSigName" SG_ 401 TLC_LRN_Rq "Engine_Torque_Status";
BA_ "FlexKomSigLaenge" SG_ 401 TLC_LRN_Rq 64;
BA_ "FlexKomSID" SG_ 401 TLC_LRN_Rq 2130708640;
BA_ "FlexKomIsMotorola" SG_ 401 TLC_LRN_Rq 1;
BA_ "FlexKomComment" SG_ 401 TLC_LRN_Rq ".";
BA_ "GenSigStartValue" SG_ 908 GPS_Date_Day 255;
BA_ "GenSigSNA" SG_ 908 GPS_Date_Day "FFh";
BA_ "GenSigCycleTime" SG_ 908 GPS_Date_Day 1000;
BA_ "FlexKomSigStartValue" SG_ 908 GPS_Date_Day "FFFFFFFFFFFFFFFFh";
BA_ "FlexKomSigStartPos" SG_ 908 GPS_Date_Day 7;
BA_ "FlexKomSigName" SG_ 908 GPS_Date_Day "GPS_Date_UTC";
BA_ "FlexKomSigLaenge" SG_ 908 GPS_Date_Day 64;
BA_ "FlexKomSID" SG_ 908 GPS_Date_Day 566;
BA_ "FlexKomIsMotorola" SG_ 908 GPS_Date_Day 1;
BA_ "FlexKomComment" SG_ 908 GPS_Date_Day "GPS Date and UTC";
BA_ "GenSigStartValue" SG_ 908 GPS_Date_Month 255;
BA_ "GenSigSNA" SG_ 908 GPS_Date_Month "FFh";
BA_ "GenSigCycleTime" SG_ 908 GPS_Date_Month 1000;
BA_ "FlexKomSigStartValue" SG_ 908 GPS_Date_Month "FFFFFFFFFFFFFFFFh";
BA_ "FlexKomSigStartPos" SG_ 908 GPS_Date_Month 7;
BA_ "FlexKomSigName" SG_ 908 GPS_Date_Month "GPS_Date_UTC";
BA_ "FlexKomSigLaenge" SG_ 908 GPS_Date_Month 64;
BA_ "FlexKomSID" SG_ 908 GPS_Date_Month 566;
BA_ "FlexKomIsMotorola" SG_ 908 GPS_Date_Month 1;
BA_ "FlexKomComment" SG_ 908 GPS_Date_Month "GPS Date and UTC";
BA_ "GenSigStartValue" SG_ 908 GPS_Date_Year 65535;
BA_ "GenSigSNA" SG_ 908 GPS_Date_Year "FFFFh";
BA_ "GenSigCycleTime" SG_ 908 GPS_Date_Year 1000;
BA_ "FlexKomSigStartValue" SG_ 908 GPS_Date_Year "FFFFFFFFFFFFFFFFh";
BA_ "FlexKomSigStartPos" SG_ 908 GPS_Date_Year 7;
BA_ "FlexKomSigName" SG_ 908 GPS_Date_Year "GPS_Date_UTC";
BA_ "FlexKomSigLaenge" SG_ 908 GPS_Date_Year 64;
BA_ "FlexKomSID" SG_ 908 GPS_Date_Year 566;
BA_ "FlexKomIsMotorola" SG_ 908 GPS_Date_Year 1;
BA_ "FlexKomComment" SG_ 908 GPS_Date_Year "GPS Date and UTC";
BA_ "GenSigStartValue" SG_ 908 GPS_UTC_Hour 255;
BA_ "GenSigSNA" SG_ 908 GPS_UTC_Hour "FFh";
BA_ "GenSigCycleTime" SG_ 908 GPS_UTC_Hour 1000;
BA_ "FlexKomSigStartValue" SG_ 908 GPS_UTC_Hour "FFFFFFFFFFFFFFFFh";
BA_ "FlexKomSigStartPos" SG_ 908 GPS_UTC_Hour 7;
BA_ "FlexKomSigName" SG_ 908 GPS_UTC_Hour "GPS_Date_UTC";
BA_ "FlexKomSigLaenge" SG_ 908 GPS_UTC_Hour 64;
BA_ "FlexKomSID" SG_ 908 GPS_UTC_Hour 566;
BA_ "FlexKomIsMotorola" SG_ 908 GPS_UTC_Hour 1;
BA_ "FlexKomComment" SG_ 908 GPS_UTC_Hour "GPS Date and UTC";
BA_ "GenSigStartValue" SG_ 908 GPS_UTC_Minute 255;
BA_ "GenSigSNA" SG_ 908 GPS_UTC_Minute "FFh";
BA_ "GenSigCycleTime" SG_ 908 GPS_UTC_Minute 1000;
BA_ "FlexKomSigStartValue" SG_ 908 GPS_UTC_Minute "FFFFFFFFFFFFFFFFh";
BA_ "FlexKomSigStartPos" SG_ 908 GPS_UTC_Minute 7;
BA_ "FlexKomSigName" SG_ 908 GPS_UTC_Minute "GPS_Date_UTC";
BA_ "FlexKomSigLaenge" SG_ 908 GPS_UTC_Minute 64;
BA_ "FlexKomSID" SG_ 908 GPS_UTC_Minute 566;
BA_ "FlexKomIsMotorola" SG_ 908 GPS_UTC_Minute 1;
BA_ "FlexKomComment" SG_ 908 GPS_UTC_Minute "GPS Date and UTC";
BA_ "GenSigStartValue" SG_ 908 GPS_UTC_Second 65535;
BA_ "GenSigSNA" SG_ 908 GPS_UTC_Second "FFFFh";
BA_ "GenSigCycleTime" SG_ 908 GPS_UTC_Second 1000;
BA_ "FlexKomSigStartValue" SG_ 908 GPS_UTC_Second "FFFFFFFFFFFFFFFFh";
BA_ "FlexKomSigStartPos" SG_ 908 GPS_UTC_Second 7;
BA_ "FlexKomSigName" SG_ 908 GPS_UTC_Second "GPS_Date_UTC";
BA_ "FlexKomSigLaenge" SG_ 908 GPS_UTC_Second 64;
BA_ "FlexKomSID" SG_ 908 GPS_UTC_Second 566;
BA_ "FlexKomIsMotorola" SG_ 908 GPS_UTC_Second 1;
BA_ "FlexKomComment" SG_ 908 GPS_UTC_Second "GPS Date and UTC";
BA_ "GenSigStartValue" SG_ 564 APM_IdcHvSetP 229;
BA_ "GenSigSNA" SG_ 564 APM_IdcHvSetP "FFh";
BA_ "GenSigCycleTime" SG_ 564 APM_IdcHvSetP 50;
BA_ "FlexKomSigStartValue" SG_ 564 APM_IdcHvSetP "DDE50000000000FFh";
BA_ "FlexKomSigStartPos" SG_ 564 APM_IdcHvSetP 7;
BA_ "FlexKomSigName" SG_ 564 APM_IdcHvSetP "HCP_APM_Command";
BA_ "FlexKomSigLaenge" SG_ 564 APM_IdcHvSetP 64;
BA_ "FlexKomSID" SG_ 564 APM_IdcHvSetP 2130708641;
BA_ "FlexKomIsMotorola" SG_ 564 APM_IdcHvSetP 1;
BA_ "FlexKomComment" SG_ 564 APM_IdcHvSetP ".";
BA_ "GenSigStartValue" SG_ 564 APM_IdcLvSetP 255;
BA_ "GenSigSNA" SG_ 564 APM_IdcLvSetP "1FFh";
BA_ "GenSigCycleTime" SG_ 564 APM_IdcLvSetP 50;
BA_ "FlexKomSigStartValue" SG_ 564 APM_IdcLvSetP "DDE50000000000FFh";
BA_ "FlexKomSigStartPos" SG_ 564 APM_IdcLvSetP 7;
BA_ "FlexKomSigName" SG_ 564 APM_IdcLvSetP "HCP_APM_Command";
BA_ "FlexKomSigLaenge" SG_ 564 APM_IdcLvSetP 64;
BA_ "FlexKomSID" SG_ 564 APM_IdcLvSetP 2130708641;
BA_ "FlexKomIsMotorola" SG_ 564 APM_IdcLvSetP 1;
BA_ "FlexKomComment" SG_ 564 APM_IdcLvSetP ".";
BA_ "GenSigSNA" SG_ 564 APM_OperModeEnable "Fh";
BA_ "GenSigCycleTime" SG_ 564 APM_OperModeEnable 50;
BA_ "FlexKomSigStartValue" SG_ 564 APM_OperModeEnable "DDE50000000000FFh";
BA_ "FlexKomSigStartPos" SG_ 564 APM_OperModeEnable 7;
BA_ "FlexKomSigName" SG_ 564 APM_OperModeEnable "HCP_APM_Command";
BA_ "FlexKomSigLaenge" SG_ 564 APM_OperModeEnable 64;
BA_ "FlexKomSID" SG_ 564 APM_OperModeEnable 2130708641;
BA_ "FlexKomIsMotorola" SG_ 564 APM_OperModeEnable 1;
BA_ "FlexKomComment" SG_ 564 APM_OperModeEnable ".";
BA_ "GenSigSNA" SG_ 564 APM_VdcHvSetP "1FFh";
BA_ "GenSigCycleTime" SG_ 564 APM_VdcHvSetP 50;
BA_ "FlexKomSigStartValue" SG_ 564 APM_VdcHvSetP "DDE50000000000FFh";
BA_ "FlexKomSigStartPos" SG_ 564 APM_VdcHvSetP 7;
BA_ "FlexKomSigName" SG_ 564 APM_VdcHvSetP "HCP_APM_Command";
BA_ "FlexKomSigLaenge" SG_ 564 APM_VdcHvSetP 64;
BA_ "FlexKomSID" SG_ 564 APM_VdcHvSetP 2130708641;
BA_ "FlexKomIsMotorola" SG_ 564 APM_VdcHvSetP 1;
BA_ "FlexKomComment" SG_ 564 APM_VdcHvSetP ".";
BA_ "GenSigSNA" SG_ 564 APM_VdcLvAct "1FFh";
BA_ "GenSigCycleTime" SG_ 564 APM_VdcLvAct 50;
BA_ "FlexKomSigStartValue" SG_ 564 APM_VdcLvAct "DDE50000000000FFh";
BA_ "FlexKomSigStartPos" SG_ 564 APM_VdcLvAct 7;
BA_ "FlexKomSigName" SG_ 564 APM_VdcLvAct "HCP_APM_Command";
BA_ "FlexKomSigLaenge" SG_ 564 APM_VdcLvAct 64;
BA_ "FlexKomSID" SG_ 564 APM_VdcLvAct 2130708641;
BA_ "FlexKomIsMotorola" SG_ 564 APM_VdcLvAct 1;
BA_ "FlexKomComment" SG_ 564 APM_VdcLvAct ".";
BA_ "GenSigStartValue" SG_ 564 APM_VdcLvSetP 221;
BA_ "GenSigSNA" SG_ 564 APM_VdcLvSetP "FFh";
BA_ "GenSigCycleTime" SG_ 564 APM_VdcLvSetP 50;
BA_ "FlexKomSigStartValue" SG_ 564 APM_VdcLvSetP "DDE50000000000FFh";
BA_ "FlexKomSigStartPos" SG_ 564 APM_VdcLvSetP 7;
BA_ "FlexKomSigName" SG_ 564 APM_VdcLvSetP "HCP_APM_Command";
BA_ "FlexKomSigLaenge" SG_ 564 APM_VdcLvSetP 64;
BA_ "FlexKomSID" SG_ 564 APM_VdcLvSetP 2130708641;
BA_ "FlexKomIsMotorola" SG_ 564 APM_VdcLvSetP 1;
BA_ "FlexKomComment" SG_ 564 APM_VdcLvSetP ".";
BA_ "GenSigSNA" SG_ 977 ChargingLevel "Fh";
BA_ "GenSigCycleTime" SG_ 977 ChargingLevel 500;
BA_ "FlexKomSigStartValue" SG_ 977 ChargingLevel "0000000000000000h";
BA_ "FlexKomSigStartPos" SG_ 977 ChargingLevel 7;
BA_ "FlexKomSigName" SG_ 977 ChargingLevel "HCP_Charging_Stat2";
BA_ "FlexKomSigLaenge" SG_ 977 ChargingLevel 64;
BA_ "FlexKomSID" SG_ 977 ChargingLevel 2130708642;
BA_ "FlexKomIsMotorola" SG_ 977 ChargingLevel 1;
BA_ "FlexKomComment" SG_ 977 ChargingLevel ".";
BA_ "GenSigSNA" SG_ 977 ChargingSysSts "7h";
BA_ "GenSigCycleTime" SG_ 977 ChargingSysSts 500;
BA_ "FlexKomSigStartValue" SG_ 977 ChargingSysSts "0000000000000000h";
BA_ "FlexKomSigStartPos" SG_ 977 ChargingSysSts 7;
BA_ "FlexKomSigName" SG_ 977 ChargingSysSts "HCP_Charging_Stat2";
BA_ "FlexKomSigLaenge" SG_ 977 ChargingSysSts 64;
BA_ "FlexKomSID" SG_ 977 ChargingSysSts 2130708642;
BA_ "FlexKomIsMotorola" SG_ 977 ChargingSysSts 1;
BA_ "FlexKomComment" SG_ 977 ChargingSysSts ".";
BA_ "GenSigSNA" SG_ 977 ChrgSysFault "0h";
BA_ "GenSigCycleTime" SG_ 977 ChrgSysFault 500;
BA_ "FlexKomSigStartValue" SG_ 977 ChrgSysFault "0000000000000000h";
BA_ "FlexKomSigStartPos" SG_ 977 ChrgSysFault 7;
BA_ "FlexKomSigName" SG_ 977 ChrgSysFault "HCP_Charging_Stat2";
BA_ "FlexKomSigLaenge" SG_ 977 ChrgSysFault 64;
BA_ "FlexKomSID" SG_ 977 ChrgSysFault 2130708642;
BA_ "FlexKomIsMotorola" SG_ 977 ChrgSysFault 1;
BA_ "FlexKomComment" SG_ 977 ChrgSysFault ".";
BA_ "GenSigSNA" SG_ 977 ChrgSysFault_Reason "3Fh";
BA_ "GenSigCycleTime" SG_ 977 ChrgSysFault_Reason 500;
BA_ "FlexKomSigStartValue" SG_ 977 ChrgSysFault_Reason "0000000000000000h";
BA_ "FlexKomSigStartPos" SG_ 977 ChrgSysFault_Reason 7;
BA_ "FlexKomSigName" SG_ 977 ChrgSysFault_Reason "HCP_Charging_Stat2";
BA_ "FlexKomSigLaenge" SG_ 977 ChrgSysFault_Reason 64;
BA_ "FlexKomSID" SG_ 977 ChrgSysFault_Reason 2130708642;
BA_ "FlexKomIsMotorola" SG_ 977 ChrgSysFault_Reason 1;
BA_ "FlexKomComment" SG_ 977 ChrgSysFault_Reason ".";
BA_ "GenSigSNA" SG_ 676 AirFlowReq "7Fh";
BA_ "GenSigCycleTime" SG_ 676 AirFlowReq 100;
BA_ "FlexKomSigStartValue" SG_ 676 AirFlowReq "0000C0000000E000h";
BA_ "FlexKomSigStartPos" SG_ 676 AirFlowReq 7;
BA_ "FlexKomSigName" SG_ 676 AirFlowReq "HCP_DriverInfo";
BA_ "FlexKomSigLaenge" SG_ 676 AirFlowReq 64;
BA_ "FlexKomSID" SG_ 676 AirFlowReq 2130708643;
BA_ "FlexKomIsMotorola" SG_ 676 AirFlowReq 1;
BA_ "FlexKomComment" SG_ 676 AirFlowReq ".";
BA_ "GenSigSNA" SG_ 676 ChillerVlvSts "0h";
BA_ "GenSigCycleTime" SG_ 676 ChillerVlvSts 100;
BA_ "FlexKomSigStartValue" SG_ 676 ChillerVlvSts "0000C0000000E000h";
BA_ "FlexKomSigStartPos" SG_ 676 ChillerVlvSts 7;
BA_ "FlexKomSigName" SG_ 676 ChillerVlvSts "HCP_DriverInfo";
BA_ "FlexKomSigLaenge" SG_ 676 ChillerVlvSts 64;
BA_ "FlexKomSID" SG_ 676 ChillerVlvSts 2130708643;
BA_ "FlexKomIsMotorola" SG_ 676 ChillerVlvSts 1;
BA_ "FlexKomComment" SG_ 676 ChillerVlvSts ".";
BA_ "GenSigSNA" SG_ 676 CompSpdReq "3FFFh";
BA_ "GenSigCycleTime" SG_ 676 CompSpdReq 100;
BA_ "FlexKomSigStartValue" SG_ 676 CompSpdReq "0000C0000000E000h";
BA_ "FlexKomSigStartPos" SG_ 676 CompSpdReq 7;
BA_ "FlexKomSigName" SG_ 676 CompSpdReq "HCP_DriverInfo";
BA_ "FlexKomSigLaenge" SG_ 676 CompSpdReq 64;
BA_ "FlexKomSID" SG_ 676 CompSpdReq 2130708643;
BA_ "FlexKomIsMotorola" SG_ 676 CompSpdReq 1;
BA_ "FlexKomComment" SG_ 676 CompSpdReq ".";
BA_ "GenSigSNA" SG_ 676 HVBatSOCV_HCP "0h";
BA_ "GenSigCycleTime" SG_ 676 HVBatSOCV_HCP 100;
BA_ "FlexKomSigStartValue" SG_ 676 HVBatSOCV_HCP "0000C0000000E000h";
BA_ "FlexKomSigStartPos" SG_ 676 HVBatSOCV_HCP 7;
BA_ "FlexKomSigName" SG_ 676 HVBatSOCV_HCP "HCP_DriverInfo";
BA_ "FlexKomSigLaenge" SG_ 676 HVBatSOCV_HCP 64;
BA_ "FlexKomSID" SG_ 676 HVBatSOCV_HCP 2130708643;
BA_ "FlexKomIsMotorola" SG_ 676 HVBatSOCV_HCP 1;
BA_ "FlexKomComment" SG_ 676 HVBatSOCV_HCP ".";
BA_ "GenSigSNA" SG_ 676 HVBatSOC_HCP "0h";
BA_ "GenSigCycleTime" SG_ 676 HVBatSOC_HCP 100;
BA_ "FlexKomSigStartValue" SG_ 676 HVBatSOC_HCP "0000C0000000E000h";
BA_ "FlexKomSigStartPos" SG_ 676 HVBatSOC_HCP 7;
BA_ "FlexKomSigName" SG_ 676 HVBatSOC_HCP "HCP_DriverInfo";
BA_ "FlexKomSigLaenge" SG_ 676 HVBatSOC_HCP 64;
BA_ "FlexKomSID" SG_ 676 HVBatSOC_HCP 2130708643;
BA_ "FlexKomIsMotorola" SG_ 676 HVBatSOC_HCP 1;
BA_ "FlexKomComment" SG_ 676 HVBatSOC_HCP ".";
BA_ "GenSigSNA" SG_ 676 LTActPumpCmd "FFh";
BA_ "GenSigCycleTime" SG_ 676 LTActPumpCmd 100;
BA_ "FlexKomSigStartValue" SG_ 676 LTActPumpCmd "0000C0000000E000h";
BA_ "FlexKomSigStartPos" SG_ 676 LTActPumpCmd 7;
BA_ "FlexKomSigName" SG_ 676 LTActPumpCmd "HCP_DriverInfo";
BA_ "FlexKomSigLaenge" SG_ 676 LTActPumpCmd 64;
BA_ "FlexKomSID" SG_ 676 LTActPumpCmd 2130708643;
BA_ "FlexKomIsMotorola" SG_ 676 LTActPumpCmd 1;
BA_ "FlexKomComment" SG_ 676 LTActPumpCmd ".";
BA_ "GenSigStartValue" SG_ 676 LTActPumpFailsafe_ACT 3;
BA_ "GenSigSNA" SG_ 676 LTActPumpFailsafe_ACT "3h";
BA_ "GenSigCycleTime" SG_ 676 LTActPumpFailsafe_ACT 100;
BA_ "FlexKomSigStartValue" SG_ 676 LTActPumpFailsafe_ACT "0000C0000000E000h";
BA_ "FlexKomSigStartPos" SG_ 676 LTActPumpFailsafe_ACT 7;
BA_ "FlexKomSigName" SG_ 676 LTActPumpFailsafe_ACT "HCP_DriverInfo";
BA_ "FlexKomSigLaenge" SG_ 676 LTActPumpFailsafe_ACT 64;
BA_ "FlexKomSID" SG_ 676 LTActPumpFailsafe_ACT 2130708643;
BA_ "FlexKomIsMotorola" SG_ 676 LTActPumpFailsafe_ACT 1;
BA_ "FlexKomComment" SG_ 676 LTActPumpFailsafe_ACT ".";
BA_ "GenSigStartValue" SG_ 676 LTActPumpPostRunCom 7;
BA_ "GenSigSNA" SG_ 676 LTActPumpPostRunCom "7h";
BA_ "GenSigCycleTime" SG_ 676 LTActPumpPostRunCom 100;
BA_ "FlexKomSigStartValue" SG_ 676 LTActPumpPostRunCom "0000C0000000E000h";
BA_ "FlexKomSigStartPos" SG_ 676 LTActPumpPostRunCom 7;
BA_ "FlexKomSigName" SG_ 676 LTActPumpPostRunCom "HCP_DriverInfo";
BA_ "FlexKomSigLaenge" SG_ 676 LTActPumpPostRunCom 64;
BA_ "FlexKomSID" SG_ 676 LTActPumpPostRunCom 2130708643;
BA_ "FlexKomIsMotorola" SG_ 676 LTActPumpPostRunCom 1;
BA_ "FlexKomComment" SG_ 676 LTActPumpPostRunCom ".";
BA_ "GenSigSNA" SG_ 676 RadFanSts "7Fh";
BA_ "GenSigCycleTime" SG_ 676 RadFanSts 100;
BA_ "FlexKomSigStartValue" SG_ 676 RadFanSts "0000C0000000E000h";
BA_ "FlexKomSigStartPos" SG_ 676 RadFanSts 7;
BA_ "FlexKomSigName" SG_ 676 RadFanSts "HCP_DriverInfo";
BA_ "FlexKomSigLaenge" SG_ 676 RadFanSts 64;
BA_ "FlexKomSID" SG_ 676 RadFanSts 2130708643;
BA_ "FlexKomIsMotorola" SG_ 676 RadFanSts 1;
BA_ "FlexKomComment" SG_ 676 RadFanSts ".";
BA_ "RID" SG_ 978 ChargeReq "4465";
BA_ "GenSigStartValue" SG_ 978 ChargeReq 1;
BA_ "GenSigSNA" SG_ 978 ChargeReq "1h";
BA_ "GenSigCycleTime" SG_ 978 ChargeReq 1000;
BA_ "FlexKomSigStartValue" SG_ 978 ChargeReq "FF7FFFFFFF0000D8h";
BA_ "FlexKomSigStartPos" SG_ 978 ChargeReq 7;
BA_ "FlexKomSigName" SG_ 978 ChargeReq "HCP_GW_1000";
BA_ "FlexKomSigLaenge" SG_ 978 ChargeReq 64;
BA_ "FlexKomSID" SG_ 978 ChargeReq 2130708645;
BA_ "FlexKomIsMotorola" SG_ 978 ChargeReq 1;
BA_ "FlexKomComment" SG_ 978 ChargeReq ".";
BA_ "RID" SG_ 978 ODO "2112";
BA_ "GenSigStartValue" SG_ 978 ODO 16777215;
BA_ "GenSigSNA" SG_ 978 ODO "FFFFFFh";
BA_ "GenSigCycleTime" SG_ 978 ODO 1000;
BA_ "FlexKomSigStartValue" SG_ 978 ODO "FF7FFFFFFF0000D8h";
BA_ "FlexKomSigStartPos" SG_ 978 ODO 7;
BA_ "FlexKomSigName" SG_ 978 ODO "HCP_GW_1000";
BA_ "FlexKomSigLaenge" SG_ 978 ODO 64;
BA_ "FlexKomSID" SG_ 978 ODO 2130708645;
BA_ "FlexKomIsMotorola" SG_ 978 ODO 1;
BA_ "FlexKomComment" SG_ 978 ODO ".";
BA_ "RID" SG_ 978 SHIP_STAT "5080";
BA_ "GenSigStartValue" SG_ 978 SHIP_STAT 3;
BA_ "GenSigSNA" SG_ 978 SHIP_STAT "3h";
BA_ "GenSigCycleTime" SG_ 978 SHIP_STAT 1000;
BA_ "FlexKomSigStartValue" SG_ 978 SHIP_STAT "FF7FFFFFFF0000D8h";
BA_ "FlexKomSigStartPos" SG_ 978 SHIP_STAT 7;
BA_ "FlexKomSigName" SG_ 978 SHIP_STAT "HCP_GW_1000";
BA_ "FlexKomSigLaenge" SG_ 978 SHIP_STAT 64;
BA_ "FlexKomSID" SG_ 978 SHIP_STAT 2130708645;
BA_ "FlexKomIsMotorola" SG_ 978 SHIP_STAT 1;
BA_ "FlexKomComment" SG_ 978 SHIP_STAT ".";
BA_ "GenSigStartValue" SG_ 530 CRC_VEH_SPEED 255;
BA_ "GenSigSNA" SG_ 530 CRC_VEH_SPEED "FFh";
BA_ "GenSigCycleTime" SG_ 530 CRC_VEH_SPEED 20;
BA_ "FlexKomSigStartValue" SG_ 530 CRC_VEH_SPEED "00000000FFFF00FFh";
BA_ "FlexKomSigStartPos" SG_ 530 CRC_VEH_SPEED 7;
BA_ "FlexKomSigName" SG_ 530 CRC_VEH_SPEED "HCP_GW_20";
BA_ "FlexKomSigLaenge" SG_ 530 CRC_VEH_SPEED 64;
BA_ "FlexKomSID" SG_ 530 CRC_VEH_SPEED 2130708646;
BA_ "FlexKomIsMotorola" SG_ 530 CRC_VEH_SPEED 1;
BA_ "FlexKomComment" SG_ 530 CRC_VEH_SPEED ".";
BA_ "RID" SG_ 530 CmdIgnStat "2107";
BA_ "GenSigSNA" SG_ 530 CmdIgnStat "7h";
BA_ "GenSigCycleTime" SG_ 530 CmdIgnStat 20;
BA_ "FlexKomSigStartValue" SG_ 530 CmdIgnStat "00000000FFFF00FFh";
BA_ "FlexKomSigStartPos" SG_ 530 CmdIgnStat 7;
BA_ "FlexKomSigName" SG_ 530 CmdIgnStat "HCP_GW_20";
BA_ "FlexKomSigLaenge" SG_ 530 CmdIgnStat 64;
BA_ "FlexKomSID" SG_ 530 CmdIgnStat 2130708646;
BA_ "FlexKomIsMotorola" SG_ 530 CmdIgnStat 1;
BA_ "FlexKomComment" SG_ 530 CmdIgnStat ".";
BA_ "RID" SG_ 530 KeyInIgn "2111";
BA_ "GenSigSNA" SG_ 530 KeyInIgn "3h";
BA_ "GenSigCycleTime" SG_ 530 KeyInIgn 20;
BA_ "FlexKomSigStartValue" SG_ 530 KeyInIgn "00000000FFFF00FFh";
BA_ "FlexKomSigStartPos" SG_ 530 KeyInIgn 7;
BA_ "FlexKomSigName" SG_ 530 KeyInIgn "HCP_GW_20";
BA_ "FlexKomSigLaenge" SG_ 530 KeyInIgn 64;
BA_ "FlexKomSID" SG_ 530 KeyInIgn 2130708646;
BA_ "FlexKomIsMotorola" SG_ 530 KeyInIgn 1;
BA_ "FlexKomComment" SG_ 530 KeyInIgn ".";
BA_ "GenSigSNA" SG_ 530 MC_VEH_SPEED "0h";
BA_ "GenSigCycleTime" SG_ 530 MC_VEH_SPEED 20;
BA_ "FlexKomSigStartValue" SG_ 530 MC_VEH_SPEED "00000000FFFF00FFh";
BA_ "FlexKomSigStartPos" SG_ 530 MC_VEH_SPEED 7;
BA_ "FlexKomSigName" SG_ 530 MC_VEH_SPEED "HCP_GW_20";
BA_ "FlexKomSigLaenge" SG_ 530 MC_VEH_SPEED 64;
BA_ "FlexKomSID" SG_ 530 MC_VEH_SPEED 2130708646;
BA_ "FlexKomIsMotorola" SG_ 530 MC_VEH_SPEED 1;
BA_ "FlexKomComment" SG_ 530 MC_VEH_SPEED ".";
BA_ "RID" SG_ 530 RemStActv "2116";
BA_ "GenSigSNA" SG_ 530 RemStActv "0h";
BA_ "GenSigCycleTime" SG_ 530 RemStActv 20;
BA_ "FlexKomSigStartValue" SG_ 530 RemStActv "00000000FFFF00FFh";
BA_ "FlexKomSigStartPos" SG_ 530 RemStActv 7;
BA_ "FlexKomSigName" SG_ 530 RemStActv "HCP_GW_20";
BA_ "FlexKomSigLaenge" SG_ 530 RemStActv 64;
BA_ "FlexKomSID" SG_ 530 RemStActv 2130708646;
BA_ "FlexKomIsMotorola" SG_ 530 RemStActv 1;
BA_ "FlexKomComment" SG_ 530 RemStActv ".";
BA_ "RID" SG_ 530 VEH_SPEED "2863";
BA_ "GenSigStartValue" SG_ 530 VEH_SPEED 65535;
BA_ "GenSigSNA" SG_ 530 VEH_SPEED "FFFFh";
BA_ "GenSigCycleTime" SG_ 530 VEH_SPEED 20;
BA_ "FlexKomSigStartValue" SG_ 530 VEH_SPEED "00000000FFFF00FFh";
BA_ "FlexKomSigStartPos" SG_ 530 VEH_SPEED 7;
BA_ "FlexKomSigName" SG_ 530 VEH_SPEED "HCP_GW_20";
BA_ "FlexKomSigLaenge" SG_ 530 VEH_SPEED 64;
BA_ "FlexKomSID" SG_ 530 VEH_SPEED 2130708646;
BA_ "FlexKomIsMotorola" SG_ 530 VEH_SPEED 1;
BA_ "FlexKomComment" SG_ 530 VEH_SPEED ".";
VAL_ 792 CompBoardTemp 255 "SNA" ;
VAL_ 792 CompBoardTempV 0 "Valid" 1 "Not_Valid" ;
VAL_ 792 CompHVInput 255 "SNA" ;
VAL_ 792 CompHVInputV 0 "Valid" 1 "Not_Valid" ;
VAL_ 792 CompIGBTTemp 255 "SNA" ;
VAL_ 792 CompIGBTTempV 0 "Valid" 1 "Not_Valid" ;
VAL_ 256 ExtReqStatus 0 "EBR_NotInitialized" 1 "EBR_NotAvailable" 2 "EBR_Available" 3 "EBR_Active" ;
VAL_ 256 MC_100h 15 "SNA" ;
VAL_ 256 OutputRodAct_Qualifier 0 "NotInitialized" 1 "Normal" 2 "Faulty" ;
VAL_ 256 sOutputRodAct 4095 "SNA" ;
VAL_ 256 sOutputRodTarget 4095 "SNA" ;
VAL_ 256 sOutputRod_Qualifier 0 "NotInitialized" 1 "Normal" 2 "Faulty" ;
VAL_ 514 iBStatus 0 "iBooster_NotInitialized" 1 "iBooster_Failure_iBoosterOff" 2 "iBooster_Diagnosis" 3 "Undefine" 4 "iBooster_Alone" 5 "iBooster_Reduced" 6 "iBooster_PostRun_Reduced" 7 "iBooster_Ready" ;
VAL_ 514 pForceBlendingReserve_V 0 "NotInitialized" 1 "Normal" 2 "Faulty" ;
VAL_ 514 pRunout_V 0 "NotInitialized" 1 "Normal" 2 "Faulty" ;
VAL_ 653 BrakePedalTravelSensor 255 "SNA" ;
VAL_ 653 BrakeSysStateSec 0 "BrkSysSec_Off" 1 "BrkSysSec_Unavailable" 2 "BrkSysSec_FailedDegraded" 3 "BrkSysSec_FailedOperational" 4 "BrkSysSec_FullSystem" 5 "BrkSysSec_EmergencyMode" 7 "SNA" ;
VAL_ 653 BrkPdl_Stat_2 0 "UPSTOP" 1 "PSD" 2 "NDEF2" 3 "SNA" ;
VAL_ 653 Brk_Stat_2 0 "IDLE" 1 "BRAKING" 2 "NDEF2" 3 "SNA" ;
VAL_ 653 DAS_RqActv 0 "IDLE" 1 "LFC" 2 "CMS" 3 "ABA" 4 "LSCM" 5 "VJC_Open_Loop" 6 "RHSC_Override" 7 "SNA" ;
VAL_ 653 EBCM_BrakeState 0 "EBCM_Off" 1 "EBCM_Unavailable" 2 "EBCM_FailedDegraded" 3 "EBCM_FailedOperational" 4 "EBCM_FullSystem" 5 "EBCM_EmergencyMode" 7 "SNA" ;
VAL_ 653 SDS_Engaged_State_EBCM 0 "Disengaged" 1 "Engaged_with_Driver" 2 "Engaged_Driverless" 3 "SNA" ;
VAL_ 259 ForceBlendingActive 0 "PFCstate_Inactive" 1 "PFCstate_Hold" 2 "PFCstate_Active" ;
VAL_ 259 MC_ESC_10 15 "SNA" ;
VAL_ 259 pMCVirtual_Qualifier 0 "TDQNotInitialized" 1 "TDQNormal" 2 "TDQReducedMonitoring" 3 "TDQ_Faulty" ;
VAL_ 516 ShiftInhibit 0 "NO_ACT" 1 "IDS" 2 "IUS" 3 "SI" ;
VAL_ 320 BrkPdl_Stat 0 "UPSTOP" 1 "PSD" 2 "NDEF2" 3 "SNA" ;
VAL_ 320 Brk_Stat 0 "IDLE" 1 "BRAKING" 2 "NDEF2" 3 "SNA" ;
VAL_ 268 DAS_RqActv 0 "IDLE" 1 "LFC" 2 "CMS" 3 "ABA" 4 "LSCM" 5 "VJC_Open_Loop" 6 "RHSC_Override" 7 "SNA" ;
VAL_ 292 WhlPlsCnt_FL 255 "SNA" ;
VAL_ 292 WhlPlsCnt_FR 255 "SNA" ;
VAL_ 292 WhlPlsCnt_RL 255 "SNA" ;
VAL_ 292 WhlPlsCnt_RR 255 "SNA" ;
VAL_ 344 WhlDir_FL_Stat 0 "VOID" 1 "FORWARD" 2 "BACKWARD" 3 "SNA" ;
VAL_ 344 WhlDir_FR_Stat 0 "VOID" 1 "FORWARD" 2 "BACKWARD" 3 "SNA" ;
VAL_ 344 WhlDir_RL_Stat 0 "VOID" 1 "FORWARD" 2 "BACKWARD" 3 "SNA" ;
VAL_ 344 WhlDir_RR_Stat 0 "VOID" 1 "FORWARD" 2 "BACKWARD" 3 "SNA" ;
VAL_ 344 WhlRPM_FL 16383 "SNA" ;
VAL_ 344 WhlRPM_FR 16383 "SNA" ;
VAL_ 344 WhlRPM_RL 16383 "SNA" ;
VAL_ 344 WhlRPM_RR 16383 "SNA" ;
VAL_ 682 BrakeSysStatePrim 0 "BrkSysPrim_Off" 1 "BrkSysPrim_Unavailable" 2 "BrkSysPrim_FailedDegraded" 3 "BrkSysPrim_FailedOperational" 4 "BrkSysPrim_FullSystem" 5 "BrkSysPrim_EmergencyMode" 7 "SNA" ;
VAL_ 682 ESC_BrakeState 0 "ESC_Off" 1 "ESC_Unavailable" 2 "ESC_FailedDegraded" 3 "ESC_FailedOperational" 4 "ESC_FullSystem" 5 "ESC_EmergencyMode" 7 "SNA" ;
VAL_ 682 SDS_Engaged_State_ESC 0 "Disengaged" 1 "Engaged_with_Driver" 2 "Engaged_Driverless" 3 "SNA" ;
VAL_ 682 qTargetExternal_Active 0 "qTarget_Off" 1 "qTarget_EBR" 2 "qTarget_EBRmaxPerformance" ;
VAL_ 402 ECMReq_Remedial_Stop 0 "DEFAULT" 1 "Remedial_Stp_Req" 2 "Remedial_Stp_Req_w_Limp" 3 "SNA" ;
VAL_ 402 ETRQ_Mode 7 "SNA" ;
VAL_ 402 EVRDesVSetP 255 "SNA" ;
VAL_ 402 EngManfldAbsPrsV 0 "Valid" 1 "Not_Valid" ;
VAL_ 402 EngRqStTyp 0 "N_RQ" 1 "KS_NORM" 2 "KS_LP" 3 "KS_LPB" 4 "KS_GEN" 5 "AS_SM" 6 "AS_NORM" 7 "AS_AGG" 8 "AS_GEN" 9 "CT" 15 "SNA" ;
VAL_ 400 ESS_Engine_State_EE 1 "ENS_STOPPED" 2 "ENS_RQ_ST" 3 "ENS_RUN" 4 "ENS_STOP_PEND" 5 "ENS_ST_PRTCT" 6 "ENS_ST_INH" 7 "ENS_DSBL" 8 "ENS_IHB_LATCH" 9 "ENS_ST" 10 "KEY_START" 11 "CHANGED_MIND" 12 "KEY_TORQUE_START" 15 "SNA" ;
VAL_ 400 EngActuatorsStat 0 "ACPP" 1 "SCPP" 2 "ACPA" ;
VAL_ 400 EngCylDeactMd 0 "CYL_ACT" 1 "DAP" 2 "HTCA" 3 "RAP" ;
VAL_ 400 EngTrqReserveReq 255 "SNA" ;
VAL_ 400 PT_BrkPedDscrtInpStatV 0 "Valid" 1 "Not_Valid" ;
VAL_ 400 T_max_raw 16383 "SNA" ;
VAL_ 400 T_min_raw 16383 "SNA" ;
VAL_ 771 AGSposn 127 "SNA" ;
VAL_ 771 EngOffTmPT 0 "SNA" ;
VAL_ 771 EngOffTmPTV 1 "SNA" ;
VAL_ 771 EstCatCnvTmp 255 "SNA" ;
VAL_ 771 RadFanReq 127 "SNA" ;
VAL_ 396 ECM_HoodAjar 0 "Closed" 1 "Ajar" 2 "Faulted" 3 "Indetermine (SNA)" ;
VAL_ 396 EngHalfCylSpdMaxLim 8191 "SNA" ;
VAL_ 396 EngHalfCylSpdMinLim 8191 "SNA" ;
VAL_ 770 BarPrsAbsV 0 "Valid" 1 "Not_Valid" ;
VAL_ 770 EngCltTmp 255 "SNA" ;
VAL_ 770 EngCltTmpV 0 "Valid" 1 "Not_Valid" ;
VAL_ 770 EngIntAirTmp 255 "SNA" ;
VAL_ 770 EngIntAirTmpV 0 "Valid" 1 "Not_Valid" ;
VAL_ 770 EngSpdStat 0 "NOR_OPR" 1 "DEG_OPR" 3 "SNA" ;
VAL_ 770 OAT_PT_EstV 0 "Valid" 1 "Not_Valid" ;
VAL_ 849 EngTorqACCCapability 255 "SNA" ;
VAL_ 849 EngTorqCapbltyMaxTorq 4095 "SNA" ;
VAL_ 849 EngTorqCapbltyMinRunTorq 4095 "SNA" ;
VAL_ 849 EngTorqCapbltyMinTorq 4095 "SNA" ;
VAL_ 395 MaxPrdtdEngTorqCap 4095 "SNA" ;
VAL_ 395 MaxPrdtdEngTorqCapV 0 "Valid" 1 "Not_Valid" ;
VAL_ 395 MinEngTorqCap 4095 "SNA" ;
VAL_ 395 MinEngTorqCapV 0 "Valid" 1 "Not_Valid" ;
VAL_ 395 MinImmedEngTorqCap 4095 "SNA" ;
VAL_ 395 MinImmedEngTorqCapV 0 "Valid" 1 "Not_Valid" ;
VAL_ 395 MinPrdtdEngRunTorqCap 4095 "SNA" ;
VAL_ 395 MinPrdtdEngRunTorqCapV 0 "Valid" 1 "Not_Valid" ;
VAL_ 401 AccPosV 0 "Valid" 1 "Not_Valid" ;
VAL_ 401 ECM_IMMO_STAT_CANePT 0 "IS" 1 "KILL" 2 "RUN" 3 "SNA" ;
VAL_ 401 EngActStdyStTorq 4095 "SNA" ;
VAL_ 401 EngActStdyStTorqV 0 "Valid" 1 "Not_Valid" ;
VAL_ 401 EngAirFlwStdyStTorq 4095 "SNA" ;
VAL_ 401 EngAirFlwStdyStTorqV 0 "Valid" 1 "Not_Valid" ;
VAL_ 401 HybActEngTorqRespTyp 0 "Inactive" 1 "Pleasability_Limited" 2 "Maximum_Range" ;
VAL_ 908 GPS_Date_Day 255 "SNA" ;
VAL_ 908 GPS_Date_Month 255 "SNA" ;
VAL_ 908 GPS_Date_Year 65535 "SNA" ;
VAL_ 908 GPS_UTC_Hour 255 "SNA" ;
VAL_ 908 GPS_UTC_Minute 255 "SNA" ;
VAL_ 908 GPS_UTC_Second 65535 "SNA" ;
VAL_ 564 APM_IdcHvSetP 255 "SNA" ;
VAL_ 564 APM_IdcLvSetP 511 "SNA" ;
VAL_ 564 APM_OperModeEnable 0 "Default" 1 "Buck_CV" 2 "Buck_CC" 3 "Buck_CP" 4 "Buck_Special" 5 "Boost" 6 "Precharge" 7 "Discharge" 8 "Off" 15 "SNA" ;
VAL_ 564 APM_VdcHvSetP 511 "SNA" ;
VAL_ 564 APM_VdcLvAct 511 "SNA" ;
VAL_ 564 APM_VdcLvSetP 255 "SNA" ;
VAL_ 977 ChargingLevel 0 "Default_NoLevel" 1 "Level_1_AC" 2 "Level_2_AC" 3 "Level_3_AC" 4 "Level_1_DC" 5 "Level_2_DC" 6 "PlugInNotDet" 7 "PPI_1_No_Drive" 8 "PPI_2_OK_Drive" 15 "SNA" ;
VAL_ 977 ChargingSysSts 0 "NotCharging" 1 "Charging" 2 "ChargeInterrupted" 3 "ChargeComplete" 7 "SNA" ;
VAL_ 977 ChrgSysFault_Reason 1 "Failure1" 2 "Failure2" 3 "Failure3" 4 "Failure4" 5 "Failure5" 6 "Failure6" 7 "Failure7" 8 "Failure8" 9 "Failure9" 10 "Failure10" 11 "Failure11" 12 "Failure12" 13 "Failure13" 14 "Failure14" 15 "Failure15" 16 "Failure16" 17 "Failure17" 18 "Failure18" 19 "Failure19" 20 "Failure20" 21 "Failure21" 22 "Failure22" 23 "Failure23" 24 "Failure24" 25 "Failure25" 26 "Failure26" 27 "Failure27" 28 "Failure28" 29 "Failure29" 30 "Failure30" 31 "Failure31" 32 "Failure32" 33 "Failure33" 62 "Failure62" 63 "SNA" ;
VAL_ 676 AirFlowReq 127 "SNA" ;
VAL_ 676 CompSpdReq 16383 "SNA" ;
VAL_ 676 LTActPumpCmd 255 "SNA" ;
VAL_ 676 LTActPumpFailsafe_ACT 0 "FALSE" 1 "TRUE" 3 "SNA" ;
VAL_ 676 LTActPumpPostRunCom 0 "NO_POST_RUNNING" 1 "PR_1x" 2 "PR_1y" 3 "PR_2x" 4 "PR_2y" 5 "PR_3x" 6 "PR_3y" 7 "SNA" ;
VAL_ 676 RadFanSts 127 "SNA" ;
VAL_ 978 ODO 16777215 "SNA" ;
VAL_ 978 SHIP_STAT 0 "CUST_MD" 1 "ABBRV_MD" 2 "SHIP_MD" 3 "NOT_PROG" ;
VAL_ 530 CmdIgnStat 0 "IGN_LK" 3 "IGN_OFF_ACC" 4 "IGN_RUN" 5 "IGN_START" 7 "SNA" ;
VAL_ 530 KeyInIgn 0 "KEY_DEF" 1 "KEY_NOT_IN_IGN" 2 "KEY_IN_IGN" 3 "SNA" ;
VAL_ 530 VEH_SPEED 65535 "SNA" ;
